VERSION "AEE2010_4.35_HS2"

NS_ :

BS_:

BU_: AVAS RITCS PASS_HCU2 BVN EBB PASS_VCU BSI AAS PASS_BSI FAMILLE_DSG BV CAPT_ALG CAPT_VOL CMM CSS FSE OUTIL_DIAG PROJ SBW SCDT SUSP UC_DIRA UC_FREIN ASR ARTIV PASS_BSM CMF HCU1 HCU2 ECR MCM

BO_ 146 HS2_INTE_ELECTRON_BSI_092: 1 BSI
 SG_ EFFAC_DEFAUT_DIAG : 0|1@0+ (1,0) [0|0] ""  BVN,ARTIV,EBB,AVAS
 SG_ DIAG_INTEGRA_ELEC : 7|1@0+ (1,0) [0|0] ""  BVN,ARTIV,EBB,AVAS
 SG_ MODE_DIAG : 6|1@0+ (1,0) [0|0] ""  BVN,ARTIV,EBB,AVAS

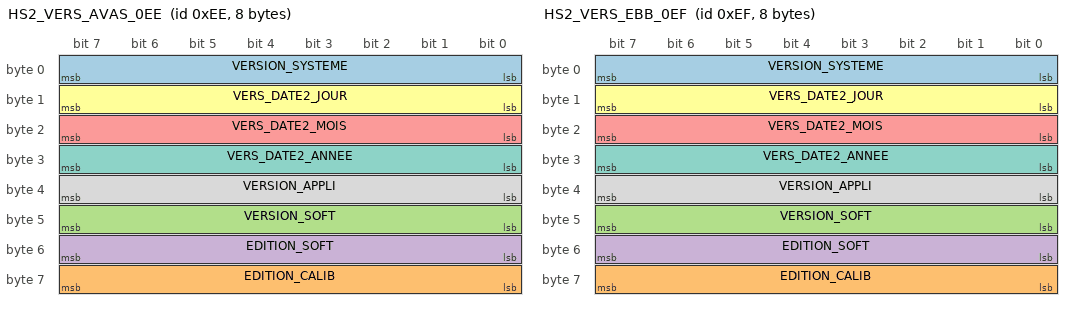
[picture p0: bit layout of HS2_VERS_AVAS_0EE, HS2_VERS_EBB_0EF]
BO_ 238 HS2_VERS_AVAS_0EE: 8 AVAS
 SG_ VERSION_SYSTEME : 7|8@0+ (1,0) [0|255] "" Vector__XXX
 SG_ EDITION_CALIB : 63|8@0+ (1,0) [0|255] "" Vector__XXX
 SG_ VERSION_SOFT : 47|8@0+ (1,0) [0|255] "" Vector__XXX
 SG_ EDITION_SOFT : 55|8@0+ (1,0) [0|255] "" Vector__XXX
 SG_ VERS_DATE2_MOIS : 23|8@0+ (1,0) [0|12] "" Vector__XXX
 SG_ VERS_DATE2_JOUR : 15|8@0+ (1,0) [0|31] "" Vector__XXX
 SG_ VERS_DATE2_ANNEE : 31|8@0+ (1,0) [0|99] "" Vector__XXX
 SG_ VERSION_APPLI : 39|8@0+ (1,0) [0|255] "" Vector__XXX

BO_ 239 HS2_VERS_EBB_0EF: 8 EBB
 SG_ VERSION_SYSTEME : 7|8@0+ (1,0) [0|255] "" Vector__XXX
 SG_ EDITION_CALIB : 63|8@0+ (1,0) [0|255] "" Vector__XXX
 SG_ VERSION_SOFT : 47|8@0+ (1,0) [0|255] "" Vector__XXX
 SG_ EDITION_SOFT : 55|8@0+ (1,0) [0|255] "" Vector__XXX
 SG_ VERS_DATE2_MOIS : 23|8@0+ (1,0) [0|12] "" Vector__XXX
 SG_ VERS_DATE2_JOUR : 15|8@0+ (1,0) [0|31] "" Vector__XXX
 SG_ VERS_DATE2_ANNEE : 31|8@0+ (1,0) [0|99] "" Vector__XXX
 SG_ VERSION_APPLI : 39|8@0+ (1,0) [0|255] "" Vector__XXX

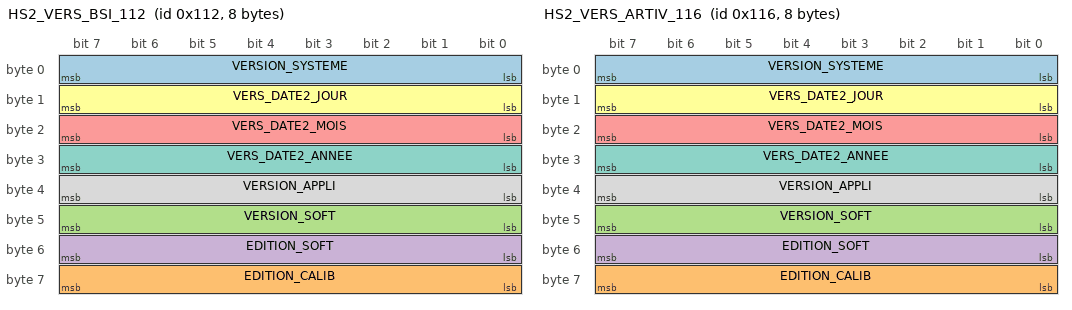
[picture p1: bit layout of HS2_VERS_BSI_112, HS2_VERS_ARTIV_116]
BO_ 274 HS2_VERS_BSI_112: 8 BSI
 SG_ VERSION_SYSTEME : 7|8@0+ (1,0) [0|255] "" Vector__XXX
 SG_ EDITION_CALIB : 63|8@0+ (1,0) [0|255] "" Vector__XXX
 SG_ VERSION_SOFT : 47|8@0+ (1,0) [0|255] "" Vector__XXX
 SG_ EDITION_SOFT : 55|8@0+ (1,0) [0|255] "" Vector__XXX
 SG_ VERS_DATE2_MOIS : 23|8@0+ (1,0) [0|12] "" Vector__XXX
 SG_ VERS_DATE2_JOUR : 15|8@0+ (1,0) [0|31] "" Vector__XXX
 SG_ VERS_DATE2_ANNEE : 31|8@0+ (1,0) [0|99] "" Vector__XXX
 SG_ VERSION_APPLI : 39|8@0+ (1,0) [0|255] "" Vector__XXX

BO_ 278 HS2_VERS_ARTIV_116: 8 ARTIV
 SG_ VERSION_SYSTEME : 7|8@0+ (1,0) [0|255] "" Vector__XXX
 SG_ EDITION_CALIB : 63|8@0+ (1,0) [0|255] "" Vector__XXX
 SG_ VERSION_SOFT : 47|8@0+ (1,0) [0|255] "" Vector__XXX
 SG_ EDITION_SOFT : 55|8@0+ (1,0) [0|255] "" Vector__XXX
 SG_ VERS_DATE2_MOIS : 23|8@0+ (1,0) [0|12] "" Vector__XXX
 SG_ VERS_DATE2_JOUR : 15|8@0+ (1,0) [0|31] "" Vector__XXX
 SG_ VERS_DATE2_ANNEE : 31|8@0+ (1,0) [0|99] "" Vector__XXX
 SG_ VERSION_APPLI : 39|8@0+ (1,0) [0|255] "" Vector__XXX

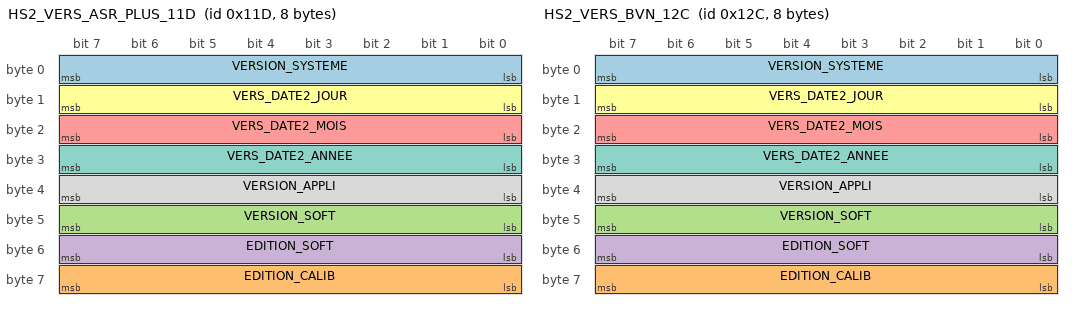
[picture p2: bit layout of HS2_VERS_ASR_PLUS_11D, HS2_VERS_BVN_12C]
BO_ 285 HS2_VERS_ASR_PLUS_11D: 8 MCM
 SG_ VERSION_SYSTEME : 7|8@0+ (1,0) [0|255] "" Vector__XXX
 SG_ EDITION_CALIB : 63|8@0+ (1,0) [0|255] "" Vector__XXX
 SG_ VERSION_SOFT : 47|8@0+ (1,0) [0|255] "" Vector__XXX
 SG_ EDITION_SOFT : 55|8@0+ (1,0) [0|255] "" Vector__XXX
 SG_ VERS_DATE2_MOIS : 23|8@0+ (1,0) [0|12] "" Vector__XXX
 SG_ VERS_DATE2_JOUR : 15|8@0+ (1,0) [0|31] "" Vector__XXX
 SG_ VERS_DATE2_ANNEE : 31|8@0+ (1,0) [0|99] "" Vector__XXX
 SG_ VERSION_APPLI : 39|8@0+ (1,0) [0|255] "" Vector__XXX

BO_ 300 HS2_VERS_BVN_12C: 8 BVN
 SG_ VERSION_SYSTEME : 7|8@0+ (1,0) [0|255] "" Vector__XXX
 SG_ EDITION_CALIB : 63|8@0+ (1,0) [0|255] "" Vector__XXX
 SG_ VERSION_SOFT : 47|8@0+ (1,0) [0|255] "" Vector__XXX
 SG_ EDITION_SOFT : 55|8@0+ (1,0) [0|255] "" Vector__XXX
 SG_ VERS_DATE2_MOIS : 23|8@0+ (1,0) [0|12] "" Vector__XXX
 SG_ VERS_DATE2_JOUR : 15|8@0+ (1,0) [0|31] "" Vector__XXX
 SG_ VERS_DATE2_ANNEE : 31|8@0+ (1,0) [0|99] "" Vector__XXX
 SG_ VERSION_APPLI : 39|8@0+ (1,0) [0|255] "" Vector__XXX

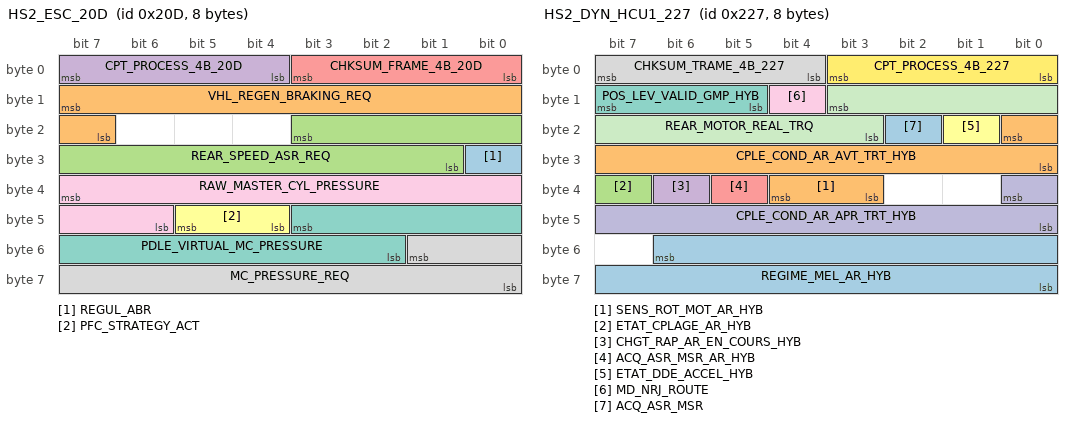
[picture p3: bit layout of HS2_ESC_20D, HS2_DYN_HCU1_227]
BO_ 525 HS2_ESC_20D: 8 UC_FREIN
 SG_ REGUL_ABR : 24|1@0+ (1,0) [0|0] ""  EBB,CMM
 SG_ VHL_REGEN_BRAKING_REQ : 15|9@0+ (1,-2500) [-2500|0] "N.m"  EBB,CMM
 SG_ REAR_SPEED_ASR_REQ : 19|11@0+ (1,10) [0|18000] "tr/min"  EBB,CMM
 SG_ CPT_PROCESS_4B_20D : 7|4@0+ (1,0) [0|15] ""  EBB,CMM
 SG_ CHKSUM_FRAME_4B_20D : 3|4@0+ (1,0) [0|0] ""  EBB,CMM
 SG_ PFC_STRATEGY_ACT : 45|2@0+ (1,0) [0|0] ""  EBB,CMM
 SG_ PDLE_VIRTUAL_MC_PRESSURE : 43|10@0+ (0.25,0) [0|250] "bar"  EBB,CMM
 SG_ MC_PRESSURE_REQ : 49|10@0+ (0.25,0) [0|250] "bar"  EBB,CMM
 SG_ RAW_MASTER_CYL_PRESSURE : 39|10@0+ (0.3,-30) [-30|276.3] "bar"  EBB,CMM

BO_ 551 HS2_DYN_HCU1_227: 8 PASS_HCU2
 SG_ REGIME_MEL_AR_HYB : 54|15@0+ (1,-16000) [-16000|16000] "tr/min"  BSI,UC_FREIN
 SG_ SENS_ROT_MOT_AR_HYB : 36|2@0+ (1,0) [0|0] ""  BSI,UC_FREIN
 SG_ ETAT_CPLAGE_AR_HYB : 39|1@0+ (1,0) [0|0] ""  BSI,UC_FREIN
 SG_ CHGT_RAP_AR_EN_COURS_HYB : 38|1@0+ (1,0) [0|0] ""  BSI,UC_FREIN
 SG_ ACQ_ASR_MSR_AR_HYB : 37|1@0+ (1,0) [0|0] ""  BSI,UC_FREIN
 SG_ ETAT_DDE_ACCEL_HYB : 17|1@0+ (1,0) [0|0] ""  BSI,UC_FREIN
 SG_ POS_LEV_VALID_GMP_HYB : 15|3@0+ (1,0) [0|0] ""  BSI,UC_FREIN
 SG_ CHKSUM_TRAME_4B_227 : 7|4@0+ (1,0) [0|0] ""  BSI,UC_FREIN
 SG_ MD_NRJ_ROUTE : 12|1@0+ (1,0) [0|0] ""  BSI,UC_FREIN
 SG_ CPLE_COND_AR_APR_TRT_HYB : 32|9@0+ (2,-500) [-500|500] "N.m"  BSI,UC_FREIN
 SG_ REAR_MOTOR_REAL_TRQ : 11|9@0- (2,0) [-250|250] "N.m"  BSI,UC_FREIN
 SG_ CPT_PROCESS_4B_227 : 3|4@0+ (1,0) [0|15] ""  BSI,UC_FREIN
 SG_ ACQ_ASR_MSR : 18|1@0+ (1,0) [0|0] ""  BSI,UC_FREIN
 SG_ CPLE_COND_AR_AVT_TRT_HYB : 16|9@0+ (2,-500) [-500|500] "N.m"  BSI,UC_FREIN

BO_ 552 HS2_BGE_DYN5_CMM_228: 8 PASS_BSI
 SG_ PRESS_MASTERV_2_HYB : 47|8@0+ (5,0) [0|1200] "hPa"  CMF,RITCS,UC_FREIN,BV,ARTIV,HCU2
 SG_ IND_ENG_SPD_OVRFLWD : 10|2@0+ (1,0) [0|0] ""  CMF,RITCS,UC_FREIN,BV,ARTIV,HCU2
 SG_ POS_PDLE_EMBR_CMM : 39|8@0+ (0.5,0) [0|100] "%"  CMF,RITCS,UC_FREIN,BV,ARTIV,HCU2
 SG_ POINT_DUR_SECU : 11|1@0+ (1,0) [0|0] ""  CMF,RITCS,UC_FREIN,BV,ARTIV,HCU2
 SG_ CPLE_DISPO_HILL_ASSIST : 12|1@0+ (1,0) [0|0] ""  CMF,RITCS,UC_FREIN,BV,ARTIV,HCU2
 SG_ CHKSUM_TRME_DYN5_CMM : 27|4@0+ (1,0) [0|0] ""  CMF,RITCS,UC_FREIN,BV,ARTIV,HCU2
 SG_ CPLE_MOT_PRECIS : 13|1@0+ (1,0) [0|0] ""  CMF,RITCS,UC_FREIN,BV,ARTIV,HCU2
 SG_ PRESS_MASTER_REL_CMM : 47|8@0+ (5,0) [0|1200] "hPa"  CMF,RITCS,UC_FREIN,BV,ARTIV,HCU2
 SG_ FREEWHEELING_REQ : 55|2@0+ (1,0) [0|0] ""  CMF,RITCS,UC_FREIN,BV,ARTIV,HCU2
 SG_ CPLE_EM_INCERTAIN : 15|2@0+ (1,0) [0|0] ""  CMF,RITCS,UC_FREIN,BV,ARTIV,HCU2
 SG_ EFCMNT_PDLE_ACCEL : 23|8@0+ (0.5,0) [0|100] "%"  CMF,RITCS,UC_FREIN,BV,ARTIV,HCU2
 SG_ CPT_PROCESS_4B_228 : 31|4@0+ (1,0) [0|15] ""  CMF,RITCS,UC_FREIN,BV,ARTIV,HCU2
 SG_ AUTORISATION_RDT : 53|1@0+ (1,0) [0|0] ""  CMF,RITCS,UC_FREIN,BV,ARTIV,HCU2
 SG_ CPLE_POT_MAX_INST : 63|8@0+ (2,-100) [-100|408] "N.m"  CMF,RITCS,UC_FREIN,BV,ARTIV,HCU2
 SG_ INFO_CPLE_EASY_MOVE : 7|8@0+ (2,-100) [-100|408] "N.m"  CMF,RITCS,UC_FREIN,BV,ARTIV,HCU2

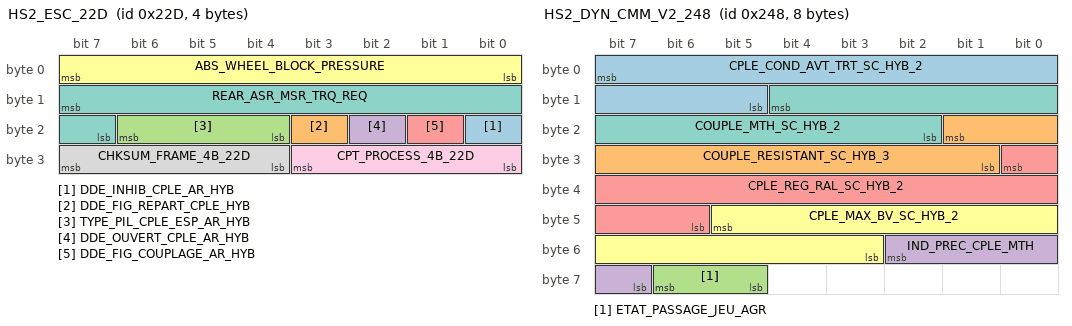
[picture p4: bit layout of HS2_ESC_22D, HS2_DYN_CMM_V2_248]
BO_ 557 HS2_ESC_22D: 4 UC_FREIN
 SG_ DDE_INHIB_CPLE_AR_HYB : 16|1@0+ (1,0) [0|0] ""  CMM,EBB
 SG_ DDE_FIG_REPART_CPLE_HYB : 19|1@0+ (1,0) [0|0] ""  CMM,EBB
 SG_ TYPE_PIL_CPLE_ESP_AR_HYB : 22|3@0+ (1,0) [0|0] ""  CMM,EBB
 SG_ DDE_OUVERT_CPLE_AR_HYB : 18|1@0+ (1,0) [0|0] ""  CMM,EBB
 SG_ DDE_FIG_COUPLAGE_AR_HYB : 17|1@0+ (1,0) [0|0] ""  CMM,EBB
 SG_ ABS_WHEEL_BLOCK_PRESSURE : 7|8@0+ (1,0) [0|250] "bar"  CMM,EBB
 SG_ REAR_ASR_MSR_TRQ_REQ : 15|9@0+ (1,-250) [-250|250] "N.m"  CMM,EBB
 SG_ CHKSUM_FRAME_4B_22D : 31|4@0+ (1,0) [0|0] ""  CMM,EBB
 SG_ CPT_PROCESS_4B_22D : 27|4@0+ (1,0) [0|15] ""  CMM,EBB

BO_ 584 HS2_DYN_CMM_V2_248: 8 CMM
 SG_ CPLE_COND_AVT_TRT_SC_HYB_2 : 7|11@0+ (0.5,-500) [-500|500] "N.m"  UC_FREIN
 SG_ COUPLE_RESISTANT_SC_HYB_3 : 17|9@0+ (0.5,0) [0|255] "N.m"  UC_FREIN
 SG_ ETAT_PASSAGE_JEU_AGR : 62|2@0+ (1,0) [0|0] ""  UC_FREIN
 SG_ IND_PREC_CPLE_MTH : 50|4@0+ (1,0) [1|10] "Sans unité"  UC_FREIN
 SG_ CPLE_REG_RAL_SC_HYB_2 : 24|11@0+ (0.5,-500) [-500|500] "N.m"  UC_FREIN
 SG_ CPLE_MAX_BV_SC_HYB_2 : 45|11@0+ (0.5,-500) [-500|500] "N.m"  UC_FREIN
 SG_ COUPLE_MTH_SC_HYB_2 : 12|11@0+ (0.5,-500) [-500|500] "N.m"  UC_FREIN

BO_ 632 HS2_DYN_CMM_278: 4 CMM
 SG_ CPT_PROCESS_4B_278 : 3|4@0+ (1,0) [0|15] ""  UC_FREIN
 SG_ CHKSUM_TRAME_4B_278 : 7|4@0+ (1,0) [0|0] ""  UC_FREIN
 SG_ FRONT_PWT_REAL_TRQ : 23|9@0- (2,0) [-400|400] "N.m"  UC_FREIN
 SG_ CPLE_REEL_AR_HYB_2 : 15|8@0+ (2,-250) [-250|250] "N.m"  UC_FREIN

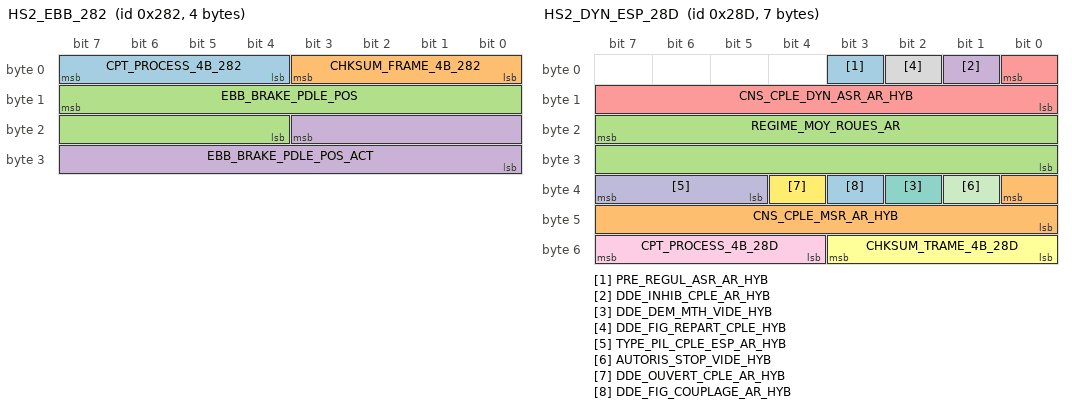
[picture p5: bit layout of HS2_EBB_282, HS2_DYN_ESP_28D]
BO_ 642 HS2_EBB_282: 4 EBB
 SG_ CPT_PROCESS_4B_282 : 7|4@0+ (1,0) [0|15] ""  UC_FREIN
 SG_ CHKSUM_FRAME_4B_282 : 3|4@0+ (1,0) [0|0] ""  UC_FREIN
 SG_ EBB_BRAKE_PDLE_POS : 15|12@0+ (0.015625,-5) [-5|47] "mm"  UC_FREIN
 SG_ EBB_BRAKE_PDLE_POS_ACT : 19|12@0+ (0.015625,-5) [-5|47] "mm"  UC_FREIN

BO_ 653 HS2_DYN_ESP_28D: 7 UC_FREIN
 SG_ PRE_REGUL_ASR_AR_HYB : 3|1@0+ (1,0) [0|0] ""  BSI,HCU2
 SG_ CNS_CPLE_MSR_AR_HYB : 32|9@0+ (2,-500) [-500|500] "N.m"  BSI,HCU2
 SG_ REGIME_MOY_ROUES_AR : 23|16@0+ (0.04,0) [0|2621] "tr/min"  BSI,HCU2
 SG_ DDE_INHIB_CPLE_AR_HYB : 1|1@0+ (1,0) [0|0] ""  BSI,HCU2
 SG_ CNS_CPLE_DYN_ASR_AR_HYB : 0|9@0+ (2,-500) [-500|500] "N.m"  BSI,HCU2
 SG_ CHKSUM_TRAME_4B_28D : 51|4@0+ (1,0) [0|0] ""  BSI,HCU2
 SG_ DDE_DEM_MTH_VIDE_HYB : 34|1@0+ (1,0) [0|0] ""  BSI,HCU2
 SG_ DDE_FIG_REPART_CPLE_HYB : 2|1@0+ (1,0) [0|0] ""  BSI,HCU2
 SG_ CPT_PROCESS_4B_28D : 55|4@0+ (1,0) [0|15] ""  BSI,HCU2
 SG_ TYPE_PIL_CPLE_ESP_AR_HYB : 39|3@0+ (1,0) [0|0] ""  BSI,HCU2
 SG_ AUTORIS_STOP_VIDE_HYB : 33|1@0+ (1,0) [0|0] ""  BSI,HCU2
 SG_ DDE_OUVERT_CPLE_AR_HYB : 36|1@0+ (1,0) [0|0] ""  BSI,HCU2
 SG_ DDE_FIG_COUPLAGE_AR_HYB : 35|1@0+ (1,0) [0|0] ""  BSI,HCU2

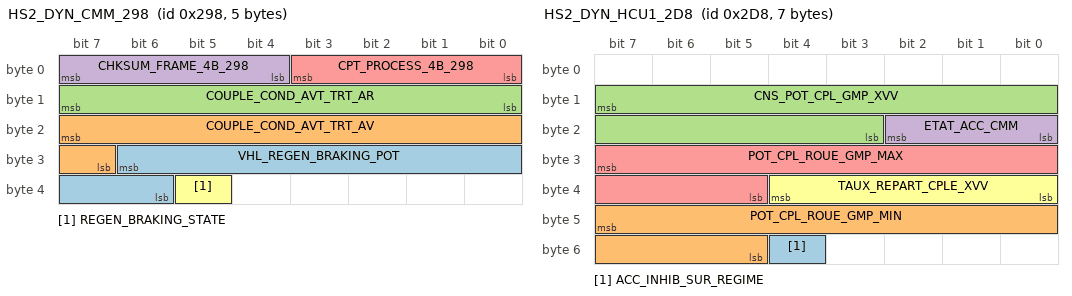
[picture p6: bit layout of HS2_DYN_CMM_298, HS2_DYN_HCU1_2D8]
BO_ 664 HS2_DYN_CMM_298: 5 CMM
 SG_ VHL_REGEN_BRAKING_POT : 30|9@0+ (5,-2500) [-2500|0] "N.m"  UC_FREIN
 SG_ COUPLE_COND_AVT_TRT_AV : 23|9@0+ (2,-400) [-400|400] "N.m"  UC_FREIN
 SG_ COUPLE_COND_AVT_TRT_AR : 15|8@0+ (2,-250) [-250|250] "N.m"  UC_FREIN
 SG_ CHKSUM_FRAME_4B_298 : 7|4@0+ (1,0) [0|0] ""  UC_FREIN
 SG_ CPT_PROCESS_4B_298 : 3|4@0+ (1,0) [0|15] ""  UC_FREIN
 SG_ REGEN_BRAKING_STATE : 37|1@0+ (1,0) [0|0] ""  UC_FREIN

BO_ 690 HS2_DYN2_CMM_2B2: 1 BSI
 SG_ DIAG_MUX_ON : 1|1@0+ (1,0) [0|0] ""  BVN,ARTIV,CAPT_VOL,ECR,CMF,AVAS
 SG_ ETAT_RVV_LVV : 3|2@0+ (1,0) [0|0] ""  BVN,ARTIV,CAPT_VOL,ECR,CMF,AVAS
 SG_ ETAT_MT : 7|4@0+ (1,0) [0|0] ""  BVN,ARTIV,CAPT_VOL,ECR,CMF,AVAS

BO_ 694 HS2_DYN1_MDD_ETAT_2B6: 8 ARTIV
 SG_ DMD_PLT_DECEL_MDD : 53|1@0+ (1,0) [0|0] ""  CMM,UC_FREIN,BSI,PASS_HCU2,CMF
 SG_ TYPE_DECEL_MDD : 52|2@0+ (1,0) [0|0] ""  CMM,UC_FREIN,BSI,PASS_HCU2,CMF
 SG_ CNS_CPLE_ROUE_GMP : 39|14@0+ (1,-4000) [-4000|11000] "N.m"  CMM,UC_FREIN,BSI,PASS_HCU2,CMF
 SG_ DDE_ACT_CPL_ROUE : 41|2@0+ (1,0) [0|0] ""  CMM,UC_FREIN,BSI,PASS_HCU2,CMF
 SG_ CONS_DECEL_MDD : 7|8@0+ (0.05,-10.65) [-10.65|2] "m/s2"  CMM,UC_FREIN,BSI,PASS_HCU2,CMF
 SG_ DDE_PREFILL : 55|1@0+ (1,0) [0|0] ""  CMM,UC_FREIN,BSI,PASS_HCU2,CMF
 SG_ TYPE_RAPPORT M : 54|1@0+ (1,0) [0|0] ""  CMM,UC_FREIN,BSI,PASS_HCU2,CMF
 SG_ CNS_POT_CPL_ROUE_GMP : 23|12@0+ (4,-4000) [-4000|11000] "N.m"  CMM,UC_FREIN,BSI,PASS_HCU2,CMF
 SG_ ETAT_ACC : 27|4@0+ (1,0) [0|0] ""  CMM,UC_FREIN,BSI,PASS_HCU2,CMF
 SG_ TPS_CONF_MIN_RAP_DES m0 : 15|6@0+ (0.1,0) [0|6.2] "s"  CMM,UC_FREIN,BSI,PASS_HCU2,CMF
 SG_ TPS_CONF_MIN_RAP_MON m1 : 15|6@0+ (0.1,0) [0|6.2] "s"  CMM,UC_FREIN,BSI,PASS_HCU2,CMF
 SG_ DDE_ACT_POT_CPL_ROUE : 9|2@0+ (1,0) [0|0] ""  CMM,UC_FREIN,BSI,PASS_HCU2,CMF
 SG_ FA_ETAT_FA : 50|3@0+ (1,0) [0|0] ""  CMM,UC_FREIN,BSI,PASS_HCU2,CMF
 SG_ CPT_PROCESS_4B_ACC : 63|4@0+ (1,0) [0|15] ""  CMM,UC_FREIN,BSI,PASS_HCU2,CMF
 SG_ CHKSUM_TRME_DYN_ACC : 59|4@0+ (1,0) [0|0] ""  CMM,UC_FREIN,BSI,PASS_HCU2,CMF

BO_ 696 HS2_DYN_CMM_2B8: 1 CMM
 SG_ CPLE_MINI : 7|8@0+ (2,-100) [-100|408] "N.m"  UC_FREIN,BV

BO_ 717 HS2_DYN_UCF_2CD: 3 UC_FREIN
 SG_ AUTO_BRAKING_PRESSURE : 7|8@0+ (0.2,0) [0|50.6] "bar"  BV,BVN
 SG_ VITESSE_LACET : 15|16@0- (0.1,0) [-100|100] "Degré/s"  BV,BVN

BO_ 728 HS2_DYN_HCU1_2D8: 7 PASS_HCU2
 SG_ ACC_INHIB_SUR_REGIME : 52|1@0+ (1,0) [0|0] ""  ARTIV
 SG_ POT_CPL_ROUE_GMP_MIN : 47|11@0+ (8,-4000) [-4000|11000] "N.m"  ARTIV
 SG_ CNS_POT_CPL_GMP_XVV : 15|13@0+ (2,-4000) [-4000|11000] "N.m"  ARTIV
 SG_ ETAT_ACC_CMM : 18|3@0+ (1,0) [0|0] ""  ARTIV
 SG_ POT_CPL_ROUE_GMP_MAX : 31|11@0+ (8,-4000) [-4000|11000] "N.m"  ARTIV
 SG_ TAUX_REPART_CPLE_XVV : 36|5@0+ (5,0) [0|100] "%"  ARTIV

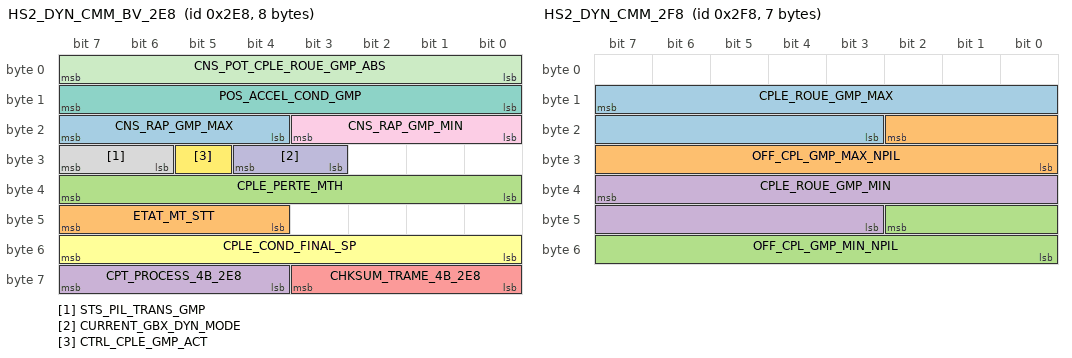
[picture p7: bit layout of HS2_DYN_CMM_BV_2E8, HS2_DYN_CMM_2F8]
BO_ 744 HS2_DYN_CMM_BV_2E8: 8 CMM
 SG_ CNS_RAP_GMP_MAX : 23|4@0+ (1,0) [0|0] ""  BV
 SG_ ETAT_MT_STT : 47|4@0+ (1,0) [0|0] ""  BV
 SG_ CPLE_PERTE_MTH : 39|8@0+ (2,-100) [-100|408] "N.m"  BV
 SG_ CPT_PROCESS_4B_2E8 : 63|4@0+ (1,0) [0|15] ""  BV
 SG_ CHKSUM_TRAME_4B_2E8 : 59|4@0+ (1,0) [0|0] ""  BV
 SG_ CPLE_COND_FINAL_SP : 55|8@0+ (2,-100) [-100|408] ""  BV
 SG_ POS_ACCEL_COND_GMP : 15|8@0+ (0.5,0) [0|100] "%"  BV
 SG_ STS_PIL_TRANS_GMP : 31|2@0+ (1,0) [0|0] ""  BV
 SG_ CNS_RAP_GMP_MIN : 19|4@0+ (1,0) [0|0] ""  BV
 SG_ CURRENT_GBX_DYN_MODE : 28|2@0+ (1,0) [0|0] ""  BV
 SG_ CNS_POT_CPLE_ROUE_GMP_ABS : 7|8@0+ (20,-1000) [-1000|4000] "N.m"  BV
 SG_ CTRL_CPLE_GMP_ACT : 29|1@0+ (1,0) [0|0] ""  BV

BO_ 758 HS2_DYN_MDD_ETAT_2F6: 8 ARTIV
 SG_ DIST_INTER_VHL : 15|10@0+ (0.25,0) [0|255.5] "m"  BSI,CMM,UC_FREIN,CMF
 SG_ DMD_ALRT_COL_VISU_ARC : 5|1@0+ (1,0) [0|0] ""  BSI,CMM,UC_FREIN,CMF
 SG_ ARC_ETAT_ARC : 19|4@0+ (1,0) [0|0] ""  BSI,CMM,UC_FREIN,CMF
 SG_ AEB_ENABLED : 21|1@0+ (1,0) [0|0] ""  BSI,CMM,UC_FREIN,CMF
 SG_ DMD_PLT_DECEL_MDD : 42|1@0+ (1,0) [0|0] ""  BSI,CMM,UC_FREIN,CMF
 SG_ DDE_REPRISE_COND : 2|2@0+ (1,0) [0|0] ""  BSI,CMM,UC_FREIN,CMF
 SG_ TEMPS_INTER_VHL_AFF : 39|6@0+ (0.1,0) [0|6.1] "s"  BSI,CMM,UC_FREIN,CMF
 SG_ CIBLE_DETECTEE : 0|1@0+ (1,0) [0|0] ""  BSI,CMM,UC_FREIN,CMF
 SG_ DMD_ALRT_COL_SON_ARC : 6|1@0+ (1,0) [0|0] ""  BSI,CMM,UC_FREIN,CMF
 SG_ DMD_ALRT_COL_HAPT_ARC : 7|1@0+ (1,0) [0|0] ""  BSI,CMM,UC_FREIN,CMF
 SG_ CAPT_AVEUGLE : 4|1@0+ (1,0) [0|0] ""  BSI,CMM,UC_FREIN,CMF
 SG_ DRV_AWAY_REQ : 33|1@0+ (1,0) [0|0] ""  BSI,CMM,UC_FREIN,CMF
 SG_ FA_ETAT_FA : 47|3@0+ (1,0) [0|0] ""  BSI,CMM,UC_FREIN,CMF
 SG_ FA_INFO_FRN_EN_COURS : 20|1@0+ (1,0) [0|0] ""  BSI,CMM,UC_FREIN,CMF
 SG_ CPT_PROCESS_4B_ACC2 : 55|4@0+ (1,0) [0|15] ""  BSI,CMM,UC_FREIN,CMF
 SG_ CHKSUM_TRME_DYN_ACC2 : 51|4@0+ (1,0) [0|0] ""  BSI,CMM,UC_FREIN,CMF
 SG_ TARGET_POSITION : 63|3@0+ (1,0) [0|0] ""  BSI,CMM,UC_FREIN,CMF

BO_ 760 HS2_DYN_CMM_2F8: 7 CMM
 SG_ CPLE_ROUE_GMP_MAX : 15|13@0+ (2,-4000) [-4000|11000] "N.m"  CMF,ARTIV,UC_FREIN
 SG_ OFF_CPL_GMP_MAX_NPIL : 18|11@0+ (2,0) [0|4000] "N.m"  CMF,ARTIV,UC_FREIN
 SG_ OFF_CPL_GMP_MIN_NPIL : 42|11@0+ (2,0) [0|4000] "N.m"  CMF,ARTIV,UC_FREIN
 SG_ CPLE_ROUE_GMP_MIN : 39|13@0+ (2,-4000) [-4000|11000] "N.m"  CMF,ARTIV,UC_FREIN

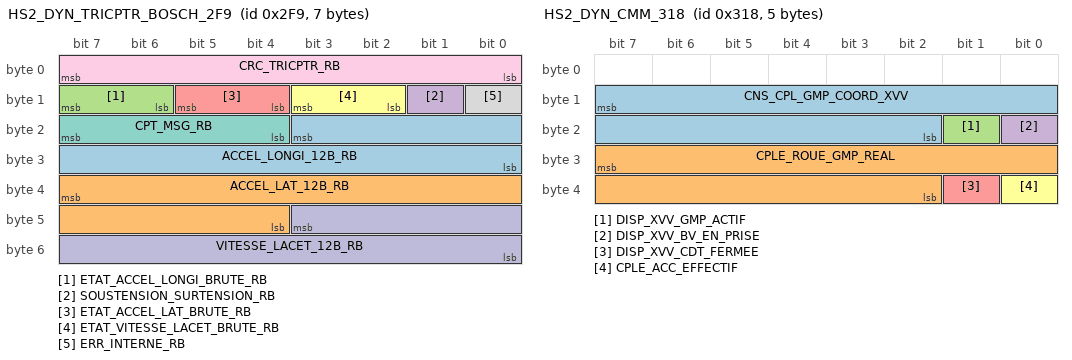
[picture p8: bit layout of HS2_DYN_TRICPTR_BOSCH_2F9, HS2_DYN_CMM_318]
BO_ 761 HS2_DYN_TRICPTR_BOSCH_2F9: 7 CAPT_ALG
 SG_ ACCEL_LONGI_12B_RB : 19|12@0+ (0.02,-40.96) [-40.96|40.92] "m/s2"  RITCS,UC_FREIN
 SG_ ACCEL_LAT_12B_RB : 39|12@0+ (0.02,-40.96) [-40.96|40.92] "m/s2"  RITCS,UC_FREIN
 SG_ ETAT_ACCEL_LONGI_BRUTE_RB : 15|2@0+ (1,0) [0|0] ""  RITCS,UC_FREIN
 SG_ SOUSTENSION_SURTENSION_RB : 9|1@0+ (1,0) [0|0] ""  RITCS,UC_FREIN
 SG_ ETAT_ACCEL_LAT_BRUTE_RB : 13|2@0+ (1,0) [0|0] ""  RITCS,UC_FREIN
 SG_ ETAT_VITESSE_LACET_BRUTE_RB : 11|2@0+ (1,0) [0|0] ""  RITCS,UC_FREIN
 SG_ CPT_MSG_RB : 23|4@0+ (1,0) [0|15] ""  RITCS,UC_FREIN
 SG_ ERR_INTERNE_RB : 8|1@0+ (1,0) [0|0] ""  RITCS,UC_FREIN
 SG_ CRC_TRICPTR_RB : 7|8@0+ (1,0) [0|255] ""  RITCS,UC_FREIN
 SG_ VITESSE_LACET_12B_RB : 43|12@0+ (0.08,-163.84) [-163.84|163.68] "Degré/s"  RITCS,UC_FREIN

BO_ 792 HS2_DYN_CMM_318: 5 CMM
 SG_ CNS_CPL_GMP_COORD_XVV : 15|14@0+ (1,-4000) [-4000|11000] "N.m"  CMF,ARTIV,UC_FREIN
 SG_ CPLE_ROUE_GMP_REAL : 31|14@0+ (1,-4000) [-4000|11000] "N.m"  CMF,ARTIV,UC_FREIN
 SG_ DISP_XVV_GMP_ACTIF : 17|1@0+ (1,0) [0|0] ""  CMF,ARTIV,UC_FREIN
 SG_ DISP_XVV_BV_EN_PRISE : 16|1@0+ (1,0) [0|0] ""  CMF,ARTIV,UC_FREIN
 SG_ DISP_XVV_CDT_FERMEE : 33|1@0+ (1,0) [0|0] ""  CMF,ARTIV,UC_FREIN
 SG_ CPLE_ACC_EFFECTIF : 32|1@0+ (1,0) [0|0] ""  CMF,ARTIV,UC_FREIN

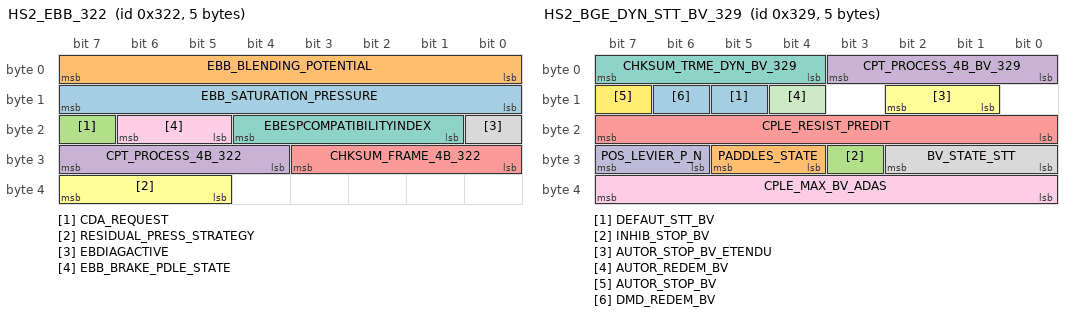
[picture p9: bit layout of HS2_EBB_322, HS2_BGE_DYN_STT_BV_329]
BO_ 802 HS2_EBB_322: 5 EBB
 SG_ EBB_SATURATION_PRESSURE : 15|8@0+ (1,0) [0|250] "bar"  UC_FREIN
 SG_ EBB_BLENDING_POTENTIAL : 7|8@0+ (0.5,0) [0|125] "bar"  UC_FREIN
 SG_ CDA_REQUEST : 23|1@0+ (1,0) [0|0] ""  UC_FREIN
 SG_ CPT_PROCESS_4B_322 : 31|4@0+ (1,0) [0|15] ""  UC_FREIN
 SG_ CHKSUM_FRAME_4B_322 : 27|4@0+ (1,0) [0|0] ""  UC_FREIN
 SG_ RESIDUAL_PRESS_STRATEGY : 39|3@0+ (1,0) [0|0] ""  UC_FREIN
 SG_ EBESPCOMPATIBILITYINDEX : 20|4@0+ (1,0) [0|15] "Sans unité"  UC_FREIN
 SG_ EBDIAGACTIVE : 16|1@0+ (1,0) [0|0] ""  UC_FREIN
 SG_ EBB_BRAKE_PDLE_STATE : 22|2@0+ (1,0) [0|0] ""  UC_FREIN

BO_ 809 HS2_BGE_DYN_STT_BV_329: 5 BV
 SG_ DEFAUT_STT_BV : 13|1@0+ (1,0) [0|0] ""  PASS_BSI
 SG_ PADDLES_STATE : 29|2@0+ (1,0) [0|0] ""  PASS_BSI
 SG_ INHIB_STOP_BV : 27|1@0+ (1,0) [0|0] ""  PASS_BSI
 SG_ CPT_PROCESS_4B_BV_329 : 3|4@0+ (1,0) [0|15] ""  PASS_BSI
 SG_ CPLE_RESIST_PREDIT : 23|8@0+ (1,0) [0|200] "N.m"  PASS_BSI
 SG_ AUTOR_STOP_BV_ETENDU : 10|2@0+ (1,0) [0|0] ""  PASS_BSI
 SG_ CHKSUM_TRME_DYN_BV_329 : 7|4@0+ (1,0) [0|0] ""  PASS_BSI
 SG_ BV_STATE_STT : 26|3@0+ (1,0) [0|0] ""  PASS_BSI
 SG_ CPLE_MAX_BV_ADAS : 39|8@0+ (2,-100) [-100|408] "N.m"  PASS_BSI
 SG_ POS_LEVIER_P_N : 31|2@0+ (1,0) [0|0] ""  PASS_BSI
 SG_ AUTOR_REDEM_BV : 12|1@0+ (1,0) [0|0] ""  PASS_BSI
 SG_ AUTOR_STOP_BV : 15|1@0+ (1,0) [0|0] ""  PASS_BSI
 SG_ DMD_REDEM_BV : 14|1@0+ (1,0) [0|0] ""  PASS_BSI

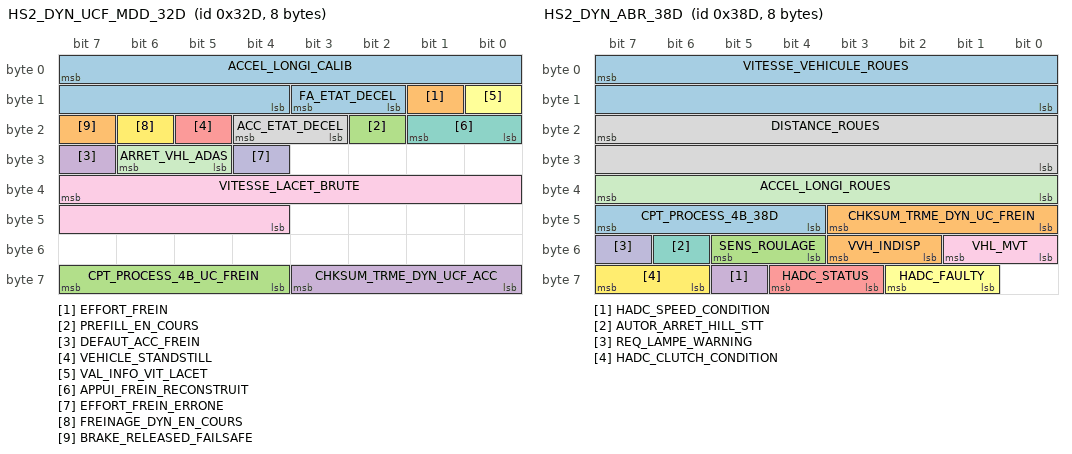
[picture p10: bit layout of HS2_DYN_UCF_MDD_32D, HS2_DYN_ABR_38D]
BO_ 813 HS2_DYN_UCF_MDD_32D: 8 UC_FREIN
 SG_ FA_ETAT_DECEL : 11|2@0+ (1,0) [0|3] ""  CMM,BSI,PASS_HCU2,CMF,ARTIV
 SG_ EFFORT_FREIN : 9|1@0+ (1,0) [0|1] ""  CMM,BSI,PASS_HCU2,CMF,ARTIV
 SG_ PREFILL_EN_COURS : 18|1@0+ (1,0) [0|1] ""  CMM,BSI,PASS_HCU2,CMF,ARTIV
 SG_ DEFAUT_ACC_FREIN : 31|1@0+ (1,0) [0|1] ""  CMM,BSI,PASS_HCU2,CMF,ARTIV
 SG_ VEHICLE_STANDSTILL : 21|1@0+ (1,0) [0|1] ""  CMM,BSI,PASS_HCU2,CMF,ARTIV
 SG_ VAL_INFO_VIT_LACET : 8|1@0+ (1,0) [0|1] ""  CMM,BSI,PASS_HCU2,CMF,ARTIV
 SG_ APPUI_FREIN_RECONSTRUIT : 17|2@0+ (1,0) [0|3] ""  CMM,BSI,PASS_HCU2,CMF,ARTIV
 SG_ ACC_ETAT_DECEL : 20|2@0+ (1,0) [0|3] ""  CMM,BSI,PASS_HCU2,CMF,ARTIV
 SG_ VITESSE_LACET_BRUTE : 39|12@0+ (0.08,-163.84) [-163.84|163.68] "Degré/s"  CMM,BSI,PASS_HCU2,CMF,ARTIV
 SG_ EFFORT_FREIN_ERRONE : 28|1@0+ (1,0) [0|1] ""  CMM,BSI,PASS_HCU2,CMF,ARTIV
 SG_ ARRET_VHL_ADAS : 30|2@0+ (1,0) [0|3] ""  CMM,BSI,PASS_HCU2,CMF,ARTIV
 SG_ FREINAGE_DYN_EN_COURS : 22|1@0+ (1,0) [0|1] ""  CMM,BSI,PASS_HCU2,CMF,ARTIV
 SG_ ACCEL_LONGI_CALIB : 7|12@0+ (0.02,-40.96) [-40.96|40.92] "m/s2"  CMM,BSI,PASS_HCU2,CMF,ARTIV
 SG_ BRAKE_RELEASED_FAILSAFE : 23|1@0+ (1,0) [0|1] ""  CMM,BSI,PASS_HCU2,CMF,ARTIV
 SG_ CPT_PROCESS_4B_UC_FREIN : 63|4@0+ (1,0) [0|15] ""  CMM,BSI,PASS_HCU2,CMF,ARTIV
 SG_ CHKSUM_TRME_DYN_UCF_ACC : 59|4@0+ (1,0) [0|15] ""  CMM,BSI,PASS_HCU2,CMF,ARTIV

BO_ 845 HS2_DYN_CDS_34D: 8 UC_FREIN
 SG_ CHGT_RAP_AUTORISE : 9|2@0+ (1,0) [0|3] ""  ARTIV,ASR
 SG_ FA_ETAT_DECEL : 12|2@0+ (1,0) [0|3] ""  ARTIV,ASR
 SG_ PREFILL_EN_COURS : 10|1@0+ (1,0) [0|1] ""  ARTIV,ASR
 SG_ REGUL_ASR : 50|1@0+ (1,0) [0|1] ""  ARTIV,ASR
 SG_ TYPE_PIL_CPLE_ESP : 2|3@0+ (1,0) [0|7] ""  ARTIV,ASR
 SG_ REGUL_MSR : 51|1@0+ (1,0) [0|1] ""  ARTIV,ASR
 SG_ ETAT_FNCT_HILL_ASSIST : 46|2@0+ (1,0) [0|3] ""  ARTIV,ASR
 SG_ ASR_DECONNECTE : 3|1@0+ (1,0) [0|1] ""  ARTIV,ASR
 SG_ REQ_LAMPE_REGUL_ASR_ESP : 55|1@0+ (1,0) [0|1] ""  ARTIV,ASR
 SG_ REGUL_ESP_SEUL : 52|1@0+ (1,0) [0|1] ""  ARTIV,ASR
 SG_ DDE_LOI_BV_VDC : 5|1@0+ (1,0) [0|1] ""  ARTIV,ASR
 SG_ ETAT_ASR_PLUS : 15|3@0+ (1,0) [0|7] ""  ARTIV,ASR
 SG_ REGUL_AFU : 53|1@0+ (1,0) [0|1] ""  ARTIV,ASR
 SG_ REGUL_BASR : 49|1@0+ (1,0) [0|1] ""  ARTIV,ASR
 SG_ REQ_LAMPE_DEF_ESP : 4|1@0+ (1,0) [0|1] ""  ARTIV,ASR
 SG_ REGUL_ESP : 6|1@0+ (1,0) [0|1] ""  ARTIV,ASR
 SG_ PENTE_STATIQUE : 61|6@0+ (1,-30) [-30|30] "%"  ARTIV,ASR
 SG_ ESP_DECONNECTE : 7|1@0+ (1,0) [0|1] ""  ARTIV,ASR
 SG_ CNS_CPLE_MSR : 39|8@0+ (2,-100) [-100|400] "N.m"  ARTIV,ASR
 SG_ CNS_CPLE_DYN_ASR : 31|8@0+ (2,-100) [-100|400] "N.m"  ARTIV,ASR
 SG_ CNS_CPLE_STAT_ASR : 23|8@0+ (2,-100) [-100|400] "N.m"  ARTIV,ASR
 SG_ CPT_PROCESS_4B_ESP : 43|4@0+ (1,0) [0|15] ""  ARTIV,ASR

BO_ 905 HS2_BGE_DYN_BV_389: 5 BV
 SG_ ACCEL_LONGI : 39|8@0+ (0.08,-14) [-14|6.32] "m/s2"  PASS_BSI
 SG_ DISTANCE : 23|16@0+ (0.1,0) [0|6553.5] "m"  PASS_BSI
 SG_ VITESSE_VEHICULE : 7|16@0+ (0.01,0) [0|655.34] "km/h"  PASS_BSI

BO_ 909 HS2_DYN_ABR_38D: 8 UC_FREIN
 SG_ CPT_PROCESS_4B_38D : 47|4@0+ (1,0) [0|15] ""  CMF,CMM,BV,BSI,HCU1,ARTIV,BVN,AVAS
 SG_ VVH_INDISP : 51|2@0+ (1,0) [0|3] ""  CMF,CMM,BV,BSI,HCU1,ARTIV,BVN,AVAS
 SG_ SENS_ROULAGE : 53|2@0+ (1,0) [0|3] ""  CMF,CMM,BV,BSI,HCU1,ARTIV,BVN,AVAS
 SG_ HADC_SPEED_CONDITION : 61|1@0+ (1,0) [0|1] ""  CMF,CMM,BV,BSI,HCU1,ARTIV,BVN,AVAS
 SG_ HADC_STATUS : 60|2@0+ (1,0) [0|3] ""  CMF,CMM,BV,BSI,HCU1,ARTIV,BVN,AVAS
 SG_ HADC_FAULTY : 58|2@0+ (1,0) [0|3] ""  CMF,CMM,BV,BSI,HCU1,ARTIV,BVN,AVAS
 SG_ AUTOR_ARRET_HILL_STT : 54|1@0+ (1,0) [0|1] ""  CMF,CMM,BV,BSI,HCU1,ARTIV,BVN,AVAS
 SG_ DISTANCE_ROUES : 23|16@0+ (0.1,0) [0|6553.5] "m"  CMF,CMM,BV,BSI,HCU1,ARTIV,BVN,AVAS
 SG_ VHL_MVT : 49|2@0+ (1,0) [0|3] ""  CMF,CMM,BV,BSI,HCU1,ARTIV,BVN,AVAS
 SG_ REQ_LAMPE_WARNING : 55|1@0+ (1,0) [0|1] ""  CMF,CMM,BV,BSI,HCU1,ARTIV,BVN,AVAS
 SG_ ACCEL_LONGI_ROUES : 39|8@0+ (0.08,-14) [-14|6.32] "m/s2"  CMF,CMM,BV,BSI,HCU1,ARTIV,BVN,AVAS
 SG_ HADC_CLUTCH_CONDITION : 63|2@0+ (1,0) [0|3] ""  CMF,CMM,BV,BSI,HCU1,ARTIV,BVN,AVAS
 SG_ VITESSE_VEHICULE_ROUES : 7|16@0+ (0.01,0) [0|655.34] "km/h"  CMF,CMM,BV,BSI,HCU1,ARTIV,BVN,AVAS
 SG_ CHKSUM_TRME_DYN_UC_FREIN : 43|4@0+ (1,0) [0|7] ""  CMF,CMM,BV,BSI,HCU1,ARTIV,BVN,AVAS

BO_ 946 HS2_DYN_BSI_3B2: 2 BSI
 SG_ ASSIETTE_VEHICULE : 7|10@0- (0.006,0) [-3|3] "Degré"  BVN

BO_ 952 HS2_BGE_DYN_CMM_3B8: 8 PASS_BSI
 SG_ CPLMT1_CPL_CND_AP_TR : 47|8@0+ (1,0) [1|255] ""  BV
 SG_ CURRENT_PWT_DYN_CAPABILITY : 59|2@0+ (1,0) [0|3] ""  BV
 SG_ COASTING_STATE : 51|8@0+ (1,0) [0|0] ""  BV
 SG_ COASTING_STATE_SAILING : 51|1@0+ (1,0) [0|1] ""  BV
 SG_ COASTING_STATE_CDT_OPEN : 50|1@0+ (1,0) [0|1] ""  BV
 SG_ COASTING_STATE_CDT_DPT : 49|1@0+ (1,0) [0|1] ""  BV
 SG_ COASTING_STATE_CDT_OPTIPMI : 48|1@0+ (1,0) [0|1] ""  BV
 SG_ COASTING_STATE_RES_4 : 63|1@0+ (1,0) [0|1] ""  BV
 SG_ COASTING_STATE_RES_5 : 62|1@0+ (1,0) [0|1] ""  BV
 SG_ COASTING_STATE_RES_6 : 61|1@0+ (1,0) [0|1] ""  BV
 SG_ COASTING_STATE_RES_7 : 60|1@0+ (1,0) [0|1] ""  BV
 SG_ CPLMT1_REGIME_MOTEUR : 7|16@0+ (1,0) [1|65535] ""  BV
 SG_ CPLMT1_COUPLE_REEL : 23|8@0+ (1,0) [1|255] ""  BV
 SG_ CPLMT1_VOLONTE_COND : 31|8@0+ (1,0) [55|255] ""  BV
 SG_ CPT_PROCESS_4B_3B8 : 55|4@0+ (1,0) [0|15] ""  BV
 SG_ CPLMT1_CPL_POT_AP_TR : 39|8@0+ (1,0) [1|255] ""  BV

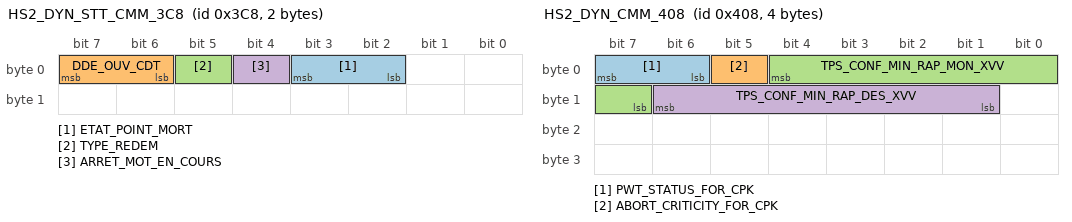
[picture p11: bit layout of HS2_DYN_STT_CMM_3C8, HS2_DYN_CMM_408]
BO_ 968 HS2_DYN_STT_CMM_3C8: 2 CMM
 SG_ ETAT_POINT_MORT : 3|2@0+ (1,0) [0|3] ""  RITCS,BV,UC_FREIN,BSI
 SG_ DDE_OUV_CDT : 7|2@0+ (1,0) [0|3] ""  RITCS,BV,UC_FREIN,BSI
 SG_ TYPE_REDEM : 5|1@0+ (1,0) [0|1] ""  RITCS,BV,UC_FREIN,BSI
 SG_ ARRET_MOT_EN_COURS : 4|1@0+ (1,0) [0|1] ""  RITCS,BV,UC_FREIN,BSI

BO_ 1001 HS2_DAT_BV_3E9: 2 BV
 SG_ REGIME_MOTEUR_AFF_BV : 7|8@0+ (50,0) [0|8200] "tr/min"  BSI

BO_ 1032 HS2_DYN_CMM_408: 4 CMM
 SG_ PWT_STATUS_FOR_CPK : 7|2@0+ (1,0) [0|3] ""  BV,UC_FREIN
 SG_ ABORT_CRITICITY_FOR_CPK : 5|1@0+ (1,0) [0|1] ""  BV,UC_FREIN
 SG_ TPS_CONF_MIN_RAP_MON_XVV : 4|6@0+ (0.1,0) [0|6.2] "s"  BV,UC_FREIN
 SG_ TPS_CONF_MIN_RAP_DES_XVV : 14|6@0+ (0.1,0) [0|6.2] "s"  BV,UC_FREIN

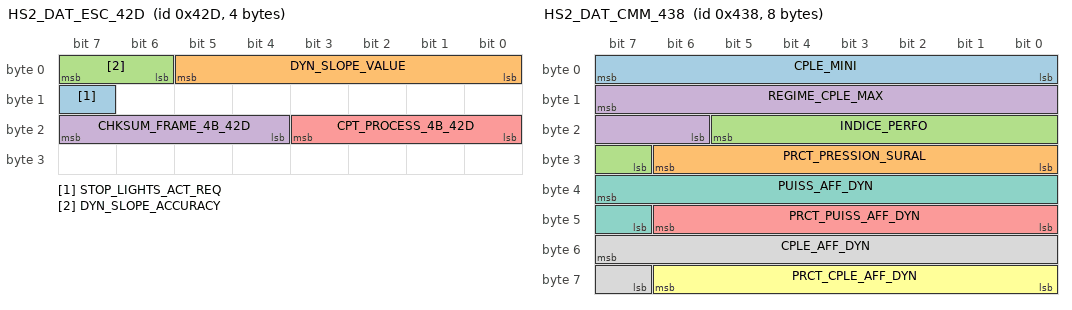
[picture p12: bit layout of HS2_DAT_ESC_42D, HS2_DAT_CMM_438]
BO_ 1069 HS2_DAT_ESC_42D: 4 UC_FREIN
 SG_ STOP_LIGHTS_ACT_REQ : 15|1@0+ (1,0) [0|1] ""  CMF,ARTIV,AAS,PASS_HCU2,CMM,BV,BSI
 SG_ DYN_SLOPE_VALUE : 5|6@0+ (1,-30) [-30|30] "%"  CMF,ARTIV,AAS,PASS_HCU2,CMM,BV,BSI
 SG_ DYN_SLOPE_ACCURACY : 7|2@0+ (1,0) [0|3] ""  CMF,ARTIV,AAS,PASS_HCU2,CMM,BV,BSI
 SG_ CHKSUM_FRAME_4B_42D : 23|4@0+ (1,0) [0|7] ""  CMF,ARTIV,AAS,PASS_HCU2,CMM,BV,BSI
 SG_ CPT_PROCESS_4B_42D : 19|4@0+ (1,0) [0|15] ""  CMF,ARTIV,AAS,PASS_HCU2,CMM,BV,BSI

BO_ 1070 HS2_DAT_BSI_42E: 4 BSI
 SG_ REQ_MODE_ESP : 7|3@0+ (1,0) [0|1] ""  UC_FREIN

BO_ 1074 HS2_DAT_BSI_432: 8 BSI
 SG_ DDE_PREPA_MOTEUR : 21|1@0+ (1,0) [0|1] ""  CAPT_ALG,BVN,ARTIV,ASR,AVAS
 SG_ REVEIL_PRINCIPAL : 7|2@0+ (1,0) [0|3] ""  CAPT_ALG,BVN,ARTIV,ASR,AVAS
 SG_ REVEIL_PRECH_UCAPS : 45|1@0+ (1,0) [0|1] ""  CAPT_ALG,BVN,ARTIV,ASR,AVAS
 SG_ REVEIL_POST_VENTIL_MOT : 46|1@0+ (1,0) [0|1] ""  CAPT_ALG,BVN,ARTIV,ASR,AVAS
 SG_ CTX_JDD : 55|6@0+ (1,0) [0|0] ""  CAPT_ALG,BVN,ARTIV,ASR,AVAS
 SG_ STATUT_DMD_DEM : 43|1@0+ (1,0) [0|1] ""  CAPT_ALG,BVN,ARTIV,ASR,AVAS
 SG_ DDE_ARRET_DEMARREUR : 2|1@0+ (1,0) [0|1] ""  CAPT_ALG,BVN,ARTIV,ASR,AVAS
 SG_ VOLONTE_DEM_GENE : 57|2@0+ (1,0) [0|3] ""  CAPT_ALG,BVN,ARTIV,ASR,AVAS
 SG_ REVEIL_CH : 3|1@0+ (1,0) [0|1] ""  CAPT_ALG,BVN,ARTIV,ASR,AVAS
 SG_ REVEIL_PST_PPL : 18|1@0+ (1,0) [0|1] ""  CAPT_ALG,BVN,ARTIV,ASR,AVAS
 SG_ REVEIL_PREPA_STT : 33|1@0+ (1,0) [0|1] ""  CAPT_ALG,BVN,ARTIV,ASR,AVAS
 SG_ REVEIL_VVH_UCFREIN : 39|1@0+ (1,0) [0|1] ""  CAPT_ALG,BVN,ARTIV,ASR,AVAS
 SG_ DDE_DEM_IMPULSIONNEL : 23|2@0+ (1,0) [0|3] ""  CAPT_ALG,BVN,ARTIV,ASR,AVAS
 SG_ REVEIL_MES_HUILE_MOT : 36|1@0+ (1,0) [0|1] ""  CAPT_ALG,BVN,ARTIV,ASR,AVAS
 SG_ REVEIL_PREPA_GEP : 47|1@0+ (1,0) [0|1] ""  CAPT_ALG,BVN,ARTIV,ASR,AVAS
 SG_ REVEIL_SURCHARGE_VHL : 37|1@0+ (1,0) [0|1] ""  CAPT_ALG,BVN,ARTIV,ASR,AVAS
 SG_ ETAT_PRINCIP_SEV : 49|2@0+ (1,0) [0|3] ""  CAPT_ALG,BVN,ARTIV,ASR,AVAS
 SG_ CPT_VOL_CARB_AJOUTE : 42|3@0+ (1,0) [0|6] ""  CAPT_ALG,BVN,ARTIV,ASR,AVAS
 SG_ DDE_COUP_MT : 1|2@0+ (1,0) [0|3] ""  CAPT_ALG,BVN,ARTIV,ASR,AVAS
 SG_ REVEIL_POWER_LATCH_HYB : 59|1@0+ (1,0) [0|1] ""  CAPT_ALG,BVN,ARTIV,ASR,AVAS
 SG_ ETAT_RESEAU_ELEC : 63|4@0+ (1,0) [0|15] ""  CAPT_ALG,BVN,ARTIV,ASR,AVAS
 SG_ CONSOM_SENSIBLE : 19|1@0+ (1,0) [0|1] ""  CAPT_ALG,BVN,ARTIV,ASR,AVAS
 SG_ REVEIL_PRE_PST_PPL : 17|1@0+ (1,0) [0|1] ""  CAPT_ALG,BVN,ARTIV,ASR,AVAS
 SG_ REVEIL_DDE_ETAT_BV : 5|1@0+ (1,0) [0|1] ""  CAPT_ALG,BVN,ARTIV,ASR,AVAS
 SG_ REVEIL_ANTICIPATION_ADC : 4|1@0+ (1,0) [0|1] ""  CAPT_ALG,BVN,ARTIV,ASR,AVAS
 SG_ SEV_DEM : 13|2@0+ (1,0) [0|3] ""  CAPT_ALG,BVN,ARTIV,ASR,AVAS
 SG_ VOL_CARB_AJOUTE : 31|8@0+ (0.5,0) [0|126.5] "L"  CAPT_ALG,BVN,ARTIV,ASR,AVAS
 SG_ PUSH_PWT_ECO : 58|1@0+ (1,0) [0|1] ""  CAPT_ALG,BVN,ARTIV,ASR,AVAS
 SG_ REVEIL_PREPA_DEM_MOT : 38|1@0+ (1,0) [0|1] ""  CAPT_ALG,BVN,ARTIV,ASR,AVAS
 SG_ REVEIL_PRECHAUF_FLEX : 16|1@0+ (1,0) [0|1] ""  CAPT_ALG,BVN,ARTIV,ASR,AVAS
 SG_ REVEIL_CORRECT_HAUT_PNEU : 32|1@0+ (1,0) [0|1] ""  CAPT_ALG,BVN,ARTIV,ASR,AVAS
 SG_ REVEIL_DDE_ETAT_FSE : 34|1@0+ (1,0) [0|1] ""  CAPT_ALG,BVN,ARTIV,ASR,AVAS
 SG_ HADC_ENABLE_REQ : 20|1@0+ (1,0) [0|1] ""  CAPT_ALG,BVN,ARTIV,ASR,AVAS
 SG_ MECATRONIC_HEADLAMP_REQ : 35|1@0+ (1,0) [0|1] ""  CAPT_ALG,BVN,ARTIV,ASR,AVAS
 SG_ CPT_PROCESS_4B_BSI_1 : 11|4@0+ (1,0) [0|15] ""  CAPT_ALG,BVN,ARTIV,ASR,AVAS

BO_ 1080 HS2_DAT_CMM_438: 8 CMM
 SG_ CPLE_MINI : 7|8@0+ (2,-100) [-100|408] "N.m"  RITCS,BV,BSI
 SG_ PRCT_PRESSION_SURAL : 30|7@0+ (1,0) [0|100] "%"  RITCS,BV,BSI
 SG_ INDICE_PERFO : 21|7@0+ (1,0) [0|100] "%"  RITCS,BV,BSI
 SG_ REGIME_CPLE_MAX : 15|10@0+ (10,0) [0|6000] "tr/min"  RITCS,BV,BSI
 SG_ PRCT_PUISS_AFF_DYN : 46|7@0+ (1,0) [0|100] "%"  RITCS,BV,BSI
 SG_ PRCT_CPLE_AFF_DYN : 62|7@0+ (1,0) [0|100] "%"  RITCS,BV,BSI
 SG_ PUISS_AFF_DYN : 39|9@0+ (1,0) [0|400] "ch"  RITCS,BV,BSI
 SG_ CPLE_AFF_DYN : 55|9@0+ (1,0) [0|500] "N.m"  RITCS,BV,BSI

BO_ 1106 HS2_DAT_MDD_CMD_452: 6 BSI
 SG_ CHKSUM_CONS_RVV_LVV2 : 17|2@0+ (1,0) [0|3] ""  CMF,ARTIV,CMM,UC_FREIN
 SG_ TYPE_REGUL_LONGI : 1|2@0+ (1,0) [0|3] ""  CMF,ARTIV,CMM,UC_FREIN
 SG_ ETAT_CLIGNOTANTS : 5|2@0+ (1,0) [0|3] ""  CMF,ARTIV,CMM,UC_FREIN
 SG_ FREIN_SEUL_DMD_BSI : 18|1@0+ (1,0) [0|1] ""  CMF,ARTIV,CMM,UC_FREIN
 SG_ CONS_LIM_VITESSE_VEH : 15|8@0+ (1,0) [0|255] "km/h"  CMF,ARTIV,CMM,UC_FREIN
 SG_ COCKPIT_GO_ACC_REQUEST : 45|1@0+ (1,0) [0|1] ""  CMF,ARTIV,CMM,UC_FREIN
 SG_ ARC_SENSIBILITE_HAB : 26|3@0+ (1,0) [0|7] ""  CMF,ARTIV,CMM,UC_FREIN
 SG_ ETAT_ESSUYAGE_AV : 7|2@0+ (1,0) [0|3] ""  CMF,ARTIV,CMM,UC_FREIN
 SG_ ETAT_LAVAGE_AV : 32|1@0+ (1,0) [0|1] ""  CMF,ARTIV,CMM,UC_FREIN
 SG_ DDE_ACTIVATION_LVV : 22|1@0+ (1,0) [0|1] ""  CMF,ARTIV,CMM,UC_FREIN
 SG_ DDE_ACTIVATION_RVV_ACC : 23|1@0+ (1,0) [0|1] ""  CMF,ARTIV,CMM,UC_FREIN
 SG_ CONS_TEMPS_INTER_VEH : 39|6@0+ (0.1,0) [0|6.1] "s"  CMF,ARTIV,CMM,UC_FREIN
 SG_ PROGRAMME_ACC : 47|2@0+ (1,0) [0|3] ""  CMF,ARTIV,CMM,UC_FREIN
 SG_ FA_DMD_ACTIV_HAB : 33|1@0+ (1,0) [0|1] ""  CMF,ARTIV,CMM,UC_FREIN
 SG_ ARC_DMD_ACTIV_HAB : 27|1@0+ (1,0) [0|1] ""  CMF,ARTIV,CMM,UC_FREIN
 SG_ CHKSUM_FRAME_4B_452 : 43|4@0+ (1,0) [0|15] ""  CMF,ARTIV,CMM,UC_FREIN
 SG_ CPT_TRAME_BSI2 : 31|4@0+ (1,0) [0|15] ""  CMF,ARTIV,CMM,UC_FREIN

BO_ 1160 HS2_BGE_DAT_CMM_488: 8 PASS_BSI
 SG_ PREPARE_BOUGIES_PRE : 37|1@0+ (1,0) [0|0] ""  PASS_HCU2,RITCS,UC_FREIN,CSS,BV,BSI,HCU1
 SG_ DDE_ALLUM_VOY_MLGE_PVRE : 28|1@0+ (1,0) [0|0] ""  PASS_HCU2,RITCS,UC_FREIN,CSS,BV,BSI,HCU1
 SG_ REQ_LAMPE_MIL : 26|1@0+ (1,0) [0|0] ""  PASS_HCU2,RITCS,UC_FREIN,CSS,BV,BSI,HCU1
 SG_ PRESSION_REFRI : 55|8@0+ (25,0) [100|3100] "kPa"  PASS_HCU2,RITCS,UC_FREIN,CSS,BV,BSI,HCU1
 SG_ COUP_CLIM_SECU : 32|1@0+ (1,0) [0|0] ""  PASS_HCU2,RITCS,UC_FREIN,CSS,BV,BSI,HCU1
 SG_ ALERTE_NIV_MIN_ADDITIF : 28|1@0+ (1,0) [0|0] ""  PASS_HCU2,RITCS,UC_FREIN,CSS,BV,BSI,HCU1
 SG_ REQ_LAMPE_PRECH : 25|1@0+ (1,0) [0|0] ""  PASS_HCU2,RITCS,UC_FREIN,CSS,BV,BSI,HCU1
 SG_ ALRT_TEMP_EAU : 27|1@0+ (1,0) [0|0] ""  PASS_HCU2,RITCS,UC_FREIN,CSS,BV,BSI,HCU1
 SG_ FORCAGE_PRESSION_BVA : 39|1@0+ (1,0) [0|0] ""  PASS_HCU2,RITCS,UC_FREIN,CSS,BV,BSI,HCU1
 SG_ DEFAUT_RVV_LVV : 30|1@0+ (1,0) [0|0] ""  PASS_HCU2,RITCS,UC_FREIN,CSS,BV,BSI,HCU1
 SG_ ETAT_GESTION_CLIM : 34|2@0+ (1,0) [0|0] ""  PASS_HCU2,RITCS,UC_FREIN,CSS,BV,BSI,HCU1
 SG_ DEM_EN_COURS : 24|1@0+ (1,0) [0|0] ""  PASS_HCU2,RITCS,UC_FREIN,CSS,BV,BSI,HCU1
 SG_ RISQUE_COLMATAGE_FAP : 38|1@0+ (1,0) [0|0] ""  PASS_HCU2,RITCS,UC_FREIN,CSS,BV,BSI,HCU1
 SG_ CONSO_CARBURANT : 15|8@0+ (80,0) [0|20400] "mm3"  PASS_HCU2,RITCS,UC_FREIN,CSS,BV,BSI,HCU1
 SG_ DMD_GMP_CLIGNO_STOP_SVCE : 36|2@0+ (1,0) [0|0] ""  PASS_HCU2,RITCS,UC_FREIN,CSS,BV,BSI,HCU1
 SG_ RATES_COMBUSTION : 31|1@0+ (1,0) [0|0] ""  PASS_HCU2,RITCS,UC_FREIN,CSS,BV,BSI,HCU1
 SG_ CNS_REGUL_RALENTI : 23|8@0+ (8,0) [0|2024] "tr/min"  PASS_HCU2,RITCS,UC_FREIN,CSS,BV,BSI,HCU1
 SG_ TYPE_INFO_CONSO_CARB : 37|1@0+ (1,0) [0|0] ""  PASS_HCU2,RITCS,UC_FREIN,CSS,BV,BSI,HCU1
 SG_ TEMP_AIR_MOT : 63|8@0+ (1,-40) [-40|214] "Degré C"  PASS_HCU2,RITCS,UC_FREIN,CSS,BV,BSI,HCU1
 SG_ TEMP_EAU_MOT : 7|8@0+ (1,-40) [-40|214] "Degré C"  PASS_HCU2,RITCS,UC_FREIN,CSS,BV,BSI,HCU1
 SG_ TEMP_HUILE_MOT : 47|8@0+ (1,-40) [-40|214] "Degré C"  PASS_HCU2,RITCS,UC_FREIN,CSS,BV,BSI,HCU1

BO_ 1166 HS2_DAT_BSI_48E: 4 BSI
 SG_ AC_AEROLIC_REQ : 6|7@0+ (1,0) [0|100] "%"  CMM
 SG_ ETAT_MEAP_2 : 14|3@0+ (1,0) [0|0] ""  CMM
 SG_ POS_MEAP_2_ACT : 11|4@0+ (1,0) [0|0] ""  CMM

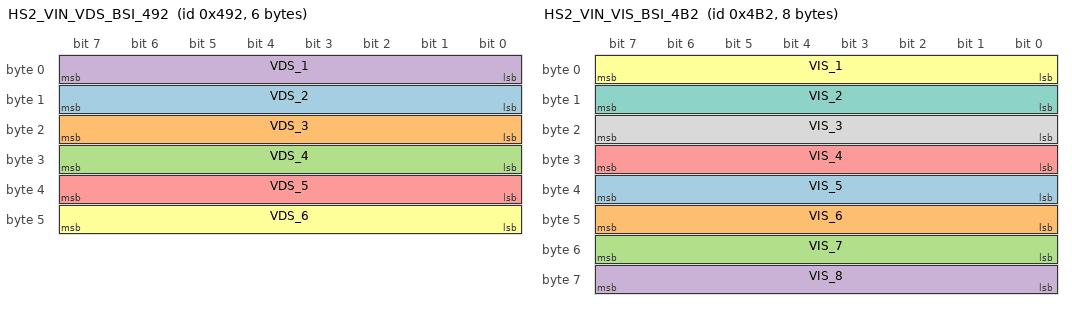
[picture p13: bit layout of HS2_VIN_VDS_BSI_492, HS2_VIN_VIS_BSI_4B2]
BO_ 1170 HS2_VIN_VDS_BSI_492: 6 BSI
 SG_ VDS_2 : 15|8@0+ (1,0) [0|0] ""  BVN,CMM
 SG_ VDS_3 : 23|8@0+ (1,0) [0|0] ""  BVN,CMM
 SG_ VDS_4 : 31|8@0+ (1,0) [0|0] ""  BVN,CMM
 SG_ VDS_1 : 7|8@0+ (1,0) [0|0] ""  BVN,CMM
 SG_ VDS_5 : 39|8@0+ (1,0) [0|0] ""  BVN,CMM
 SG_ VDS_6 : 47|8@0+ (1,0) [0|0] ""  BVN,CMM

BO_ 1202 HS2_VIN_VIS_BSI_4B2: 8 BSI
 SG_ VIS_5 : 39|8@0+ (1,0) [0|0] ""  CMM,BVN
 SG_ VIS_6 : 47|8@0+ (1,0) [0|0] ""  CMM,BVN
 SG_ VIS_7 : 55|8@0+ (1,0) [0|0] ""  CMM,BVN
 SG_ VIS_8 : 63|8@0+ (1,0) [0|0] ""  CMM,BVN
 SG_ VIS_4 : 31|8@0+ (1,0) [0|0] ""  CMM,BVN
 SG_ VIS_1 : 7|8@0+ (1,0) [0|0] ""  CMM,BVN
 SG_ VIS_2 : 15|8@0+ (1,0) [0|0] ""  CMM,BVN
 SG_ VIS_3 : 23|8@0+ (1,0) [0|0] ""  CMM,BVN

BO_ 1234 HS2_VIN_WMI_BSI_4D2: 3 BSI
 SG_ WMI_1 : 7|8@0+ (1,0) [0|0] ""  BVN,CMM
 SG_ WMI_2 : 15|8@0+ (1,0) [0|0] ""  BVN,CMM
 SG_ WMI_3 : 23|8@0+ (1,0) [0|0] ""  BVN,CMM

BO_ 1261 HS2_DAT_ESP_4ED: 5 UC_FREIN
 SG_ D_OBD_ESP_CAN_LAS : 23|1@0+ (1,0) [0|0] ""  HCU2
 SG_ D_OBD_ESP_CVR_ARD : 19|1@0+ (1,0) [0|0] ""  HCU2
 SG_ D_OBD_ESP_CAN_IS : 22|1@0+ (1,0) [0|0] ""  HCU2
 SG_ D_OBD_ESP_CONTACT_FREIN : 21|1@0+ (1,0) [0|0] ""  HCU2
 SG_ D_OBD_ESP_SURTENSION : 25|1@0+ (1,0) [0|0] ""  HCU2
 SG_ D_OBD_ESP_CAPT_MASTERVAC : 14|1@0+ (1,0) [0|0] ""  HCU2
 SG_ D_OBD_ESP_POMPE_ESP : 13|1@0+ (1,0) [0|0] ""  HCU2
 SG_ D_OBD_ESP_EV_ESP : 12|1@0+ (1,0) [0|0] ""  HCU2
 SG_ D_OBD_ESP_COM_CMM : 9|1@0+ (1,0) [0|0] ""  HCU2
 SG_ D_OBD_ESP_COM_TRICAPT : 8|1@0+ (1,0) [0|0] ""  HCU2
 SG_ D_OBD_ESP_F_CAPT_PRESS : 0|1@0+ (1,0) [0|0] ""  HCU2
 SG_ D_OBD_ESP_CAPT_MAIT_CYL : 27|1@0+ (1,0) [0|0] ""  HCU2
 SG_ D_OBD_ESP_CAPT_VOLANT : 31|1@0+ (1,0) [0|0] ""  HCU2
 SG_ D_OBD_ESP_CAPT_INERT : 30|1@0+ (1,0) [0|0] ""  HCU2
 SG_ D_OBD_ESP_CAPT_VIT_ROUE : 20|1@0+ (1,0) [0|0] ""  HCU2
 SG_ D_OBD_ESP_CVR_ARG : 18|1@0+ (1,0) [0|0] ""  HCU2
 SG_ ACTIV_DIAG_PANNE_VIDE : 32|1@0+ (1,0) [0|0] ""  HCU2
 SG_ DIAG_PANNE_VIDE : 33|1@0+ (1,0) [0|0] ""  HCU2
 SG_ DEFAUT_CAPT_ACCEL_LAT_RB : 29|1@0+ (1,0) [0|0] ""  HCU2
 SG_ DEFAUT_CAPT_VITESSE_LACET_RB : 28|1@0+ (1,0) [0|0] ""  HCU2
 SG_ D_OBD_ESP_CVR_AVD : 17|1@0+ (1,0) [0|0] ""  HCU2
 SG_ D_OBD_ESP_CVR_AVG : 16|1@0+ (1,0) [0|0] ""  HCU2
 SG_ D_OBD_ESP_S_POMPE_VIDE : 15|1@0+ (1,0) [0|0] ""  HCU2
 SG_ D_OBD_ESP_TELECODAGE : 26|1@0+ (1,0) [0|0] ""  HCU2
 SG_ D_OBD_ESP_ERREUR_INT : 24|1@0+ (1,0) [0|0] ""  HCU2
 SG_ D_OBD_ESP_COM_CAPT_VOL : 11|1@0+ (1,0) [0|0] ""  HCU2
 SG_ D_OBD_ESP_COM_PTMU : 10|1@0+ (1,0) [0|0] ""  HCU2

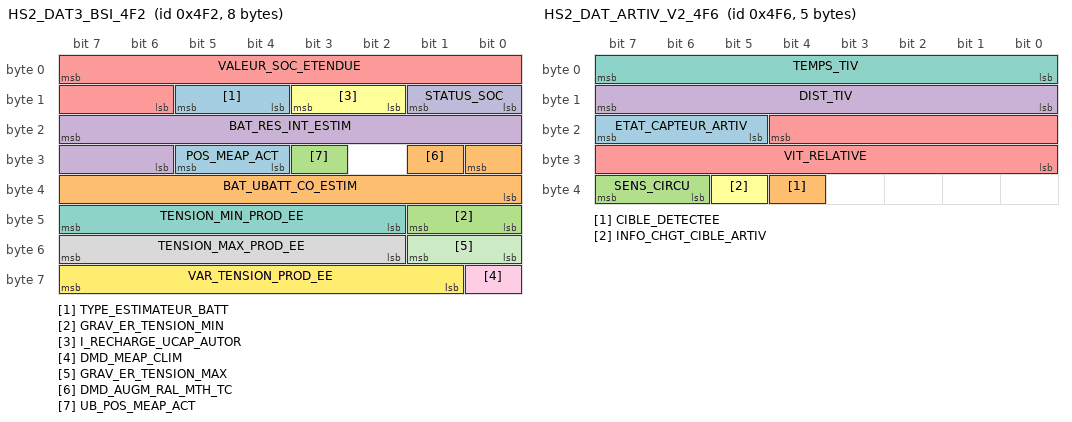
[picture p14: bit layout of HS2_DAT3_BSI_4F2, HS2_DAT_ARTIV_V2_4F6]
BO_ 1266 HS2_DAT3_BSI_4F2: 8 BSI
 SG_ TYPE_ESTIMATEUR_BATT : 13|2@0+ (1,0) [0|0] ""  PASS_HCU2,RITCS,CMM
 SG_ BAT_UBATT_CO_ESTIM : 24|9@0+ (0.01,11) [11|14] "V"  PASS_HCU2,RITCS,CMM
 SG_ GRAV_ER_TENSION_MIN : 41|2@0+ (1,0) [0|0] ""  PASS_HCU2,RITCS,CMM
 SG_ BAT_RES_INT_ESTIM : 23|10@0+ (0.01,0) [0|10] "mOhm"  PASS_HCU2,RITCS,CMM
 SG_ VALEUR_SOC_ETENDUE : 7|10@0+ (0.1,0) [0|100] "%"  PASS_HCU2,RITCS,CMM
 SG_ I_RECHARGE_UCAP_AUTOR : 11|2@0+ (1,0) [0|0] ""  PASS_HCU2,RITCS,CMM
 SG_ TENSION_MIN_PROD_EE : 47|6@0+ (0.1,10.6) [10.6|16] "V"  PASS_HCU2,RITCS,CMM
 SG_ TENSION_MAX_PROD_EE : 55|6@0+ (0.1,10.6) [10.6|16] "V"  PASS_HCU2,RITCS,CMM
 SG_ DMD_MEAP_CLIM : 56|1@0+ (1,0) [0|0] ""  PASS_HCU2,RITCS,CMM
 SG_ STATUS_SOC : 9|2@0+ (1,0) [0|0] ""  PASS_HCU2,RITCS,CMM
 SG_ GRAV_ER_TENSION_MAX : 49|2@0+ (1,0) [0|0] ""  PASS_HCU2,RITCS,CMM
 SG_ VAR_TENSION_PROD_EE : 63|7@0+ (0.1,0) [0.1|10] "V/s"  PASS_HCU2,RITCS,CMM
 SG_ POS_MEAP_ACT : 29|2@0+ (1,0) [0|0] ""  PASS_HCU2,RITCS,CMM
 SG_ DMD_AUGM_RAL_MTH_TC : 25|1@0+ (1,0) [0|0] ""  PASS_HCU2,RITCS,CMM
 SG_ UB_POS_MEAP_ACT : 27|1@0+ (1,0) [0|0] ""  PASS_HCU2,RITCS,CMM

BO_ 1270 HS2_DAT_ARTIV_V2_4F6: 5 ARTIV
 SG_ ETAT_CAPTEUR_ARTIV : 23|3@0+ (1,0) [0|0] ""  RITCS,BSI,CMF
 SG_ CIBLE_DETECTEE : 36|1@0+ (1,0) [0|0] ""  RITCS,BSI,CMF
 SG_ SENS_CIRCU : 39|2@0+ (1,0) [0|0] ""  RITCS,BSI,CMF
 SG_ DIST_TIV : 15|8@0+ (1,0) [0|253] "m"  RITCS,BSI,CMF
 SG_ VIT_RELATIVE : 20|13@0+ (0.02,-70) [-70|70] "m/s"  RITCS,BSI,CMF
 SG_ INFO_CHGT_CIBLE_ARTIV : 37|1@0+ (1,0) [0|0] ""  RITCS,BSI,CMF
 SG_ TEMPS_TIV : 7|8@0+ (0.1,0) [0|25.4] "s"  RITCS,BSI,CMF

BO_ 1277 HS2_DAT_SEL_4FD: 2 MCM
 SG_ OVF_DOWN : 14|1@0+ (1,0) [0|0] ""  UC_FREIN
 SG_ DEFAUT_MOLETTE : 13|2@0+ (1,0) [0|0] ""  UC_FREIN
 SG_ CPT_S_6BIT : 7|6@0- (1,0) [-32|31] ""  UC_FREIN
 SG_ OVF_UP : 15|1@0+ (1,0) [0|0] ""  UC_FREIN

BO_ 1294 HS2_DAT_CLIM_50E: 8 BSI
 SG_ DEM_RAL_HAB : 47|8@0+ (8,0) [0|2032] "tr/min"  PASS_HCU2,RITCS,UC_FREIN,SCDT,CMM,BV
 SG_ TYPE_REGUL_LONGI : 62|2@0+ (1,0) [0|3] ""  PASS_HCU2,RITCS,UC_FREIN,SCDT,CMM,BV
 SG_ CHKSUM_CONS_RVV_LVV : 5|2@0+ (1,0) [0|3] ""  PASS_HCU2,RITCS,UC_FREIN,SCDT,CMM,BV
 SG_ ETAT_EMB_COMP : 1|1@0+ (1,0) [0|1] ""  PASS_HCU2,RITCS,UC_FREIN,SCDT,CMM,BV
 SG_ FORCAGE_ENCL_BOUGIES : 17|1@0+ (1,0) [0|1] ""  PASS_HCU2,RITCS,UC_FREIN,SCDT,CMM,BV
 SG_ DEF_IDENT_HAB : 2|1@0+ (1,0) [0|1] ""  PASS_HCU2,RITCS,UC_FREIN,SCDT,CMM,BV
 SG_ DDE_REDEM_MOT_HAB : 23|2@0+ (1,0) [0|3] ""  PASS_HCU2,RITCS,UC_FREIN,SCDT,CMM,BV
 SG_ CONS_LIM_VITESSE_VEH : 55|8@0+ (1,0) [0|255] "km/h"  PASS_HCU2,RITCS,UC_FREIN,SCDT,CMM,BV
 SG_ DDE_REDEM_HAB : 23|1@0+ (1,0) [0|1] ""  PASS_HCU2,RITCS,UC_FREIN,SCDT,CMM,BV
 SG_ NIV_DELESTAGE_SEV : 19|1@0+ (1,0) [0|1] ""  PASS_HCU2,RITCS,UC_FREIN,SCDT,CMM,BV
 SG_ DDE_ACTIVATION_LVV : 60|1@0+ (1,0) [0|1] ""  PASS_HCU2,RITCS,UC_FREIN,SCDT,CMM,BV
 SG_ INTERD_ARRET_HAB : 29|2@0+ (1,0) [0|3] ""  PASS_HCU2,RITCS,UC_FREIN,SCDT,CMM,BV
 SG_ AUTOR_ARRET_MOT_HAB : 2|1@0+ (1,0) [0|1] ""  PASS_HCU2,RITCS,UC_FREIN,SCDT,CMM,BV
 SG_ DDE_ACTIVATION_RVV_ACC : 63|1@0+ (1,0) [0|1] ""  PASS_HCU2,RITCS,UC_FREIN,SCDT,CMM,BV
 SG_ MINI_GPL : 3|1@0+ (1,0) [0|1] ""  PASS_HCU2,RITCS,UC_FREIN,SCDT,CMM,BV
 SG_ DDE_HABITACLE_SG : 31|1@0+ (1,0) [0|1] ""  PASS_HCU2,RITCS,UC_FREIN,SCDT,CMM,BV
 SG_ PRES_COND : 26|2@0+ (1,0) [0|3] ""  PASS_HCU2,RITCS,UC_FREIN,SCDT,CMM,BV
 SG_ CONSIGNE_GMV : 15|2@0+ (1,0) [0|3] ""  PASS_HCU2,RITCS,UC_FREIN,SCDT,CMM,BV
 SG_ CNS_CONT_GMV_CLIM : 13|6@0+ (2,0) [0|110] "%"  PASS_HCU2,RITCS,UC_FREIN,SCDT,CMM,BV
 SG_ PUISS_MECA_CLIM : 39|8@0+ (25,0) [0|6350] "W"  PASS_HCU2,RITCS,UC_FREIN,SCDT,CMM,BV
 SG_ CPT_TRAME_BSI : 59|4@0+ (1,0) [0|15] ""  PASS_HCU2,RITCS,UC_FREIN,SCDT,CMM,BV

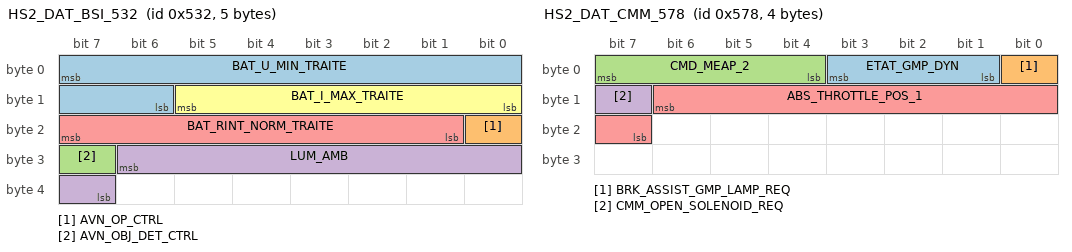
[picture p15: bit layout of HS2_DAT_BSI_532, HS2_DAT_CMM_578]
BO_ 1330 HS2_DAT_BSI_532: 5 BSI
 SG_ BAT_U_MIN_TRAITE : 7|10@0+ (0.01,3) [3|13] "V"  PASS_HCU2,CMM,BVN
 SG_ AVN_OP_CTRL : 16|1@0+ (1,0) [0|0] ""  PASS_HCU2,CMM,BVN
 SG_ AVN_OBJ_DET_CTRL : 31|1@0+ (1,0) [0|0] ""  PASS_HCU2,CMM,BVN
 SG_ LUM_AMB : 30|8@0+ (1,0) [0|254] ""  PASS_HCU2,CMM,BVN
 SG_ BAT_RINT_NORM_TRAITE : 23|7@0+ (0.1,0) [0|10] "mOhm"  PASS_HCU2,CMM,BVN
 SG_ BAT_I_MAX_TRAITE : 13|6@0+ (20,-1500) [-1500|-300] "A"  PASS_HCU2,CMM,BVN

BO_ 1356 HS2_DAT_BVN_54C: 4 BVN
 SG_ AVN_PEDESTRIAN_STATE : 3|1@0+ (1,0) [0|0] ""  BSI
 SG_ AVN_STATE : 2|3@0+ (1,0) [0|0] ""  BSI
 SG_ AVN_DETECT_PEDESTRIAN : 7|2@0+ (1,0) [0|0] ""  BSI
 SG_ AVN_DETECT_ANIMAL : 5|2@0+ (1,0) [0|0] ""  BSI

BO_ 1362 HS2_DAT4_V2_BSI_552: 8 BSI
 SG_ KILOMETRAGE : 39|24@0+ (1,0) [0|16777214] "km"  BVN,ARTIV,EBB,AVAS
 SG_ CPT_TEMPOREL : 7|32@0+ (0.1,0) [0|429496729.3] "s"  BVN,ARTIV,EBB,AVAS
 SG_ COMPTEUR_RAZ_GCT : 63|8@0+ (1,0) [0|253] ""  BVN,ARTIV,EBB,AVAS

BO_ 1375 HS2_ACQ_NEW_JDD_55F: 1 BSI
 SG_ DATA_ACQ_JDD_BSI_2 : 7|8@0+ (1,0) [0|0] ""  BVN,CAPT_ALG,MCM,ARTIV

BO_ 1389 HS2_DAT2_FRE_56D: 3 UC_FREIN
 SG_ PTR_INFO_TRICPT_RB : 15|4@0+ (1,0) [0|0] ""  CAPT_ALG
 SG_ ACTIV_INFO_TRICPTR_RB : 8|1@0+ (1,0) [0|0] ""  CAPT_ALG
 SG_ CPT_INCR_CONTACT_RB : 19|1@0+ (1,0) [0|0] ""  CAPT_ALG
 SG_ CRC_TRICPTR_RB : 7|8@0+ (1,0) [0|255] ""  CAPT_ALG

BO_ 1393 HS2_AVAS_571: 1 AVAS
 SG_ ETAT_AVERT_SON_VEH_SIL : 7|1@0+ (1,0) [0|0] ""  BSI
 SG_ DIAG_AVERT_SON_VEH_SIL : 6|1@0+ (1,0) [0|0] ""  BSI

BO_ 1400 HS2_DAT_CMM_578: 4 CMM
 SG_ ETAT_GMP_DYN : 3|3@0+ (1,0) [0|0] ""  BV,BSI
 SG_ BRK_ASSIST_GMP_LAMP_REQ : 0|1@0+ (1,0) [0|0] ""  BV,BSI
 SG_ CMD_MEAP_2 : 7|4@0+ (1,0) [0|0] ""  BV,BSI
 SG_ CMM_OPEN_SOLENOID_REQ : 15|1@0+ (1,0) [0|0] ""  BV,BSI
 SG_ ABS_THROTTLE_POS_1 : 14|8@0+ (0.39216,0) [0|100] "%"  BV,BSI

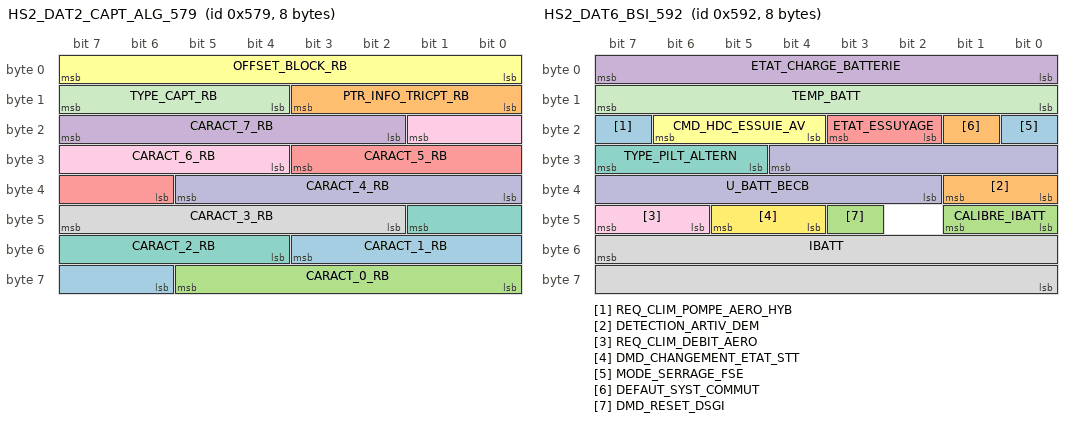
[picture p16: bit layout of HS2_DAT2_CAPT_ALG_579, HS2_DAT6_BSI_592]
BO_ 1401 HS2_DAT2_CAPT_ALG_579: 8 CAPT_ALG
 SG_ CARACT_1_RB : 51|6@0+ (1,0) [0|0] ""  UC_FREIN
 SG_ PTR_INFO_TRICPT_RB : 11|4@0+ (1,0) [0|0] ""  UC_FREIN
 SG_ CARACT_0_RB : 61|6@0+ (1,0) [0|0] ""  UC_FREIN
 SG_ CARACT_7_RB : 23|6@0+ (1,0) [0|0] ""  UC_FREIN
 SG_ CARACT_5_RB : 27|6@0+ (1,0) [0|0] ""  UC_FREIN
 SG_ OFFSET_BLOCK_RB : 7|8@0+ (1,0) [0|255] ""  UC_FREIN
 SG_ CARACT_2_RB : 41|6@0+ (1,0) [0|0] ""  UC_FREIN
 SG_ CARACT_3_RB : 47|6@0+ (1,0) [0|0] ""  UC_FREIN
 SG_ CARACT_6_RB : 17|6@0+ (1,0) [0|0] ""  UC_FREIN
 SG_ CARACT_4_RB : 37|6@0+ (1,0) [0|0] ""  UC_FREIN
 SG_ TYPE_CAPT_RB : 15|4@0+ (1,0) [0|0] ""  UC_FREIN

BO_ 1420 HS2_REP_DIAG_ON_CAN_58C: 8 BVN
 SG_ DATA_DIAG : 7|64@0+ (1,0) [0|0] ""  PASS_BSI

BO_ 1426 HS2_DAT6_BSI_592: 8 BSI
 SG_ REQ_CLIM_POMPE_AERO_HYB : 23|1@0+ (1,0) [0|0] ""  PASS_HCU2,CMF,ARTIV,RITCS,UC_FREIN,CMM
 SG_ DETECTION_ARTIV_DEM : 33|2@0+ (1,0) [0|0] ""  PASS_HCU2,CMF,ARTIV,RITCS,UC_FREIN,CMM
 SG_ CALIBRE_IBATT : 41|2@0+ (1,0) [0|0] ""  PASS_HCU2,CMF,ARTIV,RITCS,UC_FREIN,CMM
 SG_ ETAT_CHARGE_BATTERIE : 7|8@0+ (1,0) [0|100] "%"  PASS_HCU2,CMF,ARTIV,RITCS,UC_FREIN,CMM
 SG_ ETAT_ESSUYAGE : 19|2@0+ (1,0) [0|0] ""  PASS_HCU2,CMF,ARTIV,RITCS,UC_FREIN,CMM
 SG_ CMD_HDC_ESSUIE_AV : 22|3@0+ (1,0) [0|0] ""  PASS_HCU2,CMF,ARTIV,RITCS,UC_FREIN,CMM
 SG_ TYPE_PILT_ALTERN : 31|3@0+ (1,0) [0|0] ""  PASS_HCU2,CMF,ARTIV,RITCS,UC_FREIN,CMM
 SG_ IBATT : 55|16@0+ (1,0) [0|0] ""  PASS_HCU2,CMF,ARTIV,RITCS,UC_FREIN,CMM
 SG_ REQ_CLIM_DEBIT_AERO : 47|2@0+ (1,0) [0|0] ""  PASS_HCU2,CMF,ARTIV,RITCS,UC_FREIN,CMM
 SG_ U_BATT_BECB : 28|11@0+ (0.01,5) [5|18] "V"  PASS_HCU2,CMF,ARTIV,RITCS,UC_FREIN,CMM
 SG_ TEMP_BATT : 15|8@0+ (0.5,-30) [-30|85] "Degré C"  PASS_HCU2,CMF,ARTIV,RITCS,UC_FREIN,CMM
 SG_ DMD_CHANGEMENT_ETAT_STT : 45|2@0+ (1,0) [0|0] ""  PASS_HCU2,CMF,ARTIV,RITCS,UC_FREIN,CMM
 SG_ MODE_SERRAGE_FSE : 16|1@0+ (1,0) [0|0] ""  PASS_HCU2,CMF,ARTIV,RITCS,UC_FREIN,CMM
 SG_ DEFAUT_SYST_COMMUT : 17|1@0+ (1,0) [0|0] ""  PASS_HCU2,CMF,ARTIV,RITCS,UC_FREIN,CMM
 SG_ DMD_RESET_DSGI : 43|1@0+ (1,0) [0|0] ""  PASS_HCU2,CMF,ARTIV,RITCS,UC_FREIN,CMM

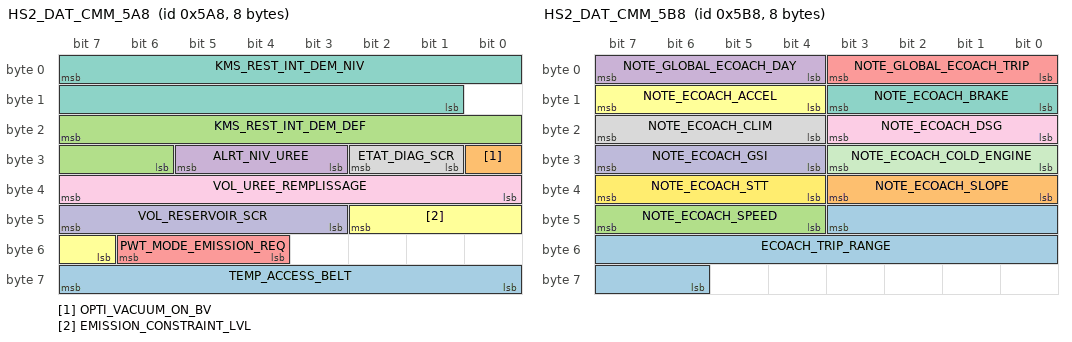
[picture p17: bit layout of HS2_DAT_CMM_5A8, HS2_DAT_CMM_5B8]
BO_ 1448 HS2_DAT_CMM_5A8: 8 CMM
 SG_ TEMP_ACCESS_BELT : 63|8@0+ (1,-40) [-40|214] "Degré C"  PASS_HCU2,BV,RITCS,BSI
 SG_ OPTI_VACUUM_ON_BV : 24|1@0+ (1,0) [0|0] ""  PASS_HCU2,BV,RITCS,BSI
 SG_ KMS_REST_INT_DEM_DEF : 23|10@0+ (10,0) [0|10000] "km"  PASS_HCU2,BV,RITCS,BSI
 SG_ ALRT_NIV_UREE : 29|3@0+ (1,0) [0|0] ""  PASS_HCU2,BV,RITCS,BSI
 SG_ PWT_MODE_EMISSION_REQ : 54|3@0+ (1,0) [0|0] ""  PASS_HCU2,BV,RITCS,BSI
 SG_ EMISSION_CONSTRAINT_LVL : 42|4@0+ (0.1,0) [0|1] ""  PASS_HCU2,BV,RITCS,BSI
 SG_ KMS_REST_INT_DEM_NIV : 7|15@0+ (1,0) [0|30000] "km"  PASS_HCU2,BV,RITCS,BSI
 SG_ ETAT_DIAG_SCR : 26|2@0+ (1,0) [0|0] ""  PASS_HCU2,BV,RITCS,BSI
 SG_ VOL_UREE_REMPLISSAGE : 39|8@0+ (0.2,0) [0|50.8] "L"  PASS_HCU2,BV,RITCS,BSI
 SG_ VOL_RESERVOIR_SCR : 47|5@0+ (1,0) [0|30] "L"  PASS_HCU2,BV,RITCS,BSI

BO_ 1449 HS2_DAT_BV_5A9: 4 BV
 SG_ TCU_TEMPERATURE : 7|8@0+ (1,-40) [-40|215] "Degré C"  CMM

BO_ 1452 HS2_REQ_DIAG_ON_CAN_5AC: 8 PASS_BSI
 SG_ DATA_DIAG : 7|64@0+ (1,0) [0|0] ""  BVN

BO_ 1455 HS2_REP_DIAG_ON_CAN_5AF: 8 AVAS
 SG_ DATA_DIAG : 7|64@0+ (1,0) [0|0] ""  PASS_VCU

BO_ 1456 HS2_REQ_DIAG_ON_CAN_5B0: 8 PASS_VCU
 SG_ DATA_DIAG : 7|64@0+ (1,0) [0|0] ""  AVAS

BO_ 1464 HS2_DAT_CMM_5B8: 8 CMM
 SG_ ECOACH_TRIP_RANGE : 43|14@0+ (1,-6000) [-6000|10000] "km"  BSI
 SG_ NOTE_ECOACH_SLOPE : 35|4@0+ (1,0) [0|0] ""  BSI
 SG_ NOTE_ECOACH_SPEED : 47|4@0+ (1,0) [0|0] ""  BSI
 SG_ NOTE_GLOBAL_ECOACH_DAY : 7|4@0+ (1,0) [0|0] ""  BSI
 SG_ NOTE_GLOBAL_ECOACH_TRIP : 3|4@0+ (1,0) [0|0] ""  BSI
 SG_ NOTE_ECOACH_ACCEL : 15|4@0+ (1,0) [0|0] ""  BSI
 SG_ NOTE_ECOACH_BRAKE : 11|4@0+ (1,0) [0|0] ""  BSI
 SG_ NOTE_ECOACH_CLIM : 23|4@0+ (1,0) [0|0] ""  BSI
 SG_ NOTE_ECOACH_DSG : 19|4@0+ (1,0) [0|0] ""  BSI
 SG_ NOTE_ECOACH_GSI : 31|4@0+ (1,0) [0|0] ""  BSI
 SG_ NOTE_ECOACH_COLD_ENGINE : 27|4@0+ (1,0) [0|0] ""  BSI
 SG_ NOTE_ECOACH_STT : 39|4@0+ (1,0) [0|0] ""  BSI

BO_ 1484 HS2_SUPV_BVN_5CC: 8 BVN
 SG_ CODE_DEFAUT : 7|8@0+ (1,0) [0|0] "" Vector__XXX
 SG_ ETAT_ELECTR_UCE : 47|4@0+ (1,0) [0|0] "" Vector__XXX
 SG_ STATUS_REVEIL_PARTIEL_GMP : 43|16@0+ (1,0) [0|0] "" Vector__XXX
 SG_ STATUS_CONFABSENT : 15|32@0+ (1,0) [0|0] "" Vector__XXX

BO_ 1487 HS2_REP_DIAG_ON_CAN_5CF: 8 EBB
 SG_ DATA_DIAG : 7|64@0+ (1,0) [0|0] ""  PASS_VCU

BO_ 1488 HS2_REQ_DIAG_ON_CAN_5D0: 8 PASS_VCU
 SG_ DATA_DIAG : 7|64@0+ (1,0) [0|0] ""  EBB

BO_ 1489 HS2_SUPV_AVAS_5D1: 8 AVAS
 SG_ CODE_DEFAUT : 7|8@0+ (1,0) [0|0] "" Vector__XXX
 SG_ ETAT_ELECTR_UCE : 47|4@0+ (1,0) [0|0] "" Vector__XXX
 SG_ STATUS_REVEIL_PARTIEL_LAS : 43|16@0+ (1,0) [0|0] "" Vector__XXX
 SG_ STATUS_CONFABSENT : 15|32@0+ (1,0) [0|0] "" Vector__XXX

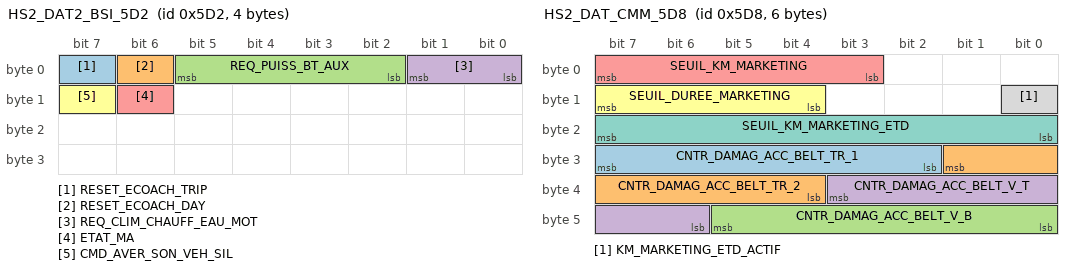
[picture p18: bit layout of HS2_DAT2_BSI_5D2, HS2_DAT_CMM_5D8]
BO_ 1490 HS2_DAT2_BSI_5D2: 4 BSI
 SG_ RESET_ECOACH_TRIP : 7|1@0+ (1,0) [0|0] ""  PASS_HCU2,CMM
 SG_ RESET_ECOACH_DAY : 6|1@0+ (1,0) [0|0] ""  PASS_HCU2,CMM
 SG_ REQ_PUISS_BT_AUX : 5|4@0+ (1,0) [0|0] ""  PASS_HCU2,CMM
 SG_ REQ_CLIM_CHAUFF_EAU_MOT : 1|2@0+ (1,0) [0|0] ""  PASS_HCU2,CMM
 SG_ ETAT_MA : 14|1@0+ (1,0) [0|0] ""  PASS_HCU2,CMM
 SG_ CMD_AVER_SON_VEH_SIL : 15|1@0+ (1,0) [0|0] ""  PASS_HCU2,CMM

BO_ 1496 HS2_DAT_CMM_5D8: 6 CMM
 SG_ CNTR_DAMAG_ACC_BELT_TR_1 : 31|6@0+ (1,2) [0|100] "%"  BSI,RITCS
 SG_ CNTR_DAMAG_ACC_BELT_TR_2 : 25|6@0+ (1,2) [0|100] "%"  BSI,RITCS
 SG_ CNTR_DAMAG_ACC_BELT_V_B : 45|6@0+ (1,2) [0|100] "%"  BSI,RITCS
 SG_ CNTR_DAMAG_ACC_BELT_V_T : 35|6@0+ (1,2) [0|100] "%"  BSI,RITCS
 SG_ SEUIL_KM_MARKETING : 7|5@0+ (1000,0) [0|30000] "km"  BSI,RITCS
 SG_ SEUIL_DUREE_MARKETING : 15|4@0+ (3,0) [0|24] "Mois"  BSI,RITCS
 SG_ SEUIL_KM_MARKETING_ETD : 23|8@0+ (500,0) [0|127000] "km"  BSI,RITCS
 SG_ KM_MARKETING_ETD_ACTIF : 8|1@0+ (1,0) [0|0] ""  BSI,RITCS

BO_ 1516 HS2_EMIS_NEW_JDD_BVN_5EC: 8 BVN
 SG_ CODES_DEFAUT m1 : 15|24@0+ (1,0) [0|0] ""  BSI
 SG_ KILOMETRAGE_JDD m2 : 15|24@0+ (1,0) [0|16777214] "km"  BSI
 SG_ TYPE_MESSAGE : 1|2@0+ (1,0) [0|0] ""  BSI
 SG_ REFERENCE_HORAIRE m1 : 39|32@0+ (0.1,0) [0|429496729.3] "s"  BSI
 SG_ ETAT_DTC : 3|1@0+ (1,0) [0|0] ""  BSI
 SG_ NUMERO_TRAME M : 5|2@0+ (1,0) [0|0] ""  BSI
 SG_ NOMBRE_TRAMES : 7|2@0+ (1,0) [0|0] ""  BSI
 SG_ SITUATION_VIE_JDD m2 : 39|24@0+ (1,0) [0|0] ""  BSI

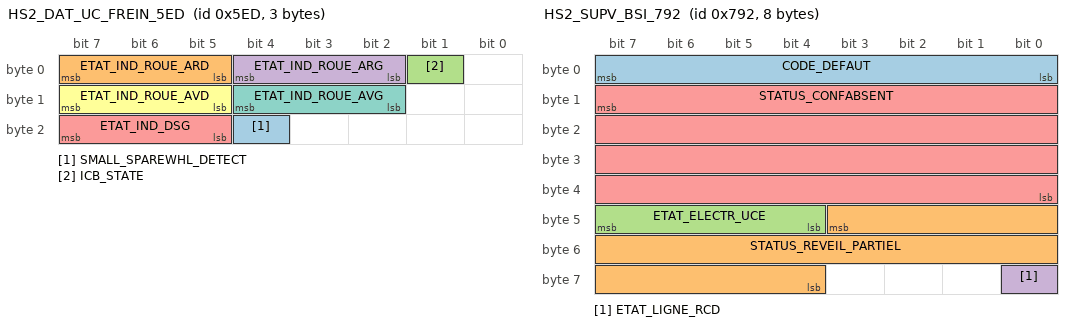
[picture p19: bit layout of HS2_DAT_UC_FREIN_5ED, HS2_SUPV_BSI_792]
BO_ 1517 HS2_DAT_UC_FREIN_5ED: 3 UC_FREIN
 SG_ SMALL_SPAREWHL_DETECT : 20|1@0+ (1,0) [0|0] ""  RITCS,BSI
 SG_ ETAT_IND_ROUE_ARD : 7|3@0+ (1,0) [0|0] ""  RITCS,BSI
 SG_ ICB_STATE : 1|1@0+ (1,0) [0|0] ""  RITCS,BSI
 SG_ ETAT_IND_ROUE_ARG : 4|3@0+ (1,0) [0|0] ""  RITCS,BSI
 SG_ ETAT_IND_DSG : 23|3@0+ (1,0) [0|0] ""  RITCS,BSI
 SG_ ETAT_IND_ROUE_AVD : 15|3@0+ (1,0) [0|0] ""  RITCS,BSI
 SG_ ETAT_IND_ROUE_AVG : 12|3@0+ (1,0) [0|0] ""  RITCS,BSI

BO_ 1518 HS2_DAT_BSI_5EE: 4 BSI
 SG_ DELAI_DER_PRECOND_TH : 15|10@0+ (1,-1) [0|720] "min"  BVN,CMM,RITCS
 SG_ TEMP_AIR_EXT : 21|8@0+ (0.5,-40) [-40|85] "Degré C"  BVN,CMM,RITCS
 SG_ DUREE_DER_PRECOND_TH : 7|7@0+ (30,-30) [0|2700] "s"  BVN,CMM,RITCS
 SG_ SOLENOID_BLOCKED : 0|1@0+ (1,0) [0|0] ""  BVN,CMM,RITCS

BO_ 1519 HS2_EMIS_NEW_JDD_EBB_5EF: 8 EBB
 SG_ CODES_DEFAUT m1 : 15|24@0+ (1,0) [0|0] ""  BSI
 SG_ KILOMETRAGE_JDD m2 : 15|24@0+ (1,0) [0|16777214] "km"  BSI
 SG_ TYPE_MESSAGE : 1|2@0+ (1,0) [0|0] ""  BSI
 SG_ REFERENCE_HORAIRE m1 : 39|32@0+ (0.1,0) [0|429496729.3] "s"  BSI
 SG_ ETAT_DTC : 3|1@0+ (1,0) [0|0] ""  BSI
 SG_ NUMERO_TRAME M : 5|2@0+ (1,0) [0|0] ""  BSI
 SG_ NOMBRE_TRAMES : 7|2@0+ (1,0) [0|0] ""  BSI
 SG_ SITUATION_VIE_JDD m2 : 39|24@0+ (1,0) [0|0] ""  BSI

BO_ 1520 HS2_SUPV_EBB_5F0: 8 EBB
 SG_ CODE_DEFAUT : 7|8@0+ (1,0) [0|0] "" Vector__XXX
 SG_ ETAT_ELECTR_UCE : 47|4@0+ (1,0) [0|0] "" Vector__XXX
 SG_ STATUS_REVEIL_PARTIEL_LAS : 43|16@0+ (1,0) [0|0] "" Vector__XXX
 SG_ STATUS_CONFABSENT : 15|32@0+ (1,0) [0|0] "" Vector__XXX

BO_ 1521 HS2_EMIS_NEW_JDD_AVAS_5F1: 8 AVAS
 SG_ CODES_DEFAUT m1 : 15|24@0+ (1,0) [0|0] ""  BSI
 SG_ KILOMETRAGE_JDD m2 : 15|24@0+ (1,0) [0|16777214] "km"  BSI
 SG_ TYPE_MESSAGE : 1|2@0+ (1,0) [0|0] ""  BSI
 SG_ REFERENCE_HORAIRE m1 : 39|32@0+ (0.1,0) [0|429496729.3] "s"  BSI
 SG_ ETAT_DTC : 3|1@0+ (1,0) [0|0] ""  BSI
 SG_ NUMERO_TRAME M : 5|2@0+ (1,0) [0|0] ""  BSI
 SG_ NOMBRE_TRAMES : 7|2@0+ (1,0) [0|0] ""  BSI
 SG_ SITUATION_VIE_JDD m2 : 39|24@0+ (1,0) [0|0] ""  BSI

BO_ 1554 HS2_DAT7_BSI_612: 8 BSI
 SG_ MODE_ECO : 17|2@0+ (1,0) [0|0] ""  CMM,BV,BVN
 SG_ CDE_CLG_ET_HDC : 15|2@0+ (1,0) [0|3] ""  CMM,BV,BVN
 SG_ INH_ECLAIRAGE_VIRAGE_DYN : 5|1@0+ (1,0) [0|0] ""  CMM,BV,BVN
 SG_ MODE_CONF_VEH : 13|2@0+ (1,0) [0|0] ""  CMM,BV,BVN
 SG_ INH_DIURNE_ECLRGE : 7|1@0+ (1,0) [0|0] ""  CMM,BV,BVN
 SG_ CONFIG_VHL : 60|3@0+ (1,0) [0|0] ""  CMM,BV,BVN
 SG_ INFO_REQ_OLVI_REAR_ACT : 39|1@0+ (1,0) [0|0] ""  CMM,BV,BVN
 SG_ INFO_NIV_CARB : 31|8@0+ (0.5,0) [0|127] "L"  CMM,BV,BVN
 SG_ MODE_ASR_PLUS_SELECT : 19|2@0+ (1,0) [0|0] ""  CMM,BV,BVN
 SG_ U_PRED_DEMARRAGE : 34|11@0+ (0.01,0) [0|13] "V"  CMM,BV,BVN
 SG_ POS_DEFLEC_MOBILE : 38|3@0+ (1,0) [0|0] ""  CMM,BV,BVN
 SG_ INH_ECLAIRAGE_AUTOROUTE : 6|1@0+ (1,0) [0|0] ""  CMM,BV,BVN
 SG_ ETAT_FEUX_CROIST : 9|1@0+ (1,0) [0|0] ""  CMM,BV,BVN
 SG_ DEF_FEU_ROUTE_G : 20|1@0+ (1,0) [0|0] ""  CMM,BV,BVN
 SG_ UB_D_LIGNE_REL_RX : 49|1@0+ (1,0) [0|0] ""  CMM,BV,BVN
 SG_ D_LIGNE_REL_R3 : 63|3@0+ (1,0) [0|0] ""  CMM,BV,BVN
 SG_ ETAT_FEUX_ROUTE : 10|1@0+ (1,0) [0|0] ""  CMM,BV,BVN
 SG_ DEF_FEU_CROISMNT_G : 22|1@0+ (1,0) [0|0] ""  CMM,BV,BVN
 SG_ DEF_FEU_ROUTE_D : 21|1@0+ (1,0) [0|0] ""  CMM,BV,BVN
 SG_ D_LIGNE_REL_R2 : 52|3@0+ (1,0) [0|0] ""  CMM,BV,BVN
 SG_ D_LIGNE_REL_R1 : 55|3@0+ (1,0) [0|0] ""  CMM,BV,BVN
 SG_ DEF_FEU_CROISMNT_D : 23|1@0+ (1,0) [0|0] ""  CMM,BV,BVN

BO_ 1686 HS2_REP_DIAG_ON_CAN_696: 8 ARTIV
 SG_ DATA_DIAG : 7|64@0+ (1,0) [0|0] ""  PASS_BSI

BO_ 1689 HS2_REP_DIAG_ON_CAN_699: 8 CAPT_ALG
 SG_ DATA_DIAG : 7|64@0+ (1,0) [0|0] ""  PASS_BSI

BO_ 1693 HS2_REP_DIAG_ON_CAN_69D: 8 MCM
 SG_ DATA_DIAG : 7|64@0+ (1,0) [0|0] ""  OUTIL_DIAG

BO_ 1718 HS2_REQ_DIAG_ON_CAN_6B6: 8 PASS_BSI
 SG_ DATA_DIAG : 7|64@0+ (1,0) [0|0] ""  ARTIV

BO_ 1721 HS2_REQ_DIAG_ON_CAN_6B9: 8 PASS_BSI
 SG_ DATA_DIAG : 7|64@0+ (1,0) [0|0] ""  CAPT_ALG

BO_ 1725 HS2_REQ_DIAG_ON_CAN_6BD: 8 OUTIL_DIAG
 SG_ DATA_DIAG : 7|64@0+ (1,0) [0|0] ""  MCM

BO_ 1910 HS2_EMIS_NEW_JDD_ARTIV_776: 8 ARTIV
 SG_ CODES_DEFAUT m1 : 15|24@0+ (1,0) [0|0] ""  BSI
 SG_ KILOMETRAGE_JDD m2 : 15|24@0+ (1,0) [0|16777214] "km"  BSI
 SG_ TYPE_MESSAGE : 1|2@0+ (1,0) [0|0] ""  BSI
 SG_ REFERENCE_HORAIRE m1 : 39|32@0+ (0.1,0) [0|429496729.3] "s"  BSI
 SG_ ETAT_DTC : 3|1@0+ (1,0) [0|0] ""  BSI
 SG_ NUMERO_TRAME M : 5|2@0+ (1,0) [0|0] ""  BSI
 SG_ NOMBRE_TRAMES : 7|2@0+ (1,0) [0|0] ""  BSI
 SG_ SITUATION_VIE_JDD m2 : 39|24@0+ (1,0) [0|0] ""  BSI

BO_ 1917 HS2_EMIS_NEW_JDD_ASR_PLUS_77D: 8 MCM
 SG_ CODES_DEFAUT m1 : 15|24@0+ (1,0) [0|0] ""  BSI
 SG_ KILOMETRAGE_JDD m2 : 15|24@0+ (1,0) [0|16777214] "km"  BSI
 SG_ TYPE_MESSAGE : 1|2@0+ (1,0) [0|0] ""  BSI
 SG_ REFERENCE_HORAIRE m1 : 39|32@0+ (0.1,0) [0|429496729.3] "s"  BSI
 SG_ ETAT_DTC : 3|1@0+ (1,0) [0|0] ""  BSI
 SG_ NUMERO_TRAME M : 5|2@0+ (1,0) [0|0] ""  BSI
 SG_ NOMBRE_TRAMES : 7|2@0+ (1,0) [0|0] ""  BSI
 SG_ SITUATION_VIE_JDD m2 : 39|24@0+ (1,0) [0|0] ""  BSI

BO_ 1938 HS2_SUPV_BSI_792: 8 BSI
 SG_ CODE_DEFAUT : 7|8@0+ (1,0) [0|0] "" Vector__XXX
 SG_ STATUS_REVEIL_PARTIEL : 43|16@0+ (1,0) [0|0] "" Vector__XXX
 SG_ ETAT_ELECTR_UCE : 47|4@0+ (1,0) [0|0] "" Vector__XXX
 SG_ ETAT_LIGNE_RCD : 56|1@0+ (1,0) [0|0] "" Vector__XXX
 SG_ STATUS_CONFABSENT : 15|32@0+ (1,0) [0|0] "" Vector__XXX

BO_ 1942 HS2_SUPV_ARTIV_796: 8 ARTIV
 SG_ CODE_DEFAUT : 7|8@0+ (1,0) [0|0] "" Vector__XXX
 SG_ ETAT_ELECTR_UCE : 47|4@0+ (1,0) [0|0] "" Vector__XXX
 SG_ STATUS_REVEIL_PARTIEL_GMP : 43|16@0+ (1,0) [0|0] "" Vector__XXX
 SG_ STATUS_CONFABSENT : 15|32@0+ (1,0) [0|0] "" Vector__XXX

BO_ 1949 HS2_SUPV_ASR_PLUS_79D: 6 MCM
 SG_ CODE_DEFAUT : 7|8@0+ (1,0) [0|0] "" Vector__XXX
 SG_ ETAT_ELECTR_UCE : 47|4@0+ (1,0) [0|0] "" Vector__XXX
 SG_ STATUS_CONFABSENT : 15|32@0+ (1,0) [0|0] "" Vector__XXX

BO_ 2047 HS2_DIAG_UDS_ON_CAN_7FF: 8 OUTIL_DIAG
 SG_ DATA_DIAG : 7|64@0+ (1,0) [0|0] ""  UC_DIRA,UC_FREIN,CMM,BV,FAMILLE_DSG,SUSP,FSE,PROJ,SBW,PASS_BSM,CAPT_VOL

BO_TX_BU_ 694 : ARTIV,CMF;
BO_TX_BU_ 758 : ARTIV,CMF;
BO_TX_BU_ 1270 : ARTIV,CMF;
BO_TX_BU_ 1721 : PASS_BSI,OUTIL_DIAG;

CM_ BO_ 238 "La définition du contenu dépend du type de calculateur :
- Téléchargeable (logiciel et calibrage) en Flash Eprom : le contenu de la trame est une recopie d'un sous-ensemble de la zone d'identification de la Flash Eprom définie dans le document Application flash EPROM 2000 ref. 96.285.582.99.
- Téléchargeable (calibrage) en Eeprom : le contenu de la trame est une recopie d'un sous-ensemble de la zone d'identification de l'Eeprom définie dans le document Téléchargement de calibrations pour UCEs sans flash Eprom ref. 96.401.797.9A.
- Non téléchargeable : le contenu de la trame est une recopie d'un sous-ensemble de l'étiquette électronique définie dans le document Keyword Protocol 2000 - 3F ref. 96.253.521.99.";
CM_ SG_ 238 VERSION_SYSTEME "Identifie le type du calculateur.
Ce numéro est défini dans le § zone d'identification de la flash eprom et trame version des systèmes";
CM_ SG_ 238 EDITION_CALIB "Caractérise les évolutions de calibrage.
S'il n'y a pas d'indice de calibrage, cette donnée doit etre mise à zéro.";
CM_ SG_ 238 VERSION_SOFT "Caractérise la version du logiciel";
CM_ SG_ 238 EDITION_SOFT "Caractérise l'evolution de la version du logiciel.";
CM_ SG_ 238 VERS_DATE2_MOIS "S'il n'y a pas de mois de la version, cette donnée doit être mise à FFh.";
CM_ SG_ 238 VERS_DATE2_JOUR "S'il n'y a pas de jour de la version, cette donnée doit être mise à FFh.";
CM_ SG_ 238 VERS_DATE2_ANNEE "Date de la version du logiciel
Codé sur 1 octet : de 00 à 99
S'il n'y a pas d'année de la version, cette donnée doit être mise à FFh";
CM_ SG_ 238 VERSION_APPLI "Définit un type d'application; elle correspond à une version de hardware différente pour le système donné.
S'il n'y a pas d'application fournisseur, cette donnée doit être mise à FFh
Cette donnée est fixée par le fournisseur.";
CM_ BO_ 239 "La définition du contenu dépend du type de calculateur :
- Téléchargeable (logiciel et calibrage) en Flash Eprom : le contenu de la trame est une recopie d'un sous-ensemble de la zone d'identification de la Flash Eprom définie dans le document Application flash EPROM 2000 ref. 96.285.582.99.
- Téléchargeable (calibrage) en Eeprom : le contenu de la trame est une recopie d'un sous-ensemble de la zone d'identification de l'Eeprom définie dans le document Téléchargement de calibrations pour UCEs sans flash Eprom ref. 96.401.797.9A.
- Non téléchargeable : le contenu de la trame est une recopie d'un sous-ensemble de l'étiquette électronique définie dans le document Keyword Protocol 2000 - 3F ref. 96.253.521.99.";
CM_ SG_ 239 VERSION_SYSTEME "Identifie le type du calculateur.
Ce numéro est défini dans le § zone d'identification de la flash eprom et trame version des systèmes";
CM_ SG_ 239 EDITION_CALIB "Caractérise les évolutions de calibrage.
S'il n'y a pas d'indice de calibrage, cette donnée doit etre mise à zéro.";
CM_ SG_ 239 VERSION_SOFT "Caractérise la version du logiciel";
CM_ SG_ 239 EDITION_SOFT "Caractérise l'evolution de la version du logiciel.";
CM_ SG_ 239 VERS_DATE2_MOIS "S'il n'y a pas de mois de la version, cette donnée doit être mise à FFh.";
CM_ SG_ 239 VERS_DATE2_JOUR "S'il n'y a pas de jour de la version, cette donnée doit être mise à FFh.";
CM_ SG_ 239 VERS_DATE2_ANNEE "Date de la version du logiciel
Codé sur 1 octet : de 00 à 99
S'il n'y a pas d'année de la version, cette donnée doit être mise à FFh";
CM_ SG_ 239 VERSION_APPLI "Définit un type d'application; elle correspond à une version de hardware différente pour le système donné.
S'il n'y a pas d'application fournisseur, cette donnée doit être mise à FFh
Cette donnée est fixée par le fournisseur.";
CM_ BO_ 274 "La définition du contenu dépend du type de calculateur :
- Téléchargeable (logiciel et calibration) en Flash Eprom : le contenu de la trame est une recopie d'un sous-ensemble de la zone d'identification de la Flash Eprom définie dans le document Application flash EPROM 2000 ref. 96.285.582.99.
- Téléchargeable (calibration) en Eeprom : le contenu de la trame est une recopie d'un sous-ensemble de la zone d'identification de l'Eeprom définie dans le document Téléchargement de calibrations pour UCEs sans flash Eprom ref. 96.401.797.9A.
- Non téléchargeable : le contenu de la trame est une recopie d'un sous-ensemble de l'étiquette électronique définie dans le document Keyword Protocol 2000 - 3F ref. 96.253.521.99.";
CM_ SG_ 274 VERSION_SYSTEME "Identifie le type du calculateur.
Ce numéro est défini dans le § zone d'identification de la flash eprom et trame version des systèmes";
CM_ SG_ 274 EDITION_CALIB "Caractérise les évolutions de calibrage.
S'il n'y a pas d'indice de calibrage, cette donnée doit etre mise à zéro.";
CM_ SG_ 274 VERSION_SOFT "Caractérise la version du logiciel";
CM_ SG_ 274 EDITION_SOFT "Caractérise l'evolution de la version du logiciel.";
CM_ SG_ 274 VERS_DATE2_MOIS "S'il n'y a pas de mois de la version, cette donnée doit être mise à FFh.";
CM_ SG_ 274 VERS_DATE2_JOUR "S'il n'y a pas de jour de la version, cette donnée doit être mise à FFh.";
CM_ SG_ 274 VERS_DATE2_ANNEE "Date de la version du logiciel
Codé sur 1 octet : de 00 à 99
S'il n'y a pas d'année de la version, cette donnée doit être mise à FFh";
CM_ SG_ 274 VERSION_APPLI "Définit un type d'application; elle correspond à une version de hardware différente pour le système donné.
S'il n'y a pas d'application fournisseur, cette donnée doit être mise à FFh
Cette donnée est fixée par le fournisseur.";
CM_ BO_ 278 "La définition du contenu dépend du type de calculateur :
- Téléchargeable (logiciel et calibrage) en Flash Eprom : le contenu de la trame est une recopie d'un sous-ensemble de la zone d'identification de la Flash Eprom définie dans le document Application flash EPROM 2000 ref. 96.285.582.99.
- Téléchargeable (calibrage) en Eeprom : le contenu de la trame est une recopie d'un sous-ensemble de la zone d'identification de l'Eeprom définie dans le document Téléchargement de calibrations pour UCEs sans flash Eprom ref. 96.401.797.9A.
- Non téléchargeable : le contenu de la trame est une recopie d'un sous-ensemble de l'étiquette électronique définie dans le document Keyword Protocol 2000 - 3F ref. 96.253.521.99.";
CM_ SG_ 278 VERSION_SYSTEME "Identifie le type du calculateur.
Ce numéro est défini dans le § zone d'identification de la flash eprom et trame version des systèmes";
CM_ SG_ 278 EDITION_CALIB "Caractérise les évolutions de calibrage.
S'il n'y a pas d'indice de calibrage, cette donnée doit etre mise à zéro.";
CM_ SG_ 278 VERSION_SOFT "Caractérise la version du logiciel";
CM_ SG_ 278 EDITION_SOFT "Caractérise l'evolution de la version du logiciel.";
CM_ SG_ 278 VERS_DATE2_MOIS "S'il n'y a pas de mois de la version, cette donnée doit être mise à FFh.";
CM_ SG_ 278 VERS_DATE2_JOUR "S'il n'y a pas de jour de la version, cette donnée doit être mise à FFh.";
CM_ SG_ 278 VERS_DATE2_ANNEE "Date de la version du logiciel
Codé sur 1 octet : de 00 à 99
S'il n'y a pas d'année de la version, cette donnée doit être mise à FFh";
CM_ SG_ 278 VERSION_APPLI "Définit un type d'application; elle correspond à une version de hardware différente pour le système donné.
S'il n'y a pas d'application fournisseur, cette donnée doit être mise à FFh
Cette donnée est fixée par le fournisseur.";
CM_ SG_ 285 VERSION_SYSTEME "Identifie le type du calculateur.
Ce numéro est défini dans le § zone d'identification de la flash eprom et trame version des systèmes";
CM_ SG_ 285 EDITION_CALIB "Caractérise les évolutions de calibrage.
S'il n'y a pas d'indice de calibrage, cette donnée doit etre mise à zéro.";
CM_ SG_ 285 VERSION_SOFT "Caractérise la version du logiciel";
CM_ SG_ 285 EDITION_SOFT "Caractérise l'evolution de la version du logiciel.";
CM_ SG_ 285 VERS_DATE2_MOIS "S'il n'y a pas de mois de la version, cette donnée doit être mise à FFh.";
CM_ SG_ 285 VERS_DATE2_JOUR "S'il n'y a pas de jour de la version, cette donnée doit être mise à FFh.";
CM_ SG_ 285 VERS_DATE2_ANNEE "Date de la version du logiciel
Codé sur 1 octet : de 00 à 99
S'il n'y a pas d'année de la version, cette donnée doit être mise à FFh";
CM_ SG_ 285 VERSION_APPLI "Définit un type d'application; elle correspond à une version de hardware différente pour le système donné.
S'il n'y a pas d'application fournisseur, cette donnée doit être mise à FFh
Cette donnée est fixée par le fournisseur.";
CM_ BO_ 300 "La définition du contenu dépend du type de calculateur :
- Téléchargeable (logiciel et calibrage) en Flash Eprom : le contenu de la trame est une recopie d'un sous-ensemble de la zone d'identification de la Flash Eprom définie dans le document Application flash EPROM 2000 ref. 96.285.582.99.
- Téléchargeable (calibrage) en Eeprom : le contenu de la trame est une recopie d'un sous-ensemble de la zone d'identification de l'Eeprom définie dans le document Téléchargement de calibrations pour UCEs sans flash Eprom ref. 96.401.797.9A.
- Non téléchargeable : le contenu de la trame est une recopie d'un sous-ensemble de l'étiquette électronique définie dans le document Keyword Protocol 2000 - 3F ref. 96.253.521.99.";
CM_ SG_ 300 VERSION_SYSTEME "Identifie le type du calculateur.
Ce numéro est défini dans le § zone d'identification de la flash eprom et trame version des systèmes";
CM_ SG_ 300 EDITION_CALIB "Caractérise les évolutions de calibrage.
S'il n'y a pas d'indice de calibrage, cette donnée doit etre mise à zéro.";
CM_ SG_ 300 VERSION_SOFT "Caractérise la version du logiciel";
CM_ SG_ 300 EDITION_SOFT "Caractérise l'evolution de la version du logiciel.";
CM_ SG_ 300 VERS_DATE2_MOIS "S'il n'y a pas de mois de la version, cette donnée doit être mise à FFh.";
CM_ SG_ 300 VERS_DATE2_JOUR "S'il n'y a pas de jour de la version, cette donnée doit être mise à FFh.";
CM_ SG_ 300 VERS_DATE2_ANNEE "Date de la version du logiciel
Codé sur 1 octet : de 00 à 99
S'il n'y a pas d'année de la version, cette donnée doit être mise à FFh";
CM_ SG_ 300 VERSION_APPLI "Définit un type d'application; elle correspond à une version de hardware différente pour le système donné.
S'il n'y a pas d'application fournisseur, cette donnée doit être mise à FFh
Cette donnée est fixée par le fournisseur.";
CM_ SG_ 525 CHKSUM_FRAME_4B_20D "CHK_INI = 0xD";
CM_ BO_ 552 "Emise pour la fonction Easy Move";
CM_ SG_ 557 CHKSUM_FRAME_4B_22D "CHK_INI = 0x3";
CM_ SG_ 642 CHKSUM_FRAME_4B_282 "CHK_INI = 0xD";
CM_ SG_ 664 CHKSUM_FRAME_4B_298 "CHK_INI = 0x3";
CM_ SG_ 690 ETAT_RVV_LVV "Etat de la fonction RVV2 ou LVV";
CM_ SG_ 690 ETAT_MT "Etat de fonctionnement du moteur thermique";
CM_ SG_ 694 ETAT_ACC "Permet de signaler l'état de fonctionnement du système ACC";
CM_ SG_ 694 CPT_PROCESS_4B_ACC "Ce compteur s'incrémente de 0 à 15 à chaque activation du processus de calcul.";
CM_ SG_ 694 CHKSUM_TRME_DYN_ACC "CHK_INI = 0x3";
CM_ SG_ 744 POS_ACCEL_COND_GMP "Rq : représentatif du flux entrant de l'IVC";
CM_ SG_ 744 CNS_POT_CPLE_ROUE_GMP_ABS "Cns_cple_MSR = N * 20 - 1000";
CM_ SG_ 758 CPT_PROCESS_4B_ACC2 "Ce compteur s'incrémente de 0 à 15 à chaque activation du processus de calcul.";
CM_ SG_ 758 CHKSUM_TRME_DYN_ACC2 "CHK_INI = 0x7";
CM_ SG_ 802 CHKSUM_FRAME_4B_322 "CHK_INI = 0xD";
CM_ SG_ 809 CPLE_RESIST_PREDIT "CPLE_RESIST_PREDIT = N* 1";
CM_ SG_ 809 CHKSUM_TRME_DYN_BV_329 "pour la trame 0x349 v2, CHK_INI = 0x9.
(pour la trame 0x349 v1, CHK_INI = 0xF.)
pour la trame 0x329, CHK_INI = 0x2.
pour la trame 0x3C9, CHK_INI = 0x1.";
CM_ SG_ 813 CPT_PROCESS_4B_UC_FREIN "Ce compteur s'incrémente de 0 à 15 à chaque activation du processus de calcul.";
CM_ SG_ 813 CHKSUM_TRME_DYN_UCF_ACC "CHK_INI = 0x2";
CM_ SG_ 845 CPT_PROCESS_4B_ESP "Ce compteur s'incrémente de 0 à 15 à chaque activation du processus de calcul.";
CM_ SG_ 909 DISTANCE_ROUES "Distance mesurée avec les capteurs de roues";
CM_ SG_ 909 ACCEL_LONGI_ROUES "Acceleration mesurée avec les capteurs de roues";
CM_ SG_ 909 CHKSUM_TRME_DYN_UC_FREIN "CHK_INI = 0x8";
CM_ SG_ 952 CPLMT1_CPL_CND_AP_TR "Complément à 1 du couple demande par le conducteur après traitement (CPLE_COND_APR_TRT)
 pour la SDF";
CM_ SG_ 952 CPLMT1_REGIME_MOTEUR "Complément à 1 du REGIME_MOTEUR pour besoin SDF";
CM_ SG_ 952 CPLMT1_COUPLE_REEL "Complément à 1 du couple réel (COUPLE_REEL) pour la SDF";
CM_ SG_ 952 CPLMT1_VOLONTE_COND "Complément à 1 de la volonté conducteur (VOLONTE_COND) pour la SDF";
CM_ SG_ 952 CPLMT1_CPL_POT_AP_TR "Complément à 1 du couple potentiel demandé par le conducteur après traitement (CPLE_POT_APR_TRT) pour la SDF";
CM_ SG_ 1069 CHKSUM_FRAME_4B_42D "CHK_INI = 0x6";
CM_ SG_ 1074 DDE_PREPA_MOTEUR "Demande de préparation du moteur thermique pour le démarrage faîte par le véhicule au CMM";
CM_ SG_ 1074 REVEIL_PRINCIPAL "Demande de réveil principal (RCD)";
CM_ SG_ 1074 REVEIL_PRECH_UCAPS "Réveil partiel émis par le BSI à destiantion de l'AR2S";
CM_ SG_ 1074 CTX_JDD "* Codage :
bit 7.7 : Réservé
bits 7.6 à 7.5 : Position du shunt BSI
bits 7.4 à 7.2 : Alimentations

Se référer à la STE n° CSEO_APPT07_0032 : Mécanismes du JDD AEE2010 Packs A & B.";
CM_ SG_ 1074 DDE_ARRET_DEMARREUR "Demande d'arrêt démarreur faîte par le véhicule au CMM";
CM_ SG_ 1074 REVEIL_CH "Demande de réveil pour correction de hauteur (RCD)";
CM_ SG_ 1074 REVEIL_PREPA_STT "Réveil partiel émis par le BSI à destiantion de l'AR2S";
CM_ SG_ 1074 REVEIL_VVH_UCFREIN "Demande de réveil de l'UC frein pour émission de la vitesse véhicule (RCD)";
CM_ SG_ 1074 DDE_DEM_IMPULSIONNEL "Demande de démarrage impulsionnel faîte par le véhicule au CMM.";
CM_ SG_ 1074 REVEIL_MES_HUILE_MOT "Active l'acquisition des informations huile sur demande de la BSI";
CM_ SG_ 1074 REVEIL_PREPA_GEP "Demande de réveil (RCD) BVMP.Le GEP rétablit la pression dans le circuit hydraulique.";
CM_ SG_ 1074 ETAT_PRINCIP_SEV "Etat principal SEV";
CM_ SG_ 1074 DDE_COUP_MT "Demande de coupure du moteur thermique faîte par le véhicule au CMM";
CM_ SG_ 1074 REVEIL_DDE_ETAT_BV "Demande de réveil BV (RCD) pour renvoi de l'état BV (rapport de boîte engagé, position levier,...)";
CM_ SG_ 1074 REVEIL_ANTICIPATION_ADC "Demande de réveil pour anticipation ADC (RCD)";
CM_ SG_ 1074 REVEIL_PREPA_DEM_MOT "Demande de réveil (RCD) pour préparer le démarrage moteur (essence)";
CM_ SG_ 1074 REVEIL_PRECHAUF_FLEX "Demande de réveil (RCD) BVMP.Le GEP rétablit la pression dans le circuit hydraulique.";
CM_ SG_ 1074 REVEIL_CORRECT_HAUT_PNEU "Demande de réveil partiel pour correction de hauteur pneumatique (RCD).";
CM_ SG_ 1074 REVEIL_DDE_ETAT_FSE "Demande de réveil pour besoin affichages";
CM_ SG_ 1074 CPT_PROCESS_4B_BSI_1 "Ce compteur s'incrémente de 0 à 15 à chaque activation du processus de calcul.";
CM_ SG_ 1106 CHKSUM_CONS_RVV_LVV2 "Sert à sécuriser la consigne RVV ou consigne LVV émise par le réseau CAN (signal CONS_LIM_VITESSE_VEH)";
CM_ SG_ 1106 TYPE_REGUL_LONGI "Définit si on est en LVV ou RVV ou ACC ou sans régulation.";
CM_ SG_ 1106 CONS_LIM_VITESSE_VEH "Consigne ou limite : selon la valeur du bit 'type de Vitesse V demandée'";
CM_ SG_ 1106 ETAT_ESSUYAGE_AV "Emis si capteur de pluie";
CM_ SG_ 1106 CHKSUM_FRAME_4B_452 "CHK_INI = 0xB";
CM_ SG_ 1160 PREPARE_BOUGIES_PRE "L'activation des bougies implique la coupure de la LUCH par la BSI pour l'agrément de conduite en FAP1";
CM_ SG_ 1160 DDE_ALLUM_VOY_MLGE_PVRE "Allume un voyant pour signaler que le démarrage du moteur à froid sera difficile.";
CM_ SG_ 1160 ALERTE_NIV_MIN_ADDITIF "Information au conducteur pour qu'il effectue le plein d'additif dans le réseau après vente";
CM_ SG_ 1160 FORCAGE_PRESSION_BVA "Le but est de charger l'alternateur et par là le moteur pour faciliter la régénération en augmentant le débit d'injection";
CM_ SG_ 1160 RISQUE_COLMATAGE_FAP "Indication au conducteur qu'il doit provoquer une régénération par une conduite adaptée";
CM_ SG_ 1160 CONSO_CARBURANT "carburant : essence, diesel, GPL...";
CM_ SG_ 1160 RATES_COMBUSTION "Cette information vise à avertir d'un fort risque de détérioration du catalyseur en essence .";
CM_ SG_ 1160 TYPE_INFO_CONSO_CARB "Type info consommation carburant utilisé pour FAP2 pour avoir la pseudo consommation
Type info consommation carburant en FAP2";
CM_ SG_ 1160 TEMP_AIR_MOT "Signal capteur Température d'air dans le système d'admission
Ce capteur est situé sur le boitier papillon ou le débimètre en Ess., et sur le débimètre en Diesel";
CM_ BO_ 1170 "Trame VDS d'identification du modèle de la voiture (Vehicle Description Section)";
CM_ SG_ 1170 VDS_2 "Second caractere de VDS";
CM_ SG_ 1170 VDS_3 "Troisieme caractere de VDS";
CM_ SG_ 1170 VDS_4 "Quatrieme caractere de VDS";
CM_ SG_ 1170 VDS_1 "Premier caractere de VDS";
CM_ SG_ 1170 VDS_5 "Cinquieme caractere de VDS";
CM_ SG_ 1170 VDS_6 "Sixième caractere de VDS";
CM_ BO_ 1202 "Trame VIS d'identification du numéro de sortie de la voiture (Vehicle Identification Section)";
CM_ SG_ 1202 VIS_5 "Cinqiueme caractere de VIS";
CM_ SG_ 1202 VIS_6 "Sixieme caractere de VIS";
CM_ SG_ 1202 VIS_7 "Septieme caractere de VIS";
CM_ SG_ 1202 VIS_8 "Huitieme caractere de VIS";
CM_ SG_ 1202 VIS_4 "Quatrieme caractere de VIS";
CM_ SG_ 1202 VIS_1 "Premier caractere de VIS";
CM_ SG_ 1202 VIS_2 "Second caractere de VIS";
CM_ SG_ 1202 VIS_3 "Troisieme caractere de VIS";
CM_ BO_ 1234 "Trame WMI d'identification de la marque de la voiture (World Manufacturer Identifier)";
CM_ SG_ 1234 WMI_1 "Premier caractere de WMI";
CM_ SG_ 1234 WMI_2 "Second caractere de WMI";
CM_ SG_ 1234 WMI_3 "Troisieme caractere de WMI";
CM_ BO_ 1294 "trame mixte : périodique à 100 ms et sur événements :
     Changement de consigne de vitesse vehicule
     Demande d'activation RVV / ACC
     Demande d'activation LVV";
CM_ SG_ 1294 DEM_RAL_HAB "Permet de démander une augmentatrion du ralenti pour les besoins habitacle (ex: climatisation)";
CM_ SG_ 1294 TYPE_REGUL_LONGI "Définit si on est en LVV ou RVV ou ACC ou sans régulation.";
CM_ SG_ 1294 CHKSUM_CONS_RVV_LVV "Sert à sécuriser la consigne RVV ou consigne LVV émise par le réseau CAN (signal CONS_LIM_VITESSE_VEH)";
CM_ SG_ 1294 FORCAGE_ENCL_BOUGIES "Le but est de charger le moteur dans des conditions de régime et de charge trop faible. On facilite la régénération en enclenchant les bougies de préchauffage";
CM_ SG_ 1294 CONS_LIM_VITESSE_VEH "Consigne ou limite : selon la valeur du bit 'type de Vitesse V demandée'";
CM_ SG_ 1294 NIV_DELESTAGE_SEV "Niveau de délestage des gros consommateurs déterminé par le superviseur d'énergie électrique véhicule.";
CM_ SG_ 1294 DDE_HABITACLE_SG "Décrit le besoin en énergie à fournir par le moteur thermique pour les besoins habitacle (climatisation..)";
CM_ SG_ 1294 CONSIGNE_GMV "Utilisé dans le cadre du FAP pour charger le moteur depuis la BSI par actionnement des GMV";
CM_ SG_ 1362 KILOMETRAGE "Kilométrage absolu parcouru par le véhicule (en cohérence avec l'indication donnée au conducteur)";
CM_ SG_ 1362 CPT_TEMPOREL "0xFFFFFFFE : indisponible";
CM_ SG_ 1362 COMPTEUR_RAZ_GCT "Indisponible FE";
CM_ BO_ 1375 "Trame d'acquittement du journal des défauts BSI.";
CM_ BO_ 1389 "Emise vers le tricapteur Bosch pour réponse de celui-ci dans la trame 579h";
CM_ BO_ 1420 "Trame Réponse pour le téléchargement et le Diag On CAN réservé pour bi capteur.";
CM_ SG_ 1426 ETAT_ESSUYAGE "Emis si capteur de pluie";
CM_ SG_ 1426 DEFAUT_SYST_COMMUT "Indique une défaillance de la ligne filaire CDE_ALIM_FSE et du système de commutation (CPC,BPGA,...)";
CM_ BO_ 1452 "Trame question pour le téléchargement et le Diag On CAN réservé pour le calculateur ACC .";
CM_ BO_ 1455 "Trame Réponse pour le téléchargement et le Diag On CAN réservé pour bi capteur.";
CM_ BO_ 1456 "Trame question pour le téléchargement et le Diag On CAN réservé pour le calculateur ACC .";
CM_ BO_ 1484 "Cette trame regroupe les données d'instrumentation qui permettent de juger de la qualité de la transmission ainsi que de déterminer si un défaut au moins est présent sur le calculateur. Cette trame n'est pas impliquée dans le fonctionnement des calculateurs en mode normal.";
CM_ SG_ 1484 CODE_DEFAUT "Etat de la memoire diagnostic du systeme";
CM_ SG_ 1484 ETAT_ELECTR_UCE "Phase de vie de l'UCE (RCD)";
CM_ SG_ 1484 STATUS_REVEIL_PARTIEL_GMP "Ce flag permet a chaque UCE d'indiquer quel(s) reveil(s) partiel(s) est (sont) activé(s) ou non. Cela s'applique aussi bien pour les UCEs maîtres de reveil partiel et pour les UCEs esclaves (= les UCEs a reveilller).
Les signaux ont toutes les combinaisons possibles";
CM_ SG_ 1484 STATUS_CONFABSENT "Recopie des flags de status des calculateurs supervises, information ConfirmedAbsent (Se reporter à la spécification du diagnostic de communication). Pour chaque calculateur, le bit prend la valeur 0 si le calculateur est present, ou 1 s'il est Confirmed Absent.
Si une UCE n'est pas supervisée, on place par défaut le bit correspondant à 0.";
CM_ BO_ 1487 "Trame Réponse pour le téléchargement et le Diag On CAN réservé pour bi capteur.";
CM_ BO_ 1488 "Trame question pour le téléchargement et le Diag On CAN réservé pour le calculateur ACC .";
CM_ BO_ 1489 "Cette trame regroupe les données d'instrumentation qui permettent de juger de la qualité de la transmission ainsi que de déterminer si un défaut au moins est présent sur le calculateur. Cette trame n'est pas impliquée dans le fonctionnement des calculateurs en mode normal.";
CM_ SG_ 1489 CODE_DEFAUT "Etat de la memoire diagnostic du systeme";
CM_ SG_ 1489 ETAT_ELECTR_UCE "Phase de vie de l'UCE (RCD)";
CM_ SG_ 1489 STATUS_REVEIL_PARTIEL_LAS "Ce flag permet a chaque UCE d'indiquer quel(s) reveil(s) partiel(s) est (sont) activé(s) ou non. Cela s'applique aussi bien pour les UCEs maîtres de reveil partiel et pour les UCEs esclaves (= les UCEs à reveilller).";
CM_ SG_ 1489 STATUS_CONFABSENT "Recopie des flags de status des calculateurs supervises, information ConfirmedAbsent (Se reporter à la spécification du diagnostic de communication). Pour chaque calculateur, le bit prend la valeur 0 si le calculateur est present, ou 1 s'il est Confirmed Absent.
Si une UCE n'est pas supervisée, on place par défaut le bit correspondant à 0.";
CM_ BO_ 1516 "Trame d'émission du journal des défauts du calculateur DIRA ou GEP.";
CM_ SG_ 1516 CODES_DEFAUT "Le codage du défaut correspond à :
Octet 1 : MSB,
Octet 2 : LSB,
Octet 3 : 0x00.";
CM_ SG_ 1516 KILOMETRAGE_JDD "Kilométrage absolu parcouru par le véhicule (en cohérence avec l'indication donnée au conducteur)";
CM_ SG_ 1516 SITUATION_VIE_JDD "Décrit dans la ST JDD SOUS_CAPOT";
CM_ BO_ 1519 "Trame d'émission du journal des défauts du calculateur DIRA ou GEP.";
CM_ SG_ 1519 CODES_DEFAUT "Le codage du défaut correspond à :
Octet 1 : MSB,
Octet 2 : LSB,
Octet 3 : 0x00.";
CM_ SG_ 1519 KILOMETRAGE_JDD "Kilométrage absolu parcouru par le véhicule (en cohérence avec l'indication donnée au conducteur)";
CM_ SG_ 1519 SITUATION_VIE_JDD "Décrit dans la ST JDD SOUS_CAPOT";
CM_ BO_ 1520 "Cette trame regroupe les données d'instrumentation qui permettent de juger de la qualité de la transmission ainsi que de déterminer si un défaut au moins est présent sur le calculateur. Cette trame n'est pas impliquée dans le fonctionnement des calculateurs en mode normal.";
CM_ SG_ 1520 CODE_DEFAUT "Etat de la memoire diagnostic du systeme";
CM_ SG_ 1520 ETAT_ELECTR_UCE "Phase de vie de l'UCE (RCD)";
CM_ SG_ 1520 STATUS_REVEIL_PARTIEL_LAS "Ce flag permet a chaque UCE d'indiquer quel(s) reveil(s) partiel(s) est (sont) activé(s) ou non. Cela s'applique aussi bien pour les UCEs maîtres de reveil partiel et pour les UCEs esclaves (= les UCEs à reveilller).";
CM_ SG_ 1520 STATUS_CONFABSENT "Recopie des flags de status des calculateurs supervises, information ConfirmedAbsent (Se reporter à la spécification du diagnostic de communication). Pour chaque calculateur, le bit prend la valeur 0 si le calculateur est present, ou 1 s'il est Confirmed Absent.
Si une UCE n'est pas supervisée, on place par défaut le bit correspondant à 0.";
CM_ BO_ 1521 "Trame d'émission du journal des défauts du calculateur DIRA ou GEP.";
CM_ SG_ 1521 CODES_DEFAUT "Le codage du défaut correspond à :
Octet 1 : MSB,
Octet 2 : LSB,
Octet 3 : 0x00.";
CM_ SG_ 1521 KILOMETRAGE_JDD "Kilométrage absolu parcouru par le véhicule (en cohérence avec l'indication donnée au conducteur)";
CM_ SG_ 1521 SITUATION_VIE_JDD "Décrit dans la ST JDD SOUS_CAPOT";
CM_ BO_ 1686 "Trame Réponse pour le téléchargement et le Diag On CAN réservé pour le calculateur ACC.";
CM_ BO_ 1689 "Trame Réponse pour le téléchargement et le Diag On CAN réservé pour bi capteur.";
CM_ BO_ 1693 "Trame Réponse pour le téléchargement et le Diag On CAN.";
CM_ BO_ 1718 "Trame question pour le téléchargement et le Diag On CAN réservé pour le calculateur ACC .";
CM_ BO_ 1721 "Trame question pour le téléchargement et le Diag On CAN réservé pour le bi capteur .";
CM_ BO_ 1910 "Trame d'émission du journal des défauts du calculateur DIRA ou GEP.";
CM_ SG_ 1910 CODES_DEFAUT "Le codage du défaut correspond à :
Octet 1 : MSB,
Octet 2 : LSB,
Octet 3 : 0x00.";
CM_ SG_ 1910 KILOMETRAGE_JDD "Kilométrage absolu parcouru par le véhicule (en cohérence avec l'indication donnée au conducteur)";
CM_ SG_ 1910 SITUATION_VIE_JDD "Décrit dans la ST JDD SOUS_CAPOT";
CM_ BO_ 1917 "Trame d'émission du journal des défauts du calculateur DIRA ou GEP.";
CM_ SG_ 1917 CODES_DEFAUT "Le codage du défaut correspond à :
Octet 1 : MSB,
Octet 2 : LSB,
Octet 3 : 0x00.";
CM_ SG_ 1917 KILOMETRAGE_JDD "Kilométrage absolu parcouru par le véhicule (en cohérence avec l'indication donnée au conducteur)";
CM_ SG_ 1917 SITUATION_VIE_JDD "Décrit dans la ST JDD SOUS_CAPOT";
CM_ BO_ 1938 "Cette trame regroupe les données d'instrumentation qui permettent de juger de la qualité de la transmission ainsi que de déterminer si un défaut au moins est présent sur le calculateur et renseigne la phase de vie du calculateur (RCD). Cette trame n'est pas impliquée dans le fonctionnement des calculateurs en mode normal.";
CM_ SG_ 1938 CODE_DEFAUT "Etat de la memoire diagnostic du systeme";
CM_ SG_ 1938 STATUS_REVEIL_PARTIEL "Ce flag permet a chaque UCE d indiquer quel(s) reveil(s) partiel(s) est (sont) activé(s) ou non. Cela s'applique aussi bien pour les UCEs maîtres de reveil partiel et pour les UCEs esclaves (= les UCEs a reveilller).";
CM_ SG_ 1938 ETAT_ELECTR_UCE "Phase de vie de l'UCE (RCD)";
CM_ SG_ 1938 STATUS_CONFABSENT "Recopie des flags de status des calculateurs supervises, information ConfirmedAbsent (Se reporter à la spécification du diagnostic de communication). Pour chaque calculateur, le bit prend la valeur 0 si le calculateur est present, ou 1 s'il est Confirmed Absent.
Si une UCE n'est pas supervisée, on place par défaut le bit correspondant à 0.";
CM_ BO_ 1942 "Cette trame regroupe les données d'instrumentation qui permettent de juger de la qualité de la transmission ainsi que de déterminer si un défaut au moins est présent sur le calculateur. Cette trame n'est pas impliquée dans le fonctionnement des calculateurs en mode normal.";
CM_ SG_ 1942 CODE_DEFAUT "Etat de la memoire diagnostic du systeme";
CM_ SG_ 1942 ETAT_ELECTR_UCE "Phase de vie de l'UCE (RCD)";
CM_ SG_ 1942 STATUS_REVEIL_PARTIEL_GMP "Ce flag permet a chaque UCE d'indiquer quel(s) reveil(s) partiel(s) est (sont) activé(s) ou non. Cela s'applique aussi bien pour les UCEs maîtres de reveil partiel et pour les UCEs esclaves (= les UCEs a reveilller).
Les signaux ont toutes les combinaisons possibles";
CM_ SG_ 1942 STATUS_CONFABSENT "Recopie des flags de status des calculateurs supervises, information ConfirmedAbsent (Se reporter à la spécification du diagnostic de communication). Pour chaque calculateur, le bit prend la valeur 0 si le calculateur est present, ou 1 s'il est Confirmed Absent.
Si une UCE n'est pas supervisée, on place par défaut le bit correspondant à 0.";
CM_ SG_ 1949 CODE_DEFAUT "Etat de la memoire diagnostic du systeme";
CM_ SG_ 1949 ETAT_ELECTR_UCE "Phase de vie de l'UCE (RCD)";
CM_ SG_ 1949 STATUS_CONFABSENT "Recopie des flags de status des calculateurs supervises, information ConfirmedAbsent (Se reporter à la spécification du diagnostic de communication). Pour chaque calculateur, le bit prend la valeur 0 si le calculateur est present, ou 1 s'il est Confirmed Absent.
Si une UCE n'est pas supervisée, on place par défaut le bit correspondant à 0.";
BA_DEF_ BO_  "ModeTransmission" ENUM  "P","E","P+E";
BA_DEF_ BO_  "Période" INT 0 0;
BA_DEF_DEF_  "ModeTransmission" "P";
BA_DEF_DEF_  "Période" 100;
BA_ "Période" BO_ 146 0;
BA_ "ModeTransmission" BO_ 146 1;
BA_ "Période" BO_ 238 0;
BA_ "ModeTransmission" BO_ 238 1;
BA_ "Période" BO_ 239 0;
BA_ "ModeTransmission" BO_ 239 1;
BA_ "Période" BO_ 274 0;
BA_ "ModeTransmission" BO_ 274 1;
BA_ "Période" BO_ 278 0;
BA_ "ModeTransmission" BO_ 278 1;
BA_ "Période" BO_ 285 0;
BA_ "ModeTransmission" BO_ 285 1;
BA_ "Période" BO_ 300 0;
BA_ "ModeTransmission" BO_ 300 1;
BA_ "Période" BO_ 525 10;
BA_ "Période" BO_ 551 10;
BA_ "Période" BO_ 552 10;
BA_ "Période" BO_ 557 20;
BA_ "Période" BO_ 584 10;
BA_ "Période" BO_ 632 10;
BA_ "Période" BO_ 642 10;
BA_ "Période" BO_ 653 10;
BA_ "Période" BO_ 664 20;
BA_ "Période" BO_ 690 20;
BA_ "Période" BO_ 694 20;
BA_ "Période" BO_ 696 20;
BA_ "Période" BO_ 717 20;
BA_ "Période" BO_ 728 20;
BA_ "Période" BO_ 744 20;
BA_ "Période" BO_ 758 20;
BA_ "Période" BO_ 760 20;
BA_ "Période" BO_ 761 10;
BA_ "Période" BO_ 792 20;
BA_ "Période" BO_ 802 20;
BA_ "Période" BO_ 809 20;
BA_ "Période" BO_ 813 20;
BA_ "Période" BO_ 845 20;
BA_ "Période" BO_ 905 40;
BA_ "Période" BO_ 909 40;
BA_ "Période" BO_ 946 40;
BA_ "Période" BO_ 952 40;
BA_ "Période" BO_ 968 20;
BA_ "Période" BO_ 1001 50;
BA_ "Période" BO_ 1032 40;
BA_ "Période" BO_ 1069 50;
BA_ "Période" BO_ 1074 50;
BA_ "Période" BO_ 1080 50;
BA_ "Période" BO_ 1106 50;
BA_ "Période" BO_ 1170 1000;
BA_ "Période" BO_ 1202 1000;
BA_ "Période" BO_ 1234 1000;
BA_ "ModeTransmission" BO_ 1294 2;
BA_ "Période" BO_ 1356 200;
BA_ "ModeTransmission" BO_ 1356 2;
BA_ "Période" BO_ 1362 1000;
BA_ "ModeTransmission" BO_ 1362 2;
BA_ "Période" BO_ 1375 0;
BA_ "ModeTransmission" BO_ 1375 1;
BA_ "Période" BO_ 1389 0;
BA_ "ModeTransmission" BO_ 1389 1;
BA_ "ModeTransmission" BO_ 1393 2;
BA_ "Période" BO_ 1401 0;
BA_ "ModeTransmission" BO_ 1401 1;
BA_ "Période" BO_ 1420 0;
BA_ "ModeTransmission" BO_ 1420 1;
BA_ "Période" BO_ 1448 1000;
BA_ "ModeTransmission" BO_ 1448 2;
BA_ "Période" BO_ 1449 1000;
BA_ "Période" BO_ 1452 0;
BA_ "ModeTransmission" BO_ 1452 1;
BA_ "Période" BO_ 1455 0;
BA_ "ModeTransmission" BO_ 1455 1;
BA_ "Période" BO_ 1456 0;
BA_ "ModeTransmission" BO_ 1456 1;
BA_ "Période" BO_ 1464 1000;
BA_ "Période" BO_ 1484 1000;
BA_ "ModeTransmission" BO_ 1484 2;
BA_ "Période" BO_ 1487 0;
BA_ "ModeTransmission" BO_ 1487 1;
BA_ "Période" BO_ 1488 0;
BA_ "ModeTransmission" BO_ 1488 1;
BA_ "Période" BO_ 1489 1000;
BA_ "ModeTransmission" BO_ 1489 2;
BA_ "Période" BO_ 1490 1000;
BA_ "ModeTransmission" BO_ 1490 2;
BA_ "Période" BO_ 1496 1000;
BA_ "Période" BO_ 1516 0;
BA_ "ModeTransmission" BO_ 1516 1;
BA_ "Période" BO_ 1517 300;
BA_ "Période" BO_ 1518 1000;
BA_ "ModeTransmission" BO_ 1518 2;
BA_ "Période" BO_ 1519 0;
BA_ "ModeTransmission" BO_ 1519 1;
BA_ "Période" BO_ 1520 1000;
BA_ "ModeTransmission" BO_ 1520 2;
BA_ "Période" BO_ 1521 0;
BA_ "ModeTransmission" BO_ 1521 1;
BA_ "Période" BO_ 1686 0;
BA_ "ModeTransmission" BO_ 1686 1;
BA_ "Période" BO_ 1689 0;
BA_ "ModeTransmission" BO_ 1689 1;
BA_ "Période" BO_ 1693 0;
BA_ "ModeTransmission" BO_ 1693 1;
BA_ "Période" BO_ 1718 0;
BA_ "ModeTransmission" BO_ 1718 1;
BA_ "Période" BO_ 1721 0;
BA_ "ModeTransmission" BO_ 1721 1;
BA_ "Période" BO_ 1725 0;
BA_ "ModeTransmission" BO_ 1725 1;
BA_ "Période" BO_ 1910 0;
BA_ "ModeTransmission" BO_ 1910 1;
BA_ "Période" BO_ 1917 0;
BA_ "ModeTransmission" BO_ 1917 1;
BA_ "Période" BO_ 1938 1000;
BA_ "ModeTransmission" BO_ 1938 2;
BA_ "Période" BO_ 1942 1000;
BA_ "Période" BO_ 1949 1000;
BA_ "ModeTransmission" BO_ 1949 2;
BA_ "Période" BO_ 2047 0;
BA_ "ModeTransmission" BO_ 2047 1;
VAL_ 146 EFFAC_DEFAUT_DIAG 0 "Pas d'action spécifique" 1 "Effacement mémoire des défauts" ;
VAL_ 146 DIAG_INTEGRA_ELEC 0 "Pas de fonctionnement particulier" 1 "Pas de transmission de trames" ;
VAL_ 146 MODE_DIAG 0 "Pas de fonctionnement particulier" 1 "Inhibition du fonctionnel et de la communication" ;
VAL_ 525 REGUL_ABR 0 "Non en régulation" 1 "En régulation" ;
VAL_ 525 PFC_STRATEGY_ACT 0 "PFC_inactive" 1 "PFC_hold" 2 "PFC_active" 3 "Réservé" ;
VAL_ 551 SENS_ROT_MOT_AR_HYB 0 "indéterminé" 1 "avant" 2 "arrière" 3 "invalide" ;
VAL_ 551 ETAT_CPLAGE_AR_HYB 0 "désengagé" 1 "engagé" ;
VAL_ 551 CHGT_RAP_AR_EN_COURS_HYB 0 "pas de changement en cours" 1 "changement en cours" ;
VAL_ 551 ACQ_ASR_MSR_AR_HYB 0 "problème de dialogue" 1 "dialogue correct" ;
VAL_ 551 ETAT_DDE_ACCEL_HYB 0 "IVC négatif" 1 "IVC positif" ;
VAL_ 551 POS_LEV_VALID_GMP_HYB 0 "reservé" 1 "marche arrière" 2 "neutre" 3 "automatique" 4 "manuel" 5 "réservé" 6 "réservé" 7 "réservé" ;
VAL_ 551 MD_NRJ_ROUTE 0 "pas de mode dégradé" 1 "mode dégradé en cours" ;
VAL_ 551 ACQ_ASR_MSR 0 "Problème de dialogue" 1 "Dialogue correct" ;
VAL_ 552 IND_ENG_SPD_OVRFLWD 0 "régime non filtrée inférieur au seuil" 1 "réservé" 2 "régime non filtrée supérieur au seuil" 3 "Indisponible" ;
VAL_ 552 POINT_DUR_SECU 0 "Point dur non franchi" 1 "Point dur franchi" ;
VAL_ 552 CPLE_DISPO_HILL_ASSIST 0 "Couple indisponible" 1 "Couple disponible" ;
VAL_ 552 CPLE_MOT_PRECIS 0 "Couple imprécis" 1 "Couple précis" ;
VAL_ 552 FREEWHEELING_REQ 0 "Hors intervention" 1 "Demande de FreeWheeling au Neutre" 2 "Demande de FreeWheeling Déponté" 3 "Non utilisé" ;
VAL_ 552 CPLE_EM_INCERTAIN 0 "Info couple Easy move garantie avec la précision requise" 1 "Info couple Easy move non garantie avec la précision requise" 2 "Réservé" 3 "Réservé" ;
VAL_ 552 AUTORISATION_RDT 0 "Reduction de trainée Non autorisé" 1 "Reduction de trainée autorisé" ;
VAL_ 557 DDE_INHIB_CPLE_AR_HYB 0 "Pas de demande" 1 "Inhibition de couple arrière demandée" ;
VAL_ 557 DDE_FIG_REPART_CPLE_HYB 0 "Pas de demande" 1 "Demande de figeage" ;
VAL_ 557 TYPE_PIL_CPLE_ESP_AR_HYB 0 "Pas d'action sur le couple" 1 "Interdit" 2 "Interdit" 3 "Interdit" 4 "Interdit" 5 "Consigne de réduction (ASR)" 6 "Consigne d'augmentation (MSR)" 7 "Interdit" ;
VAL_ 557 DDE_OUVERT_CPLE_AR_HYB 0 "Pas de demande" 1 "Demande d'ouverture" ;
VAL_ 557 DDE_FIG_COUPLAGE_AR_HYB 0 "Pas de demande" 1 "Demande de figeage" ;
VAL_ 584 ETAT_PASSAGE_JEU_AGR 0 "Détection inactif" 1 "Détection en cours" 2 "Détection effective" 3 "Fin de détection" ;
VAL_ 653 PRE_REGUL_ASR_AR_HYB 0 "Pas de pré-régulation" 1 "Pré-régulation en cours" ;
VAL_ 653 DDE_INHIB_CPLE_AR_HYB 0 "Pas de demande" 1 "Inhibition de couple arrière demandée" ;
VAL_ 653 DDE_DEM_MTH_VIDE_HYB 0 "Pas de demande" 1 "Demande de démarrage" ;
VAL_ 653 DDE_FIG_REPART_CPLE_HYB 0 "Pas de demande" 1 "Demande de figeage" ;
VAL_ 653 TYPE_PIL_CPLE_ESP_AR_HYB 0 "Pas d'action sur le couple" 1 "Interdit" 2 "Interdit" 3 "Interdit" 4 "Interdit" 5 "Consigne de réduction (ASR)" 6 "Consigne d'augmentation (MSR)" 7 "Interdit" ;
VAL_ 653 AUTORIS_STOP_VIDE_HYB 0 "Pas d'autorisation de stop" 1 "Stop autorisé" ;
VAL_ 653 DDE_OUVERT_CPLE_AR_HYB 0 "Pas de demande" 1 "Demande d'ouverture" ;
VAL_ 653 DDE_FIG_COUPLAGE_AR_HYB 0 "Pas de demande" 1 "Demande de figeage" ;
VAL_ 664 REGEN_BRAKING_STATE 0 "OK" 1 "NOK" ;
VAL_ 690 DIAG_MUX_ON 0 "Pas de diagnostic de communication" 1 "Diagnostic de communication actif" ;
VAL_ 690 ETAT_RVV_LVV 0 "RVV en attente / LVV attente - LVV non effective" 1 "Reprise pédale d'accélérateur RVV / Reprise pédale d'accélérateur LVV" 2 "RVV active / LVV effective" 3 "RVV inhibée / LVV inhibée" ;
VAL_ 690 ETAT_MT 0 "Verrouillé" 1 "Coupé calé" 2 "Démarrage entrainé" 3 "Moteur tournant" 4 "Arrêté" 5 "Redémarrage entrainé" 6 "Redémarrage dégradé" 7 "En préparation" 8 "Réservé" 9 "Réservé" 10 "Démarrage autonome" 11 "Réservé" 12 "Réservé" 13 "Redémarrage autonome" 14 "Réservé" 15 "Invalide" ;
VAL_ 694 DMD_PLT_DECEL_MDD 0 "pas de demande de pilotage UCF" 1 "demande de pilotage UCF" ;
VAL_ 694 TYPE_DECEL_MDD 0 "pas de Freinage" 1 "ACC" 2 "FA_HV (freinage automatique haute vitesse) / Freinage AFUi" 3 "FA_BV (freinage automatique basse vitesse) / Freinage FARC2" ;
VAL_ 694 DDE_ACT_CPL_ROUE 0 "Non demandé" 1 "Demandé plage haute" 2 "Demandé plage basse" 3 "Non utilisé" ;
VAL_ 694 DDE_PREFILL 0 "Pas de demande de Prefill" 1 "Demande de Prefill" ;
VAL_ 694 TYPE_RAPPORT 0 "Descendant" 1 "Montant" ;
VAL_ 694 ETAT_ACC 0 "Initialisation" 1 "OFF" 2 "Inhibé" 3 "Attente" 4 "Actif" 5 "Suspendu" 6 "Frein seul" 7 "Rampe attente" 8 "Réservé" 9 "Réservé" 10 "Réservé" 11 "Réservé" 12 "Réservé" 13 "Réservé" 14 "Réservé" 15 "Défaut" ;
VAL_ 694 DDE_ACT_POT_CPL_ROUE 0 "Non demandé" 1 "Demandé mode GMP" 2 "Demandé mode Frein" 3 "Non utilisé" ;
VAL_ 694 FA_ETAT_FA 0 "indisponible" 1 "initialisation" 2 "valeur non utilisée" 3 "inhibé" 4 "valeur non utilisée" 5 "attente" 6 "actif" 7 "défaut" ;
VAL_ 728 ACC_INHIB_SUR_REGIME 0 "pas d'inhibition" 1 "inhibition demandée" ;
VAL_ 728 ETAT_ACC_CMM 0 "Arrêt" 1 "Initialisation" 2 "Inhibé" 3 "Attente" 4 "Actif non effectif" 5 "Actif effectif" 6 "Reservé" 7 "Défaut" ;
VAL_ 744 CNS_RAP_GMP_MAX 0 "Valeur de repli basse" 1 "1 ère" 2 "2 eme" 3 "3 eme" 4 "4 eme" 5 "5 eme" 6 "6 eme" 7 "7 eme" 8 "8 eme" 9 "Réservé" 10 "Réservé" 11 "Réservé" 12 "Réservé" 13 "Réservé" 14 "Réservé" 15 "Valeur de repli haute" ;
VAL_ 744 ETAT_MT_STT 0 "Init" 1 "Actif" 2 "Preparation_Stop" 3 "Stop_Arret_En_Cours" 4 "Moteur_Arrete" 5 "Redem_sous_MEL" 6 "Redem_Autonome" 7 "Moteur_Apte_Fournir_Couple" 8 "Coupe" 9 "Cale" 10 "Réservé" 11 "Réservé" 12 "Réservé" 13 "Réservé" 14 "Réservé" 15 "Réservé" ;
VAL_ 744 STS_PIL_TRANS_GMP 0 "Pilotage non demandé" 1 "Pilotage demandé ou demandé mode 1" 2 "Pilotage demandé en mode Fullpass ou demandé mode 2" 3 "Réservé ou demandé mode 3" ;
VAL_ 744 CNS_RAP_GMP_MIN 0 "Valeur de repli basse" 1 "1 ère" 2 "2 eme" 3 "3 eme" 4 "4 eme" 5 "5 eme" 6 "6 eme" 7 "7 eme" 8 "8 eme" 9 "Réservé" 10 "Réservé" 11 "Réservé" 12 "Réservé" 13 "Réservé" 14 "Réservé" 15 "Valeur de repli haute" ;
VAL_ 744 CURRENT_GBX_DYN_MODE 0 "Normal" 1 "Sport" 2 "Eco" 3 "Neige" ;
VAL_ 744 CTRL_CPLE_GMP_ACT 0 "Faux" 1 "Vrai" ;
VAL_ 758 DMD_ALRT_COL_VISU_ARC 0 "pas de demande alerte visuelle" 1 "demande alerte visuelle" ;
VAL_ 758 ARC_ETAT_ARC 0 "indisponible" 1 "Valeur non utilisée" 2 "Valeur non utilisée" 3 "initialisation" 4 "Valeur non utilisée" 5 "Valeur non utilisée" 6 "inhibé" 7 "Valeur non utilisée" 8 "Valeur non utilisée" 9 "Valeur non utilisée" 10 "attente" 11 "Valeur non utilisée" 12 "actif" 13 "Valeur non utilisée" 14 "Valeur non utilisée" 15 "défaut" ;
VAL_ 758 AEB_ENABLED 0 "FALSE" 1 "TRUE" ;
VAL_ 758 DMD_PLT_DECEL_MDD 0 "pas de demande de pilotage UCF" 1 "demande de pilotage UCF" ;
VAL_ 758 DDE_REPRISE_COND 0 "Pas de demande" 1 "Demande non critique" 2 "Demande critique" 3 "Invalide" ;
VAL_ 758 CIBLE_DETECTEE 0 "initialisation ou pas de cible détectée" 1 "cible détectée" ;
VAL_ 758 DMD_ALRT_COL_SON_ARC 0 "pas de demande alerte sonore" 1 "demande alerte sonore" ;
VAL_ 758 DMD_ALRT_COL_HAPT_ARC 0 "pas de demande alerte haptique" 1 "demande alerte haptique" ;
VAL_ 758 CAPT_AVEUGLE 0 "Faux" 1 "Vrai" ;
VAL_ 758 DRV_AWAY_REQ 0 "No drive away required" 1 "Drive away required" ;
VAL_ 758 FA_ETAT_FA 0 "indisponible" 1 "initialisation" 2 "valeur non utilisée" 3 "inhibé" 4 "valeur non utilisée" 5 "attente" 6 "actif" 7 "défaut" ;
VAL_ 758 FA_INFO_FRN_EN_COURS 0 "pas de freinage en cours" 1 "freinage en cours" ;
VAL_ 758 TARGET_POSITION 0 "POS1" 1 "POS2" 2 "POS3" 3 "POS4" 4 "POS5" 5 "POS6" 6 "POS7" 7 "Invalide" ;
VAL_ 761 ETAT_ACCEL_LONGI_BRUTE_RB 0 "Signal dans la plage de mesure" 1 "Erreur temporaire" 2 "Erreur permanente" 3 "Capteur en cours d'initialisation" ;
VAL_ 761 SOUSTENSION_SURTENSION_RB 0 "Pas de sous tension / Surtension détectée" 1 "Sous tension / Surtension détectée" ;
VAL_ 761 ETAT_ACCEL_LAT_BRUTE_RB 0 "Signal dans la plage de mesure" 1 "Erreur temporaire" 2 "Erreur permanente" 3 "Capteur en cours d'initialisation" ;
VAL_ 761 ETAT_VITESSE_LACET_BRUTE_RB 0 "Signal dans la plage de mesure" 1 "Erreur temporaire" 2 "Erreur permanente" 3 "Capteur en cours d'initialisation" ;
VAL_ 761 ERR_INTERNE_RB 0 "Pas d'erreur de traitement interne détectée" 1 "Erreur de traitement interne détectée" ;
VAL_ 792 DISP_XVV_GMP_ACTIF 0 "Non active" 1 "Active" ;
VAL_ 792 DISP_XVV_BV_EN_PRISE 0 "Non active" 1 "Active" ;
VAL_ 792 DISP_XVV_CDT_FERMEE 0 "Non active" 1 "Active" ;
VAL_ 792 CPLE_ACC_EFFECTIF 0 "Le couple demandé par le MDD n'est pas réalisé (Couple conducteur réalisé)" 1 "Le couple demandé par le MDD est réalisé" ;
VAL_ 802 CDA_REQUEST 0 " Pas_de_dde_CDA" 1 "Requete_fonction_CDA" ;
VAL_ 802 RESIDUAL_PRESS_STRATEGY 0 "RPR_Passive" 1 "RPR_Preload" 2 "RPR_Hold" 3 "RPR_Suction" 4 "RPR_HoldLowPressure" 5 "RPR_Abort" 6 "Réservé" 7 "Réservé" ;
VAL_ 802 EBDIAGACTIVE 0 "Diagnostic iBooster inactif" 1 "Diagnostic iBooster actif" ;
VAL_ 802 EBB_BRAKE_PDLE_STATE 0 "Indisponible" 1 "Pédale de frein relâchée" 2 "Pédale de frein enfoncée" 3 "Invalide" ;
VAL_ 809 DEFAUT_STT_BV 0 "Nominal" 1 "Défaut BV identifié STT" ;
VAL_ 809 PADDLES_STATE 0 "Pas d'action palettes" 1 "Action sur palette +" 2 "Action sur palette -" 3 "Action simultanée sur les deux palettes" ;
VAL_ 809 INHIB_STOP_BV 0 "Pas d'inhibition du Stop moteur" 1 "Inhibition du Stop moteur" ;
VAL_ 809 AUTOR_STOP_BV_ETENDU 0 "Interdiction durée indeterminée" 1 "Autorisation" 2 "Interdiction durée moyenne" 3 "Interdiction durée longue" ;
VAL_ 809 BV_STATE_STT 0 "opération normale" 1 "préparation arrêt moteur" 2 "arrêt moteur en cours" 3 "Stop" 4 "cranking" 5 "démarrage" 6 "transmission de couple" 7 "Réservé" ;
VAL_ 809 POS_LEVIER_P_N 0 "Réservé" 1 "Position N (Neutre) ou P (Park)" 2 "Hors position N (Neutral) ou P (Park)" 3 "Capteur de position du levier hors service ou indisponible" ;
VAL_ 809 AUTOR_REDEM_BV 0 "Redémarrage interdit" 1 "Redemarrage autorisé" ;
VAL_ 809 AUTOR_STOP_BV 0 "Pas d'autorisation de stop" 1 "Autorisation de stop" ;
VAL_ 809 DMD_REDEM_BV 0 "Pas de besoin de redémarrage" 1 "Demande de redémarrage" ;
VAL_ 813 FA_ETAT_DECEL 0 "Inhibé" 1 "Attente" 2 "Active" 3 "En défaut" ;
VAL_ 813 EFFORT_FREIN 0 "Pas d'effort de freinage généré" 1 "Effort de freinage généré" ;
VAL_ 813 PREFILL_EN_COURS 0 "Faux" 1 "Vrai" ;
VAL_ 813 DEFAUT_ACC_FREIN 0 "Pas de défaut ACC vue du frein" 1 "Défaut ACC vue du frein" ;
VAL_ 813 VEHICLE_STANDSTILL 0 "NO_VEHICLE_STANDSTILL" 1 "VEHICLE_STANDSTILL" ;
VAL_ 813 VAL_INFO_VIT_LACET 0 "Information Valide" 1 "Information Invalide" ;
VAL_ 813 APPUI_FREIN_RECONSTRUIT 0 "Appui frein reconstruit HS" 1 "Pas d'appui pédale de frein" 2 "Appui pédale de frein" 3 "Réservé" ;
VAL_ 813 ACC_ETAT_DECEL 0 "Inhibé" 1 "Attente" 2 "Active" 3 "En défaut" ;
VAL_ 813 EFFORT_FREIN_ERRONE 0 "Pas d'effort de freinage erroné" 1 "Effort de freinage erroné" ;
VAL_ 813 ARRET_VHL_ADAS 0 "Pas de maintien à l'arrêt véhicule par une fonction ADAS" 1 "Maintien à l'arrêt véhicule pour une fonction de confort" 2 "Maintien à l'arrêt véhicule pour une fonction de de sécurité" 3 "Réservé" ;
VAL_ 813 FREINAGE_DYN_EN_COURS 0 "Pas de freinage dynamique en cours" 1 "Freinage dynamqie en cours" ;
VAL_ 813 BRAKE_RELEASED_FAILSAFE 0 "Pas besoin de relâcher les freins à cause d'une glissade" 1 "L'ESC relâche les freins car il a détecté une glissade" ;
VAL_ 845 CHGT_RAP_AUTORISE 0 "Changement interdit" 1 "Rapport descendant autorisé" 2 "Rapport montant autorisé" 3 "Rapport descendant ou montant autorisé" ;
VAL_ 845 FA_ETAT_DECEL 0 "Inhibé" 1 "Attente" 2 "Active" 3 "En défaut" ;
VAL_ 845 PREFILL_EN_COURS 0 "Faux" 1 "Vrai" ;
VAL_ 845 REGUL_ASR 0 "Non en régulation" 1 "En régulation" ;
VAL_ 845 TYPE_PIL_CPLE_ESP 0 "Pas d'action sur le couple" 1 "Réservé" 2 "Réservé" 3 "Réservé" 4 "Réservé" 5 "Consigne de réduction (ASR)" 6 "Consigne d'augmentation (MSR)" 7 "Réservé" ;
VAL_ 845 REGUL_MSR 0 "Non en régulation" 1 "En régulation" ;
VAL_ 845 ETAT_FNCT_HILL_ASSIST 0 "Pas de maintien Hill Assist en cours" 1 "Maintien Hill Assist en cours" 2 "Réservé" 3 "Défaut" ;
VAL_ 845 ASR_DECONNECTE 0 "Connecté par le conducteur" 1 "Déconnecté par le conducteur" ;
VAL_ 845 REQ_LAMPE_REGUL_ASR_ESP 0 "Pas de demande" 1 "Demande d'allumage" ;
VAL_ 845 REGUL_ESP_SEUL 0 "Non en régulation" 1 "En régulation" ;
VAL_ 845 DDE_LOI_BV_VDC 0 "Pas de demande" 1 "Demande de loi VDC" ;
VAL_ 845 ETAT_ASR_PLUS 0 "ASR+ en Mode ESP OFF" 1 "ASR+ en Mode Normal" 2 "ASR+ en Mode Neige" 3 "ASR+ en Mode Boue" 4 "ASR+ en Mode Sable" 5 "Valeur reservee" 6 "Selecteur ASR+ en defaut" 7 "ESP ASR+ en defaut" ;
VAL_ 845 REGUL_AFU 0 "Non en régulation" 1 "En régulation" ;
VAL_ 845 REGUL_BASR 0 "Non en régulation" 1 "En régulation" ;
VAL_ 845 REQ_LAMPE_DEF_ESP 0 "Pas de demande" 1 "Demande d'allumage" ;
VAL_ 845 REGUL_ESP 0 "Non en régulation" 1 "En régulation" ;
VAL_ 845 ESP_DECONNECTE 0 "Connecté par le conducteur" 1 "Déconnecté par le conducteur" ;
VAL_ 909 VVH_INDISP 0 "Invalide" 1 "Informations vitesses disponible" 2 "Informations vitesses indisponible" 3 "Invalide" ;
VAL_ 909 SENS_ROULAGE 0 "Indéterminé" 1 "Vers l'avant" 2 "Vers l'arrière" 3 "Invalide" ;
VAL_ 909 HADC_SPEED_CONDITION 0 "Condition de vitesse HADC non Ok" 1 "Condition de vitesse HADC Ok" ;
VAL_ 909 HADC_STATUS 0 "HADC non sélectionné" 1 "HADC en attente" 2 "HADC actif" 3 "HADC en régulation de freinage hydraulique" ;
VAL_ 909 HADC_FAULTY 0 "Nominal" 1 "Peu sévère" 2 "Sévère" 3 "Réservé" ;
VAL_ 909 AUTOR_ARRET_HILL_STT 0 "Hill Assist pas prêt pour arrêt" 1 "Hill Assist prêt pour arrêt" ;
VAL_ 909 VHL_MVT 0 "Invalide" 1 "Véhicule roulant" 2 "Véhicule à l'arrêt" 3 "Invalide" ;
VAL_ 909 REQ_LAMPE_WARNING 0 "Pas de demande" 1 "Demande d'allumage" ;
VAL_ 909 HADC_CLUTCH_CONDITION 0 "Pas de condition Clutch activé" 1 "Fonction clutch possible" 2 "Fonction clutch active" 3 "Réservé" ;
VAL_ 952 CURRENT_PWT_DYN_CAPABILITY 0 "Mode éco et mode sport disponible" 1 "Mode éco disponible" 2 "Mode sport disponible" 3 "Aucun mode disponible" ;
VAL_ 952 COASTING_STATE 0 "Sans coasting state" 1 "Sailing" 2 "FreeWheeling CdT ouverte" 4 "FreeWheeling CdT Déponté" 8 "OptiPMI" 16 "Reservé" 32 "Réservé" 64 "Réservé" 128 "Réservé" ;
VAL_ 952 COASTING_STATE_SAILING 0 "Sans sailing" 1 "Sailing" ;
VAL_ 952 COASTING_STATE_CDT_OPEN 0 "Sans FreeWheeling CdT ouverte" 1 "FreeWheeling CdT ouverte" ;
VAL_ 952 COASTING_STATE_CDT_DPT 0 "Sans FreeWheeling CdT déponté" 1 "FreeWheeling CdT déponté" ;
VAL_ 952 COASTING_STATE_CDT_OPTIPMI 0 "Sans optiPMI" 1 "OptiPMI" ;
VAL_ 952 COASTING_STATE_RES_4 0 "Réservé inactif" 1 "Réservé actif" ;
VAL_ 952 COASTING_STATE_RES_5 0 "Réservé inactif" 1 "Réservé actif" ;
VAL_ 952 COASTING_STATE_RES_6 0 "Réservé inactif" 1 "Réservé actif" ;
VAL_ 952 COASTING_STATE_RES_7 0 "Réservé inactif" 1 "Réservé actif" ;
VAL_ 968 ETAT_POINT_MORT 0 "Réservé" 1 "Hors point mort" 2 "Point mort" 3 "Invalide" ;
VAL_ 968 DDE_OUV_CDT 0 "Pas de demande" 1 "Demande d'ouverture CDT pour stop" 2 "Réservé" 3 "Réservé" ;
VAL_ 968 TYPE_REDEM 0 "Redémarrage classique" 1 "Redémarrage doux" ;
VAL_ 968 ARRET_MOT_EN_COURS 0 "Pas d'arrêt moteur en cours" 1 "Arrêt moteur en cours" ;
VAL_ 1032 PWT_STATUS_FOR_CPK 0 "Indisponible" 1 "Attente" 2 "Actif" 3 "Réservé" ;
VAL_ 1032 ABORT_CRITICITY_FOR_CPK 0 "Confort" 1 "Urgent" ;
VAL_ 1069 STOP_LIGHTS_ACT_REQ 0 "FAUX" 1 "VRAI" ;
VAL_ 1069 DYN_SLOPE_ACCURACY 0 "Bonne" 1 "Moyenne" 2 "Faible" 3 "Indéfini" ;
VAL_ 1070 REQ_MODE_ESP 0 "Normal" 1 "Neige" 2 "Boue" 3 "Sable" 4 "Réservé" 5 "Réservé" 6 "Réservé" 7 "Réservé" ;
VAL_ 1074 DDE_PREPA_MOTEUR 0 "Pas de demande de préparation moteur" 1 "Demande de préparation moteur" ;
VAL_ 1074 REVEIL_PRINCIPAL 0 "RCD Invalide" 1 "Pas de demande de réveil principal" 2 "Demande de réveil principal" 3 "Invalide" ;
VAL_ 1074 REVEIL_PRECH_UCAPS 0 "Pas de demande de réveil" 1 "Demande de réveil" ;
VAL_ 1074 REVEIL_POST_VENTIL_MOT 0 "Pas de demande de réveil" 1 "Demande de réveil" ;
VAL_ 1074 STATUT_DMD_DEM 0 "Demande nominal" 1 "Demande secondaire" ;
VAL_ 1074 DDE_ARRET_DEMARREUR 0 "Pas de demande d'arrêt démarreur" 1 "Demande d'arrêt démarreur" ;
VAL_ 1074 VOLONTE_DEM_GENE 0 "Valeur non utilisée" 1 "Volonté de démarrer" 2 "Pas de volonté démarrer" 3 "Valeur non utilisée" ;
VAL_ 1074 REVEIL_CH 0 "Pas de demande de réveil" 1 "Demande de réveil" ;
VAL_ 1074 REVEIL_PST_PPL 0 "Pas de demande" 1 "demande" ;
VAL_ 1074 REVEIL_PREPA_STT 0 "Pas de demande de réveil" 1 "Demande de réveil" ;
VAL_ 1074 REVEIL_VVH_UCFREIN 0 "Pas de demande de réveil partiel" 1 "Réveil partiel demandé" ;
VAL_ 1074 DDE_DEM_IMPULSIONNEL 0 "Interdit" 1 "Pas de demande de démarrage impulsionnel" 2 "Demande de démarrage impulsionnel" 3 "Interdit" ;
VAL_ 1074 REVEIL_MES_HUILE_MOT 0 "Pas de demande de réveil" 1 "Demande de réveil" ;
VAL_ 1074 REVEIL_PREPA_GEP 0 "Pas de demande de réveil" 1 "Demande de réveil" ;
VAL_ 1074 REVEIL_SURCHARGE_VHL 0 "Off" 1 "On" ;
VAL_ 1074 ETAT_PRINCIP_SEV 0 "Arret" 1 "Contact" 2 "DEM" 3 "Reserve" ;
VAL_ 1074 DDE_COUP_MT 0 "Interdit" 1 "Pas de demande d'arrêt moteur thermique" 2 "Demande d'arrêt moteur thermique" 3 "Interdit" ;
VAL_ 1074 REVEIL_POWER_LATCH_HYB 0 "Pas de demande reveil power latch" 1 "Demande reveil power latch" ;
VAL_ 1074 ETAT_RESEAU_ELEC 0 "TI_NOMINAL" 1 "TI_DEGRADE" 2 "TI_DISPO_DEM" 3 "DEMARRAGE" 4 "REDEMARRAGE" 5 "TA_NOMINAL" 6 "TA_DEGRADE" 7 "TA_SECU" 8 "Réservé" 9 "Réservé" 10 "Réservé" 11 "Réservé" 12 "Réservé" 13 "Réservé" 14 "Réservé" 15 "Réservé" ;
VAL_ 1074 CONSOM_SENSIBLE 0 "Pas de consommateur électrique véhicule prioritaire enclenché" 1 "Consommateur électrique véhicule prioritaire enclenché" ;
VAL_ 1074 REVEIL_PRE_PST_PPL 0 "Pas de demande" 1 "Demande" ;
VAL_ 1074 REVEIL_DDE_ETAT_BV 0 "Pas de demande de réveil" 1 "Demande de réveil" ;
VAL_ 1074 REVEIL_ANTICIPATION_ADC 0 "Pas de demande de réveil" 1 "Demande de réveil" ;
VAL_ 1074 SEV_DEM 0 "Réservé" 1 "Pas de volonté de démarrage" 2 "Volonté démarrage" 3 "Réservé" ;
VAL_ 1074 PUSH_PWT_ECO 0 "Mode éco non demandé" 1 "Mode éco demandé" ;
VAL_ 1074 REVEIL_PREPA_DEM_MOT 0 "Pas de demande de réveil" 1 "Demande de réveil" ;
VAL_ 1074 REVEIL_PRECHAUF_FLEX 0 "Pas de demande de réveil" 1 "Demande de réveil" ;
VAL_ 1074 REVEIL_CORRECT_HAUT_PNEU 0 "Pas de demande de réveil" 1 "Demande de réveil" ;
VAL_ 1074 REVEIL_DDE_ETAT_FSE 0 "Pas de demande de réveil" 1 "Demande de réveil" ;
VAL_ 1074 HADC_ENABLE_REQ 0 "Pas de demande d'activation" 1 "Demande d'activation HADC" ;
VAL_ 1074 MECATRONIC_HEADLAMP_REQ 0 "OFF" 1 "ON" ;
VAL_ 1106 CHKSUM_CONS_RVV_LVV2 0 "quartet poids fort CONS_LIM_VITESSE_VEH est paire ET quartet poids faible CONS_LIM_VITESSE_VEH est paire" 1 "quartet poids fort CONS_LIM_VITESSE_VEH est paire ET quartet poids faible CONS_LIM_VITESSE_VEH est impaire" 2 "quartet poids fort CONS_LIM_VITESSE_VEH est impaire ET quartet poids faible CONS_LIM_VITESSE_VEH est paire" 3 "quartet poids fort CONS_LIM_VITESSE_VEH est impaire ET quartet poids faible CONS_LIM_VITESSE_VEH est impaire" ;
VAL_ 1106 TYPE_REGUL_LONGI 0 "Aucune" 1 "RVV : régulateur de vitesse véhicule" 2 "LVV : limiteur de vitesse véhicule" 3 "ACC : régulateur de vitesse véhicule automatique" ;
VAL_ 1106 ETAT_CLIGNOTANTS 0 "Clignotant inactif" 1 "Clignotant droit actif" 2 "Clignotant gauche actif" 3 "Clignotant gauche et clignotant droit actifs" ;
VAL_ 1106 FREIN_SEUL_DMD_BSI 0 "Pas de frein seul demandé par BSI" 1 "Frein seul demandé par BSI" ;
VAL_ 1106 COCKPIT_GO_ACC_REQUEST 0 "VALUE_1" 1 "VALUE_2" ;
VAL_ 1106 ARC_SENSIBILITE_HAB 0 "Valeur non utilisée" 1 "1" 2 "2" 3 "3" 4 "Valeur non utilisée" 5 "Valeur non utilisée" 6 "Valeur non utilisée" 7 "Valeur non utilisée" ;
VAL_ 1106 ETAT_ESSUYAGE_AV 0 "Arrèt" 1 "Essuyage AV confirmé" 2 "Petite vitesse" 3 "Grande vitesse" ;
VAL_ 1106 ETAT_LAVAGE_AV 0 "Arrêt" 1 "Lavage" ;
VAL_ 1106 DDE_ACTIVATION_LVV 0 "Pas de demande d'activation de la LVV" 1 "Demande d'activation de la LVV" ;
VAL_ 1106 DDE_ACTIVATION_RVV_ACC 0 "Pas de demande d'activation de la RVV ou ACC" 1 "Demande d'activation de la RVV ou ACC" ;
VAL_ 1106 PROGRAMME_ACC 0 "Confort" 1 "Sport" 2 "Eco" 3 "Réservé" ;
VAL_ 1106 FA_DMD_ACTIV_HAB 0 "désactivation" 1 "activation" ;
VAL_ 1106 ARC_DMD_ACTIV_HAB 0 "desactivation ARC" 1 "activation ARC" ;
VAL_ 1160 PREPARE_BOUGIES_PRE 0 "Aucune préparation requise" 1 "Préparation requise pour l activation des bougies de préchauffage" ;
VAL_ 1160 DDE_ALLUM_VOY_MLGE_PVRE 0 "Mélange correct" 1 "Mélange trop pauvre" ;
VAL_ 1160 REQ_LAMPE_MIL 0 "Pas d'allumage demandé" 1 "Allumage demandé" ;
VAL_ 1160 COUP_CLIM_SECU 0 "OK pas de coupure" 1 "Compresseur coupé (risque d'aggravation de surchauffe uniquement)" ;
VAL_ 1160 ALERTE_NIV_MIN_ADDITIF 0 "Aucune commande d'affichage du mini additif" 1 "Commande d'affichage du min additif" ;
VAL_ 1160 REQ_LAMPE_PRECH 0 "Pas d'allumage demandé" 1 "Allumage demandé" ;
VAL_ 1160 ALRT_TEMP_EAU 0 "Pas d'alerte de température d'eau moteur" 1 "Alerte de température d'eau moteur ou défaut sonde de température d'eau moteur" ;
VAL_ 1160 FORCAGE_PRESSION_BVA 0 "Pas de demande d'augmentation de pression" 1 "Demande d'augmentation de pression" ;
VAL_ 1160 DEFAUT_RVV_LVV 0 "Pas de défaut RVV / Pas de défaut LVV" 1 "Défaut RVV / Défaut LVV" ;
VAL_ 1160 ETAT_GESTION_CLIM 0 "OK" 1 "Sécurité basse active : pression anormalement basse" 2 "Sécurité haute active : pression anormalement élevée" 3 "Invalide" ;
VAL_ 1160 DEM_EN_COURS 0 "Pas de démarrage en cours" 1 "Démarrage en cours" ;
VAL_ 1160 RISQUE_COLMATAGE_FAP 0 "Aucune commande d'affichage du risque de colmatage" 1 "Commande d'affichage incitant le conducteur à adopter une conduite facilitant la régénération du" ;
VAL_ 1160 DMD_GMP_CLIGNO_STOP_SVCE 0 "Pas de demande" 1 "Demande" 2 "Réservé" 3 "Indisponible" ;
VAL_ 1160 RATES_COMBUSTION 0 "Pas de forts ratés" 1 "Forts ratés en cours" ;
VAL_ 1160 TYPE_INFO_CONSO_CARB 0 "Consommation réelle" 1 "Pseudo consommation" ;
VAL_ 1166 ETAT_MEAP_2 0 "Indisponible" 1 "MEAP sans mouvement" 2 "MEAP en mouvement" 3 "MEAP en référencement" 4 "Non utilisé" 5 "Non utilisé" 6 "Non utilisé" 7 "MEAP défaillant" ;
VAL_ 1166 POS_MEAP_2_ACT 0 "Indisponible" 1 "Position 0" 2 "Position 1" 3 "Position 2" 4 "Position 3" 5 "Position 4" 6 "Position 5" 7 "Position 6" 8 "Position 7" 9 "Position 8" 10 "Position 9" 11 "Position 10" 12 "Non utilisée" 13 "Non utilisée" 14 "Non utilisée" 15 "Position inconnue" ;
VAL_ 1261 D_OBD_ESP_CAN_LAS 0 "pas de defaut" 1 "défaut présent" ;
VAL_ 1261 D_OBD_ESP_CVR_ARD 0 "pas de defaut" 1 "défaut présent" ;
VAL_ 1261 D_OBD_ESP_CAN_IS 0 "pas de defaut" 1 "défaut présent" ;
VAL_ 1261 D_OBD_ESP_CONTACT_FREIN 0 "pas de defaut" 1 "défaut présent" ;
VAL_ 1261 D_OBD_ESP_SURTENSION 0 "pas de defaut" 1 "défaut présent" ;
VAL_ 1261 D_OBD_ESP_CAPT_MASTERVAC 0 "pas de defaut" 1 "défaut présent" ;
VAL_ 1261 D_OBD_ESP_POMPE_ESP 0 "pas de defaut" 1 "défaut présent" ;
VAL_ 1261 D_OBD_ESP_EV_ESP 0 "pas de defaut" 1 "défaut présent" ;
VAL_ 1261 D_OBD_ESP_COM_CMM 0 "pas de defaut" 1 "défaut présent" ;
VAL_ 1261 D_OBD_ESP_COM_TRICAPT 0 "pas de defaut" 1 "défaut présent" ;
VAL_ 1261 D_OBD_ESP_F_CAPT_PRESS 0 "pas de defaut" 1 "défaut présent" ;
VAL_ 1261 D_OBD_ESP_CAPT_MAIT_CYL 0 "pas de defaut" 1 "défaut présent" ;
VAL_ 1261 D_OBD_ESP_CAPT_VOLANT 0 "pas de defaut" 1 "défaut présent" ;
VAL_ 1261 D_OBD_ESP_CAPT_INERT 0 "pas de defaut" 1 "défaut présent" ;
VAL_ 1261 D_OBD_ESP_CAPT_VIT_ROUE 0 "pas de defaut" 1 "défaut présent" ;
VAL_ 1261 D_OBD_ESP_CVR_ARG 0 "pas de defaut" 1 "défaut présent" ;
VAL_ 1261 ACTIV_DIAG_PANNE_VIDE 0 "Diagnostic non activé" 1 "Diagnostic activé" ;
VAL_ 1261 DIAG_PANNE_VIDE 0 "Pas de panne détectée" 1 "Panne durable détectée" ;
VAL_ 1261 DEFAUT_CAPT_ACCEL_LAT_RB 0 "Pas de défaut" 1 "Défaut capteur accélération latérale" ;
VAL_ 1261 DEFAUT_CAPT_VITESSE_LACET_RB 0 "Pas de défaut" 1 "Défaut capteur vitesse de lacet" ;
VAL_ 1261 D_OBD_ESP_CVR_AVD 0 "pas de defaut" 1 "défaut présent" ;
VAL_ 1261 D_OBD_ESP_CVR_AVG 0 "pas de defaut" 1 "défaut présent" ;
VAL_ 1261 D_OBD_ESP_S_POMPE_VIDE 0 "pas de defaut" 1 "défaut présent" ;
VAL_ 1261 D_OBD_ESP_TELECODAGE 0 "pas de defaut" 1 "défaut présent" ;
VAL_ 1261 D_OBD_ESP_ERREUR_INT 0 "pas de defaut" 1 "défaut présent" ;
VAL_ 1261 D_OBD_ESP_COM_CAPT_VOL 0 "pas de defaut" 1 "défaut présent" ;
VAL_ 1261 D_OBD_ESP_COM_PTMU 0 "pas de defaut" 1 "défaut présent" ;
VAL_ 1266 TYPE_ESTIMATEUR_BATT 0 "Aucun" 1 "Estimateur_etat_batt_reveil" 2 "BECB" 3 "Réservé" ;
VAL_ 1266 GRAV_ER_TENSION_MIN 0 "Gravité 2" 1 "Gravité 3" 2 "Gravité 4" 3 "Réservé" ;
VAL_ 1266 I_RECHARGE_UCAP_AUTOR 0 "Consigne à 0A" 1 "Consigne à 10A" 2 "Consigne à 28A" 3 "Réservé" ;
VAL_ 1266 DMD_MEAP_CLIM 0 "Pas de demande" 1 "Demande" ;
VAL_ 1266 STATUS_SOC 0 "Estimation SOC nominale" 1 "Estimation SOC dégradée" 2 "En défaut" 3 "Estimation SOC non pertinente" ;
VAL_ 1266 GRAV_ER_TENSION_MAX 0 "Gravité 2" 1 "Gravité 3" 2 "Gravité 4" 3 "Réservé" ;
VAL_ 1266 POS_MEAP_ACT 0 "MEAP bloqué ouvert" 1 "MEAP ouvert" 2 "MEAP fermé" 3 "MEAP défaillant" ;
VAL_ 1266 DMD_AUGM_RAL_MTH_TC 0 "Pas de demande" 1 "Demande d'augmentation" ;
VAL_ 1266 UB_POS_MEAP_ACT 0 "signal non rafraichi" 1 "signal rafraichi" ;
VAL_ 1270 ETAT_CAPTEUR_ARTIV 0 "Initialisation" 1 "Inactif" 2 "Actif" 3 "Visibilité réduite" 4 "Simulation" 5 "Apprentissage" 6 "Libre" 7 "Défaut" ;
VAL_ 1270 CIBLE_DETECTEE 0 "initialisation ou pas de cible détectée" 1 "cible détectée" ;
VAL_ 1270 SENS_CIRCU 0 "droite" 1 "gauche" 2 "réservé" 3 "indéterminé" ;
VAL_ 1270 INFO_CHGT_CIBLE_ARTIV 0 "VALEUR_1" 1 "VALEUR_2" ;
VAL_ 1277 OVF_DOWN 0 "Overflow down inactif" 1 "Overflow down actif" ;
VAL_ 1277 DEFAUT_MOLETTE 0 "Pas de défaut" 1 "Cohérence non diagnostiquée" 2 "Valeur réservée" 3 "Défaut" ;
VAL_ 1277 OVF_UP 0 "Overfow Up inactif" 1 "Overflow Up actif" ;
VAL_ 1294 TYPE_REGUL_LONGI 0 "Aucune" 1 "RVV : régulateur de vitesse véhicule" 2 "LVV : limiteur de vitesse véhicule" 3 "ACC : régulateur de vitesse véhicule automatique" ;
VAL_ 1294 CHKSUM_CONS_RVV_LVV 0 "quartet poids fort CONS_LIM_VITESSE_VEH est paire ET quartet poids faible CONS_LIM_VITESSE_VEH est paire" 1 "quartet poids fort CONS_LIM_VITESSE_VEH est paire ET quartet poids faible CONS_LIM_VITESSE_VEH est impaire" 2 "quartet poids fort CONS_LIM_VITESSE_VEH est impaire ET quartet poids faible CONS_LIM_VITESSE_VEH est paire" 3 "quartet poids fort CONS_LIM_VITESSE_VEH est impaire ET quartet poids faible CONS_LIM_VITESSE_VEH est impaire" ;
VAL_ 1294 ETAT_EMB_COMP 0 "Compresseur débrayé" 1 "Compresseur embrayé" ;
VAL_ 1294 FORCAGE_ENCL_BOUGIES 0 "Forçage non autorisé" 1 "Forçage bougies préchauffage autorisé" ;
VAL_ 1294 DEF_IDENT_HAB 0 "pas de de défaut" 1 "défaut" ;
VAL_ 1294 DDE_REDEM_MOT_HAB 0 "pas de demande" 1 "demande coupure" 2 "demande redémarrage" 3 "demande redémarrage immédiat" ;
VAL_ 1294 DDE_REDEM_HAB 0 "Pas de besoin de redémarrage" 1 "Demande de redémarrage" ;
VAL_ 1294 NIV_DELESTAGE_SEV 0 "Pas de demande de délestage" 1 "Demande de délestage" ;
VAL_ 1294 DDE_ACTIVATION_LVV 0 "Pas de demande d'activation de la LVV" 1 "Demande d'activation de la LVV" ;
VAL_ 1294 INTERD_ARRET_HAB 0 "interdiction arrêt durée indéterminée" 1 "autorisation arrêt" 2 "interdiction arrêt durée moyenne" 3 "interdiction arrêt durée longue" ;
VAL_ 1294 AUTOR_ARRET_MOT_HAB 0 "Pas d'autorisation de stop" 1 "Autorisation de stop" ;
VAL_ 1294 DDE_ACTIVATION_RVV_ACC 0 "Pas de demande d'activation de la RVV ou ACC" 1 "Demande d'activation de la RVV ou ACC" ;
VAL_ 1294 MINI_GPL 0 "Niveau supérieur au minimum" 1 "Niveau minimum atteint" ;
VAL_ 1294 DDE_HABITACLE_SG 0 "Pas de demande spécifique(on reste en l'état)" 1 "Besoin rotation moteur thermique" ;
VAL_ 1294 PRES_COND 0 "Valeur interdite" 1 "Conducteur absent" 2 "Conducteur présent" 3 "Valeur interdite" ;
VAL_ 1294 CONSIGNE_GMV 0 "Aucune Consigne" 1 "Consigne GMV Petite Vitesse" 2 "Consigne GMV Moyenne Vitesse" 3 "Consigne GMV Grande Vitesse" ;
VAL_ 1330 AVN_OP_CTRL 0 "OFF" 1 "ON" ;
VAL_ 1330 AVN_OBJ_DET_CTRL 0 "DETECT_OFF" 1 "DETECT_ON" ;
VAL_ 1356 AVN_PEDESTRIAN_STATE 0 "OFF" 1 "ON" ;
VAL_ 1356 AVN_STATE 0 "OFF" 1 "INIT" 2 "DET_ON" 3 "DET_OFF" 4 "DEFAUT" 5 "ALIGN" 6 "RESERVED" 7 "RESERVED" ;
VAL_ 1356 AVN_DETECT_PEDESTRIAN 0 "NO_PEDESTRIAN" 1 "PEDESTRIAN_CORIDOR" 2 "PEDESTRIAN_CORNER" 3 "UNAVAILABLE" ;
VAL_ 1356 AVN_DETECT_ANIMAL 0 "NO_ANIMAL" 1 "ANIMAL_STILL_CONE" 2 "ANIMAL_MVT_CONE" 3 "UNAVAILABLE" ;
VAL_ 1375 DATA_ACQ_JDD_BSI_2 1 "Utilisé pour identifier le code station MUX" 2 "Utilisé pour identifier le code station MUX" 4 "Utilisé pour identifier le code station MUX" 16 "Utilisé pour identifier le code station MUX" 32 "Utilisé pour identifier le code station MUX" 64 "Utilisé pour identifier le code station MUX" 128 "Utilisé pour identifier le code station MUX" ;
VAL_ 1389 PTR_INFO_TRICPT_RB 0 "Numéro de série" 1 "Numéro de pièce client" 2 "Numéro de pièce Bosch" 3 "Indice modification véhicule" 4 "Version de logiciel capteur" 5 "Identification logiciel capteur" 6 "Version hardware capteur" 7 "Date de fabrication" 8 "Indice de modification Bosch" 9 "Nom du fabricant" 10 "Indice de process fabricant" 11 "Réservé" 12 "Réservé" 13 "Réservé" 14 "Réservé" 15 "Envoi de tous les blocs d'infos valides (0000 à 1010)" ;
VAL_ 1389 ACTIV_INFO_TRICPTR_RB 0 "Pas de demande d'informations capteur" 1 "Demande d'informations capteur" ;
VAL_ 1389 CPT_INCR_CONTACT_RB 0 "Pas de demande d'incrémentation compteur interne capteur" 1 "Demande d'incrémentation compteur interne capteur" ;
VAL_ 1393 ETAT_AVERT_SON_VEH_SIL 0 "Non inhibé" 1 "Inhibé" ;
VAL_ 1393 DIAG_AVERT_SON_VEH_SIL 0 "Pas de défaut" 1 "Défaut" ;
VAL_ 1400 ETAT_GMP_DYN 0 "Normal" 1 "Sport" 2 "Eco" 3 "Neige" 4 "Invalide" 5 "Réservé" 6 "Réservé" 7 "Réservé" ;
VAL_ 1400 BRK_ASSIST_GMP_LAMP_REQ 0 "Pas de demande d'allumage" 1 "Demande d'allumage lampe défaut" ;
VAL_ 1400 CMD_MEAP_2 0 "Indisponible" 1 "Position 0" 2 "Position 1" 3 "Position 2" 4 "Position 3" 5 "Position 4" 6 "Position 5" 7 "Position 6" 8 "Position 7" 9 "Position 8" 10 "Position 9" 11 "Position 10" 12 "Non utilisée" 13 "Non utilisée" 14 "Référencement" 15 "Mouvement stoppé" ;
VAL_ 1400 CMM_OPEN_SOLENOID_REQ 0 "Pas de demande" 1 "Demande d'ouverture" ;
VAL_ 1401 PTR_INFO_TRICPT_RB 0 "Numéro de série" 1 "Numéro de pièce client" 2 "Numéro de pièce Bosch" 3 "Indice modification véhicule" 4 "Version de logiciel capteur" 5 "Identification logiciel capteur" 6 "Version hardware capteur" 7 "Date de fabrication" 8 "Indice de modification Bosch" 9 "Nom du fabricant" 10 "Indice de process fabricant" 11 "Réservé" 12 "Réservé" 13 "Réservé" 14 "Réservé" 15 "Envoi de tous les blocs d'infos valides (0000 à 1010)" ;
VAL_ 1401 TYPE_CAPT_RB 0 "Réservé" 1 "MM 3.7K" 2 "MM 3.8K" 3 "Réservé" 4 "Réservé" 5 "Réservé" 6 "Réservé" 7 "Réservé" 8 "Réservé" 9 "Réservé" 10 "Réservé" 11 "Réservé" 12 "Réservé" 13 "Réservé" 14 "Réservé" 15 "Réservé" ;
VAL_ 1426 REQ_CLIM_POMPE_AERO_HYB 0 "Inactive" 1 "Actif" ;
VAL_ 1426 DETECTION_ARTIV_DEM 0 "Initialisation ou détection non demandée" 1 "Détection demandée" 2 "Simulation" 3 "Invalide" ;
VAL_ 1426 CALIBRE_IBATT 0 "[-1A ; +1A]" 1 "[-200A ; +200A]" 2 "[-1500A ; +1500A]" 3 "Invalide" ;
VAL_ 1426 ETAT_ESSUYAGE 0 "Arrèt" 1 "Réservé" 2 "Petite vitesse" 3 "Grande vitesse" ;
VAL_ 1426 CMD_HDC_ESSUIE_AV 0 "Pas de commande" 1 "Automatique (avec CDPL) ou intermittent" 2 "Première vitesse(petite vitesse)" 3 "invalide" 4 "Deuxième vitesse (grande vitesse)" 5 "invalide" 6 "invalide" 7 "invalide" ;
VAL_ 1426 TYPE_PILT_ALTERN 0 "Pilotage autonome" 1 "Nominal" 2 "Augmentation production energie" 3 "Pilotage autonome contraint" 4 "réservé" 5 "réservé" 6 "Indisponible" 7 "Invalide" ;
VAL_ 1426 REQ_CLIM_DEBIT_AERO 0 "Besoin chauffage habitacle nul" 1 "Besoin chauffage habitacle faible" 2 "Besoin chauffage habitacle modéré" 3 "Besoin chauffage habitacle important" ;
VAL_ 1426 DMD_CHANGEMENT_ETAT_STT 0 "Réservé" 1 "Pas de demande" 2 "Demande" 3 "En défaut" ;
VAL_ 1426 MODE_SERRAGE_FSE 0 "Frein de stationnement en mode serrage automatique" 1 "Frein de stationnement en mode serrage manuel" ;
VAL_ 1426 DEFAUT_SYST_COMMUT 0 "Pas de défaut détecté" 1 "Défaut détecté" ;
VAL_ 1426 DMD_RESET_DSGI 0 "Aucun Reset demandé" 1 "Reset demandé" ;
VAL_ 1448 OPTI_VACUUM_ON_BV 0 "0b0: Non activé" 1 "0b1: Activé" ;
VAL_ 1448 ALRT_NIV_UREE 0 "Niveau haut" 1 "Niveau bas seuil1" 2 "Niveau bas seuil2" 3 "Niveau bas seuil3" 4 "Niveau bas nul" 5 "réservées" 6 "réservées" 7 "réservées" ;
VAL_ 1448 PWT_MODE_EMISSION_REQ 0 "Nominal" 1 "Prioriser la réduction des Nox à la source (mode d'initialisation) / la richesse en O2 (Essence)" 2 "Prioriser le débit échappement" 3 "Prioriser la thermique échappement" 4 "reservé" 5 "reservé" 6 "reservé" 7 "reservé" ;
VAL_ 1448 ETAT_DIAG_SCR 0 "Système SCR fonctionnel" 1 "Système SCR défaillant Confirmation" 2 "Système SCR défaillant Seuil" 3 "Système SCR défaillant 0" ;
VAL_ 1464 NOTE_ECOACH_SLOPE 0 "Note 0" 1 "Note 1" 2 "Note 2" 3 "Note 3" 4 "Note 4" 5 "Note 5" 6 "Note 6" 7 "Note 7" 8 "Note 8" 9 "Note 9" 10 "Note 10" 11 "non utilisé" 12 "non utilisé" 13 "non utilisé" 14 "Note indisponible" 15 "Invalide" ;
VAL_ 1464 NOTE_ECOACH_SPEED 0 "Note 0" 1 "Note 1" 2 "Note 2" 3 "Note 3" 4 "Note 4" 5 "Note 5" 6 "Note 6" 7 "Note 7" 8 "Note 8" 9 "Note 9" 10 "Note 10" 11 "non utilisé" 12 "non utilisé" 13 "non utilisé" 14 "Note indisponible" 15 "Invalide" ;
VAL_ 1464 NOTE_GLOBAL_ECOACH_DAY 0 "Note 0" 1 "Note 1" 2 "Note 2" 3 "Note 3" 4 "Note 4" 5 "Note 5" 6 "Note 6" 7 "Note 7" 8 "Note 8" 9 "Note 9" 10 "Note 10" 11 "non utilisé" 12 "non utilisé" 13 "non utilisé" 14 "Note indisponible" 15 "Invalide" ;
VAL_ 1464 NOTE_GLOBAL_ECOACH_TRIP 0 "Note 0" 1 "Note 1" 2 "Note 2" 3 "Note 3" 4 "Note 4" 5 "Note 5" 6 "Note 6" 7 "Note 7" 8 "Note 8" 9 "Note 9" 10 "Note 10" 11 "non utilisé" 12 "non utilisé" 13 "non utilisé" 14 "Note indisponible" 15 "Invalide" ;
VAL_ 1464 NOTE_ECOACH_ACCEL 0 "Note 0" 1 "Note 1" 2 "Note 2" 3 "Note 3" 4 "Note 4" 5 "Note 5" 6 "Note 6" 7 "Note 7" 8 "Note 8" 9 "Note 9" 10 "Note 10" 11 "non utilisé" 12 "non utilisé" 13 "non utilisé" 14 "Note indisponible" 15 "Invalide" ;
VAL_ 1464 NOTE_ECOACH_BRAKE 0 "Note 0" 1 "Note 1" 2 "Note 2" 3 "Note 3" 4 "Note 4" 5 "Note 5" 6 "Note 6" 7 "Note 7" 8 "Note 8" 9 "Note 9" 10 "Note 10" 11 "non utilisé" 12 "non utilisé" 13 "non utilisé" 14 "Note indisponible" 15 "Invalide" ;
VAL_ 1464 NOTE_ECOACH_CLIM 0 "Note 0" 1 "Note 1" 2 "Note 2" 3 "Note 3" 4 "Note 4" 5 "Note 5" 6 "Note 6" 7 "Note 7" 8 "Note 8" 9 "Note 9" 10 "Note 10" 11 "non utilisé" 12 "non utilisé" 13 "non utilisé" 14 "Note indisponible" 15 "Invalide" ;
VAL_ 1464 NOTE_ECOACH_DSG 0 "Note 0" 1 "Note 1" 2 "Note 2" 3 "Note 3" 4 "Note 4" 5 "Note 5" 6 "Note 6" 7 "Note 7" 8 "Note 8" 9 "Note 9" 10 "Note 10" 11 "non utilisé" 12 "non utilisé" 13 "non utilisé" 14 "Note indisponible" 15 "Invalide" ;
VAL_ 1464 NOTE_ECOACH_GSI 0 "Note 0" 1 "Note 1" 2 "Note 2" 3 "Note 3" 4 "Note 4" 5 "Note 5" 6 "Note 6" 7 "Note 7" 8 "Note 8" 9 "Note 9" 10 "Note 10" 11 "non utilisé" 12 "non utilisé" 13 "non utilisé" 14 "Note indisponible" 15 "Invalide" ;
VAL_ 1464 NOTE_ECOACH_COLD_ENGINE 0 "Note 0" 1 "Note 1" 2 "Note 2" 3 "Note 3" 4 "Note 4" 5 "Note 5" 6 "Note 6" 7 "Note 7" 8 "Note 8" 9 "Note 9" 10 "Note 10" 11 "non utilisé" 12 "non utilisé" 13 "non utilisé" 14 "Note indisponible" 15 "Invalide" ;
VAL_ 1464 NOTE_ECOACH_STT 0 "Note 0" 1 "Note 1" 2 "Note 2" 3 "Note 3" 4 "Note 4" 5 "Note 5" 6 "Note 6" 7 "Note 7" 8 "Note 8" 9 "Note 9" 10 "Note 10" 11 "non utilisé" 12 "non utilisé" 13 "non utilisé" 14 "Note indisponible" 15 "Invalide" ;
VAL_ 1484 CODE_DEFAUT 0 "aucun defaut present" 1 "Un ou plusieurs defauts presents. Chaque bit donne un code defaut" ;
VAL_ 1484 ETAT_ELECTR_UCE 0 "Veille (theorique car jamais atteint)" 1 "Partiel ou ComLatch" 2 "Partiel interne (theoriquement non utilise)" 3 "Transitoire" 4 "Principal" 5 "Principal degrade" 6 "Init / Endormissement" 7 "Valeur par defaut (absence fonction)" 8 "Pre/Post Principal" 9 "Réservé" 10 "Réservé" 11 "Réservé" 12 "Réservé" 13 "Réservé" 14 "Réservé" 15 "Réservé" ;
VAL_ 1484 STATUS_REVEIL_PARTIEL_GMP 0 "Valeur a l initialisation" 1 "Etat reveil preparation GEP BV" 2 "Etat reveil preparation Stop & Start avec AR2S (type C3)" 4 "Etat reveil charge/decharge Ucaps" 8 "Etat reveil overload vehicle indicator" 16 "Etat reveil mecatronic headlamp" 32 "Reserve" 64 "Etat reveil Anticipation ADC" 128 "Etat reveil preparation demarrage moteur" 256 "Reserve" 512 "Etat reveil demande etat BV" 1024 "Reserve" 2048 "Etat reveil purge SCR" 4096 "Etat reveil Flex Start" 8192 "Etat reveil Power-latch HY" 16384 "Etat reveil mesures huile moteur" 32768 "Etat reveil post ventilation moteur" ;
VAL_ 1489 CODE_DEFAUT 0 "aucun defaut present" 1 "Un ou plusieurs defauts presents. Chaque bit donne un code defaut" ;
VAL_ 1489 ETAT_ELECTR_UCE 0 "Veille (theorique car jamais atteint)" 1 "Partiel ou ComLatch" 2 "Partiel interne (theoriquement non utilise)" 3 "Transitoire" 4 "Principal" 5 "Principal degrade" 6 "Init / Endormissement" 7 "Valeur par defaut (absence fonction)" 8 "Pre/Post Principal" 9 "Réservé" 10 "Réservé" 11 "Réservé" 12 "Réservé" 13 "Réservé" 14 "Réservé" 15 "Réservé" ;
VAL_ 1489 STATUS_REVEIL_PARTIEL_LAS 0 "Valeur a l initialisation" 1 "Etat reveil correction de hauteur" 2 "Etat reveil fonction manuelle CAAR" 4 "Reveil demande état hauteur CAAR par FSE" 8 "Reveil fonction Easymove par FSE" 16 "Reveil vitesse vehicule par BSI" 32 "Reveil affichage par FSE" 64 "Reveil demande etat FSE" 128 "Reveil partiel court 1 post reveil principal" ;
VAL_ 1490 RESET_ECOACH_TRIP 0 "pas de demande de reset" 1 "demande de reset" ;
VAL_ 1490 RESET_ECOACH_DAY 0 "pas de demande de reset" 1 "demande de reset" ;
VAL_ 1490 REQ_PUISS_BT_AUX 0 "Niveau 0" 1 "Niveau 1" 2 "Niveau 2" 3 "Niveau 3" 4 "Niveau 4" 5 "Niveau 5" 6 "Niveau 6" 7 "Niveau 7" 8 "Niveau 8" 9 "Niveau 9" 10 "Niveau 10" 11 "Niveau 11" 12 "Niveau 12" 13 "Niveau 13" 14 "Niveau 14" 15 "Niveau 15" ;
VAL_ 1490 REQ_CLIM_CHAUFF_EAU_MOT 0 "Pas de demande" 1 "Demande niveau 1" 2 "Demande niveau 2" 3 "Demande niveau 3" ;
VAL_ 1490 ETAT_MA 0 "Marche arrière non enclenchée" 1 "Marche arrière enclenchée" ;
VAL_ 1490 CMD_AVER_SON_VEH_SIL 0 "Non activé" 1 "Activé" ;
VAL_ 1496 KM_MARKETING_ETD_ACTIF 0 "utilisation de SEUIL_KM_MARKETING" 1 "utilisation de SEUIL_KM_MARKETING_ETD" ;
VAL_ 1516 TYPE_MESSAGE 0 "Calculateur reconduit AEE2004" 1 "Calculateur répondant à l'AEE2010" ;
VAL_ 1516 ETAT_DTC 0 "Passage de défaut PERMANENT à défaut FUGITIF (non détection d'une défaillance auparavant confir" 1 "Passage du défaut à PERMANENT" ;
VAL_ 1516 NUMERO_TRAME 0 "Réservé" 1 "Trame numéro 1" 2 "Trame numéro 2" 3 "Trame numéro 3" ;
VAL_ 1516 NOMBRE_TRAMES 0 "Réservé" 1 "Une trame" 2 "Deux trames" 3 "Trois trames" ;
VAL_ 1517 SMALL_SPAREWHL_DETECT 0 "Pas de 'petite roue de secours' detectée" 1 "'petite roue de secours' detectée" ;
VAL_ 1517 ETAT_IND_ROUE_ARD 0 "Réservé" 1 "Etat roue sous gonflée" 2 "Réservé" 3 "Réservé" 4 "Etat roue inconnue" 5 "Réservé" 6 "Réservé" 7 "Etat roue normale" ;
VAL_ 1517 ICB_STATE 0 "0b0: N0_FAULT" 1 "0b1: FAULT" ;
VAL_ 1517 ETAT_IND_ROUE_ARG 0 "Réservé" 1 "Etat roue sous gonflée" 2 "Réservé" 3 "Réservé" 4 "Etat roue inconnue" 5 "Réservé" 6 "Réservé" 7 "Etat roue normale" ;
VAL_ 1517 ETAT_IND_DSG 0 "Réservé" 1 "Etat DSG défaillant" 2 "Etat roue(s) sous gonflée(s)" 3 "Réservé" 4 "Acquittement de reinitialisation" 5 "Réservé" 6 "Réservé" 7 "Etat DSG Ok" ;
VAL_ 1517 ETAT_IND_ROUE_AVD 0 "Réservé" 1 "Etat roue sous gonflée" 2 "Réservé" 3 "Réservé" 4 "Etat roue inconnue" 5 "Réservé" 6 "Réservé" 7 "Etat roue normale" ;
VAL_ 1517 ETAT_IND_ROUE_AVG 0 "Réservé" 1 "Etat roue sous gonflée" 2 "Réservé" 3 "Réservé" 4 "Etat roue inconnue" 5 "Réservé" 6 "Réservé" 7 "Etat roue normale" ;
VAL_ 1518 SOLENOID_BLOCKED 0 "Pas de défaut" 1 "Défaut" ;
VAL_ 1519 TYPE_MESSAGE 0 "Calculateur reconduit AEE2004" 1 "Calculateur répondant à l'AEE2010" ;
VAL_ 1519 ETAT_DTC 0 "Passage de défaut PERMANENT à défaut FUGITIF (non détection d'une défaillance auparavant confir" 1 "Passage du défaut à PERMANENT" ;
VAL_ 1519 NUMERO_TRAME 0 "Réservé" 1 "Trame numéro 1" 2 "Trame numéro 2" 3 "Trame numéro 3" ;
VAL_ 1519 NOMBRE_TRAMES 0 "Réservé" 1 "Une trame" 2 "Deux trames" 3 "Trois trames" ;
VAL_ 1520 CODE_DEFAUT 0 "aucun defaut present" 1 "Un ou plusieurs defauts presents. Chaque bit donne un code defaut" ;
VAL_ 1520 ETAT_ELECTR_UCE 0 "Veille (theorique car jamais atteint)" 1 "Partiel ou ComLatch" 2 "Partiel interne (theoriquement non utilise)" 3 "Transitoire" 4 "Principal" 5 "Principal degrade" 6 "Init / Endormissement" 7 "Valeur par defaut (absence fonction)" 8 "Pre/Post Principal" 9 "Réservé" 10 "Réservé" 11 "Réservé" 12 "Réservé" 13 "Réservé" 14 "Réservé" 15 "Réservé" ;
VAL_ 1520 STATUS_REVEIL_PARTIEL_LAS 0 "Valeur a l initialisation" 1 "Etat reveil correction de hauteur" 2 "Etat reveil fonction manuelle CAAR" 4 "Reveil demande état hauteur CAAR par FSE" 8 "Reveil fonction Easymove par FSE" 16 "Reveil vitesse vehicule par BSI" 32 "Reveil affichage par FSE" 64 "Reveil demande etat FSE" 128 "Reveil partiel court 1 post reveil principal" ;
VAL_ 1521 TYPE_MESSAGE 0 "Calculateur reconduit AEE2004" 1 "Calculateur répondant à l'AEE2010" ;
VAL_ 1521 ETAT_DTC 0 "Passage de défaut PERMANENT à défaut FUGITIF (non détection d'une défaillance auparavant confir" 1 "Passage du défaut à PERMANENT" ;
VAL_ 1521 NUMERO_TRAME 0 "Réservé" 1 "Trame numéro 1" 2 "Trame numéro 2" 3 "Trame numéro 3" ;
VAL_ 1521 NOMBRE_TRAMES 0 "Réservé" 1 "Une trame" 2 "Deux trames" 3 "Trois trames" ;
VAL_ 1554 MODE_ECO 0 "Valeur d'initialisation" 1 "Pas de mode ECO" 2 "Mode ECO demandé" 3 "Invalide" ;
VAL_ 1554 CDE_CLG_ET_HDC 0 "Pas de commande" 1 "Clignotant Gauche" 2 "Clignotant Droit" 3 "Non valide" ;
VAL_ 1554 INH_ECLAIRAGE_VIRAGE_DYN 0 "Non inhibition" 1 "Inhibition" ;
VAL_ 1554 MODE_CONF_VEH 0 "Usine" 1 "Show room" 2 "Client" 3 "Réservé" ;
VAL_ 1554 INH_DIURNE_ECLRGE 0 "Pas d'inhibition" 1 "Inhibition" ;
VAL_ 1554 CONFIG_VHL 0 "Montage" 1 "Usine" 2 "Contrôle" 3 "Sockage/Transport" 4 "Client" 5 "APV" 6 "Show room" 7 "Invalide" ;
VAL_ 1554 INFO_REQ_OLVI_REAR_ACT 0 "Pas de demande" 1 "Demande" ;
VAL_ 1554 MODE_ASR_PLUS_SELECT 0 "Mode Normal" 1 "Mode Neige" 2 "Mode Boue" 3 "Mode Sable" ;
VAL_ 1554 POS_DEFLEC_MOBILE 0 "Indéterminé" 1 "En position 0" 2 "Réservé" 3 "En position 1" 4 "Réservé" 5 "En position 2" 6 "En position maintenance" 7 "Réservé" ;
VAL_ 1554 INH_ECLAIRAGE_AUTOROUTE 0 "Non inhibition" 1 "Inhibition" ;
VAL_ 1554 ETAT_FEUX_CROIST 0 "Eteints" 1 "Allumés" ;
VAL_ 1554 DEF_FEU_ROUTE_G 0 "Pas de défaut" 1 "Défaut" ;
VAL_ 1554 UB_D_LIGNE_REL_RX 0 "Pas de changement" 1 "Changement sur au moins un signal" ;
VAL_ 1554 D_LIGNE_REL_R3 0 "Indéterminé" 1 "Pas de défaut / Commande relais inactive" 2 "Pas de défaut / Commande relais active" 3 "CC à la masse" 4 "CC au +BAT" 5 "CO" 6 "Défaut non identifié" 7 "Valeur non utilisée" ;
VAL_ 1554 ETAT_FEUX_ROUTE 0 "Eteints" 1 "Allumés" ;
VAL_ 1554 DEF_FEU_CROISMNT_G 0 "Pas de défaut" 1 "Défaut" ;
VAL_ 1554 DEF_FEU_ROUTE_D 0 "Pas de défaut" 1 "Défaut" ;
VAL_ 1554 D_LIGNE_REL_R2 0 "Indéterminé" 1 "Pas de défaut / Commande relais inactive" 2 "Pas de défaut / Commande relais active" 3 "CC à la masse" 4 "CC au +BAT" 5 "CO" 6 "Défaut non identifié" 7 "Valeur non utilisée" ;
VAL_ 1554 D_LIGNE_REL_R1 0 "Indéterminé" 1 "Pas de défaut / Commande relais inactive" 2 "Pas de défaut / Commande relais active" 3 "CC à la masse" 4 "CC au +BAT" 5 "CO" 6 "Défaut non identifié" 7 "Valeur non utilisée" ;
VAL_ 1554 DEF_FEU_CROISMNT_D 0 "Pas de défaut" 1 "Défaut" ;
VAL_ 1910 TYPE_MESSAGE 0 "Calculateur reconduit AEE2004" 1 "Calculateur répondant à l'AEE2010" ;
VAL_ 1910 ETAT_DTC 0 "Passage de défaut PERMANENT à défaut FUGITIF (non détection d'une défaillance auparavant confir" 1 "Passage du défaut à PERMANENT" ;
VAL_ 1910 NUMERO_TRAME 0 "Réservé" 1 "Trame numéro 1" 2 "Trame numéro 2" 3 "Trame numéro 3" ;
VAL_ 1910 NOMBRE_TRAMES 0 "Réservé" 1 "Une trame" 2 "Deux trames" 3 "Trois trames" ;
VAL_ 1917 TYPE_MESSAGE 0 "Calculateur reconduit AEE2004" 1 "Calculateur répondant à l'AEE2010" ;
VAL_ 1917 ETAT_DTC 0 "Passage de défaut PERMANENT à défaut FUGITIF (non détection d'une défaillance auparavant confir" 1 "Passage du défaut à PERMANENT" ;
VAL_ 1917 NUMERO_TRAME 0 "Réservé" 1 "Trame numéro 1" 2 "Trame numéro 2" 3 "Trame numéro 3" ;
VAL_ 1917 NOMBRE_TRAMES 0 "Réservé" 1 "Une trame" 2 "Deux trames" 3 "Trois trames" ;
VAL_ 1938 CODE_DEFAUT 0 "aucun defaut present" 1 "Un ou plusieurs defauts presents. Chaque bit donne un code defaut" ;
VAL_ 1938 STATUS_REVEIL_PARTIEL 0 "Valeur a l initialisation" 1 "Etat reveil preparation GEP" 2 "Etat reveil preparation Stop & Start" 4 "Etat reveil fonction manuelle CAAR" 8 "Etat reveil correction de hauteur pneumatique" 16 "Etat reveil vitesse vehicule par BSI" 32 "Etat reveil vitesse vehicule par FSE" 64 "Etat reveil anticipation ADC" 128 "Etat reveil preparation demarrage moteur" 256 "Etat reveil preconditionnement habitacle" 512 "Etat reveil demande etat BV" 1024 "Etat reveil correction de hauteur" 2048 "Etat reveil demande état FSE" 4096 "Etat reveil affichage état FSE" 8192 "Etat reveil reception plip" 16384 "Etat reveil mesures huile moteur" 32768 "Etat reveil post ventilation moteur" ;
VAL_ 1938 ETAT_ELECTR_UCE 0 "Veille (theorique car jamais atteint)" 1 "Partiel ou ComLatch" 2 "Partiel interne (theoriquement non utilise)" 3 "Transitoire" 4 "Principal" 5 "Principal degrade" 6 "Init / Endormissement" 7 "Valeur par defaut (absence fonction)" 8 "Pre/Post Principal" 9 "Réservé" 10 "Réservé" 11 "Réservé" 12 "Réservé" 13 "Réservé" 14 "Réservé" 15 "Réservé" ;
VAL_ 1938 ETAT_LIGNE_RCD 0 "Ligne RCD à l'etat BAS" 1 "Ligne RCD à l'etat HAUT" ;
VAL_ 1942 CODE_DEFAUT 0 "aucun defaut present" 1 "Un ou plusieurs defauts presents. Chaque bit donne un code defaut" ;
VAL_ 1942 ETAT_ELECTR_UCE 0 "Veille (theorique car jamais atteint)" 1 "Partiel ou ComLatch" 2 "Partiel interne (theoriquement non utilise)" 3 "Transitoire" 4 "Principal" 5 "Principal degrade" 6 "Init / Endormissement" 7 "Valeur par defaut (absence fonction)" 8 "Pre/Post Principal" 9 "Réservé" 10 "Réservé" 11 "Réservé" 12 "Réservé" 13 "Réservé" 14 "Réservé" 15 "Réservé" ;
VAL_ 1942 STATUS_REVEIL_PARTIEL_GMP 0 "Valeur a l initialisation" 1 "Etat reveil preparation GEP BV" 2 "Etat reveil preparation Stop & Start avec AR2S (type C3)" 4 "Etat reveil charge/decharge Ucaps" 8 "Etat reveil overload vehicle indicator" 16 "Etat reveil mecatronic headlamp" 32 "Reserve" 64 "Etat reveil Anticipation ADC" 128 "Etat reveil preparation demarrage moteur" 256 "Reserve" 512 "Etat reveil demande etat BV" 1024 "Reserve" 2048 "Etat reveil purge SCR" 4096 "Etat reveil Flex Start" 8192 "Etat reveil Power-latch HY" 16384 "Etat reveil mesures huile moteur" 32768 "Etat reveil post ventilation moteur" ;
VAL_ 1949 CODE_DEFAUT 0 "aucun defaut present" 1 "Un ou plusieurs defauts presents. Chaque bit donne un code defaut" ;
VAL_ 1949 ETAT_ELECTR_UCE 0 "Veille (theorique car jamais atteint)" 1 "Partiel ou ComLatch" 2 "Partiel interne (theoriquement non utilise)" 3 "Transitoire" 4 "Principal" 5 "Principal degrade" 6 "Init / Endormissement" 7 "Valeur par defaut (absence fonction)" 8 "Pre/Post Principal" 9 "Réservé" 10 "Réservé" 11 "Réservé" 12 "Réservé" 13 "Réservé" 14 "Réservé" 15 "Réservé" ;
